VERSION "HNNBNNNYNNNNNNNNNNNNNNNNNNNNNNNNNNNNNNNNNN/4/%%%/4/'%**4NNN///"

NS_ :

BS_:

BU_: ABT_1_MIB_ab_Gen3 ABT_1_MQB BAP_Tester BT_1_MQB DU_1_MQB DU_2 DU_3 DU_4 ExBox Kombi_TT3 LSR_1 SCC1 SCC2 SDC1 SDC2 SFA TVTuner_ab_Gen3_JPN WLC_01 WLC_02 ZR_Entry ZR_High ZR_High_Korea ZR_High_TT3 ZR_MIB_OPTION_ab_Gen3 ZR_MIB_TOP_ab_Gen3 ZR_Standard

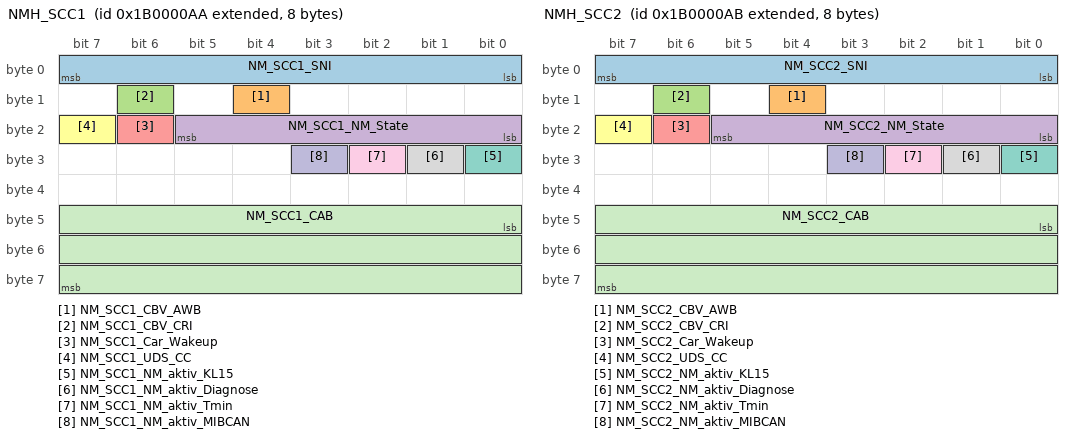
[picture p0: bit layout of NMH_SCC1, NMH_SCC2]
BO_ 2600468650 NMH_SCC1: 8 SCC1
 SG_ NM_SCC1_SNI : 0|8@1+ (1,0) [0|255] "" Vector__XXX
 SG_ NM_SCC1_CBV_AWB : 12|1@1+ (1,0) [0|1] "" Vector__XXX
 SG_ NM_SCC1_CBV_CRI : 14|1@1+ (1,0) [0|1] "" Vector__XXX
 SG_ NM_SCC1_NM_State : 16|6@1+ (1,0) [0|63] ""  ABT_1_MIB_ab_Gen3,ABT_1_MQB,BT_1_MQB,DU_1_MQB,DU_2,DU_3,DU_4,ExBox,Kombi_TT3,LSR_1,SCC1,SCC2,SDC1,SDC2,SFA,TVTuner_ab_Gen3_JPN,WLC_01,WLC_02,ZR_Entry,ZR_High,ZR_High_Korea,ZR_High_TT3,ZR_MIB_OPTION_ab_Gen3,ZR_MIB_TOP_ab_Gen3,ZR_Standard
 SG_ NM_SCC1_Car_Wakeup : 22|1@1+ (1,0) [0|1] "" Vector__XXX
 SG_ NM_SCC1_UDS_CC : 23|1@1+ (1,0) [0|1] "" Vector__XXX
 SG_ NM_SCC1_NM_aktiv_KL15 : 24|1@1+ (1,0) [0|1] "" Vector__XXX
 SG_ NM_SCC1_NM_aktiv_Diagnose : 25|1@1+ (1,0) [0|1] "" Vector__XXX
 SG_ NM_SCC1_NM_aktiv_Tmin : 26|1@1+ (1,0) [0|1] "" Vector__XXX
 SG_ NM_SCC1_NM_aktiv_MIBCAN : 27|1@1+ (1,0) [0|1] "" Vector__XXX
 SG_ NM_SCC1_CAB : 40|24@1+ (1,0) [0|16777215] "" Vector__XXX

BO_ 2600468651 NMH_SCC2: 8 SCC2
 SG_ NM_SCC2_SNI : 0|8@1+ (1,0) [0|255] "" Vector__XXX
 SG_ NM_SCC2_CBV_AWB : 12|1@1+ (1,0) [0|1] "" Vector__XXX
 SG_ NM_SCC2_CBV_CRI : 14|1@1+ (1,0) [0|1] "" Vector__XXX
 SG_ NM_SCC2_NM_State : 16|6@1+ (1,0) [0|63] ""  ABT_1_MIB_ab_Gen3,ABT_1_MQB,BT_1_MQB,DU_1_MQB,DU_2,DU_3,DU_4,ExBox,Kombi_TT3,LSR_1,SCC1,SCC2,SDC1,SDC2,SFA,TVTuner_ab_Gen3_JPN,WLC_01,WLC_02,ZR_Entry,ZR_High,ZR_High_Korea,ZR_High_TT3,ZR_MIB_OPTION_ab_Gen3,ZR_MIB_TOP_ab_Gen3,ZR_Standard
 SG_ NM_SCC2_Car_Wakeup : 22|1@1+ (1,0) [0|1] "" Vector__XXX
 SG_ NM_SCC2_UDS_CC : 23|1@1+ (1,0) [0|1] "" Vector__XXX
 SG_ NM_SCC2_NM_aktiv_KL15 : 24|1@1+ (1,0) [0|1] "" Vector__XXX
 SG_ NM_SCC2_NM_aktiv_Diagnose : 25|1@1+ (1,0) [0|1] "" Vector__XXX
 SG_ NM_SCC2_NM_aktiv_Tmin : 26|1@1+ (1,0) [0|1] "" Vector__XXX
 SG_ NM_SCC2_NM_aktiv_MIBCAN : 27|1@1+ (1,0) [0|1] "" Vector__XXX
 SG_ NM_SCC2_CAB : 40|24@1+ (1,0) [0|16777215] "" Vector__XXX

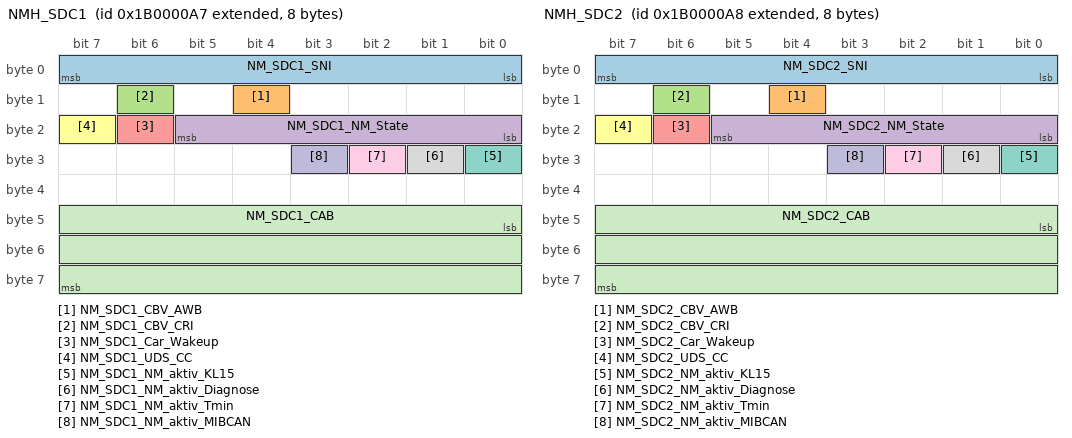
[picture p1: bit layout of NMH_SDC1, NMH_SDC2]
BO_ 2600468647 NMH_SDC1: 8 SDC1
 SG_ NM_SDC1_SNI : 0|8@1+ (1,0) [0|255] "" Vector__XXX
 SG_ NM_SDC1_CBV_AWB : 12|1@1+ (1,0) [0|1] ""  ZR_High
 SG_ NM_SDC1_CBV_CRI : 14|1@1+ (1,0) [0|1] "" Vector__XXX
 SG_ NM_SDC1_NM_State : 16|6@1+ (1,0) [0|63] ""  ABT_1_MIB_ab_Gen3,ABT_1_MQB,BT_1_MQB,DU_1_MQB,DU_2,DU_3,DU_4,ExBox,Kombi_TT3,LSR_1,SCC1,SCC2,SDC1,SDC2,SFA,TVTuner_ab_Gen3_JPN,WLC_01,WLC_02,ZR_Entry,ZR_High,ZR_High_Korea,ZR_High_TT3,ZR_MIB_OPTION_ab_Gen3,ZR_MIB_TOP_ab_Gen3,ZR_Standard
 SG_ NM_SDC1_Car_Wakeup : 22|1@1+ (1,0) [0|1] "" Vector__XXX
 SG_ NM_SDC1_UDS_CC : 23|1@1+ (1,0) [0|1] "" Vector__XXX
 SG_ NM_SDC1_NM_aktiv_KL15 : 24|1@1+ (1,0) [0|1] "" Vector__XXX
 SG_ NM_SDC1_NM_aktiv_Diagnose : 25|1@1+ (1,0) [0|1] "" Vector__XXX
 SG_ NM_SDC1_NM_aktiv_Tmin : 26|1@1+ (1,0) [0|1] "" Vector__XXX
 SG_ NM_SDC1_NM_aktiv_MIBCAN : 27|1@1+ (1,0) [0|1] "" Vector__XXX
 SG_ NM_SDC1_CAB : 40|24@1+ (1,0) [0|16777215] "" Vector__XXX

BO_ 2600468648 NMH_SDC2: 8 SDC2
 SG_ NM_SDC2_SNI : 0|8@1+ (1,0) [0|255] "" Vector__XXX
 SG_ NM_SDC2_CBV_AWB : 12|1@1+ (1,0) [0|1] ""  ZR_High
 SG_ NM_SDC2_CBV_CRI : 14|1@1+ (1,0) [0|1] "" Vector__XXX
 SG_ NM_SDC2_NM_State : 16|6@1+ (1,0) [0|63] ""  ABT_1_MIB_ab_Gen3,ABT_1_MQB,BT_1_MQB,DU_1_MQB,DU_2,DU_3,DU_4,ExBox,Kombi_TT3,LSR_1,SCC1,SCC2,SDC1,SDC2,SFA,TVTuner_ab_Gen3_JPN,WLC_01,WLC_02,ZR_Entry,ZR_High,ZR_High_Korea,ZR_High_TT3,ZR_MIB_OPTION_ab_Gen3,ZR_MIB_TOP_ab_Gen3,ZR_Standard
 SG_ NM_SDC2_Car_Wakeup : 22|1@1+ (1,0) [0|1] "" Vector__XXX
 SG_ NM_SDC2_UDS_CC : 23|1@1+ (1,0) [0|1] "" Vector__XXX
 SG_ NM_SDC2_NM_aktiv_KL15 : 24|1@1+ (1,0) [0|1] "" Vector__XXX
 SG_ NM_SDC2_NM_aktiv_Diagnose : 25|1@1+ (1,0) [0|1] "" Vector__XXX
 SG_ NM_SDC2_NM_aktiv_Tmin : 26|1@1+ (1,0) [0|1] "" Vector__XXX
 SG_ NM_SDC2_NM_aktiv_MIBCAN : 27|1@1+ (1,0) [0|1] "" Vector__XXX
 SG_ NM_SDC2_CAB : 40|24@1+ (1,0) [0|16777215] "" Vector__XXX

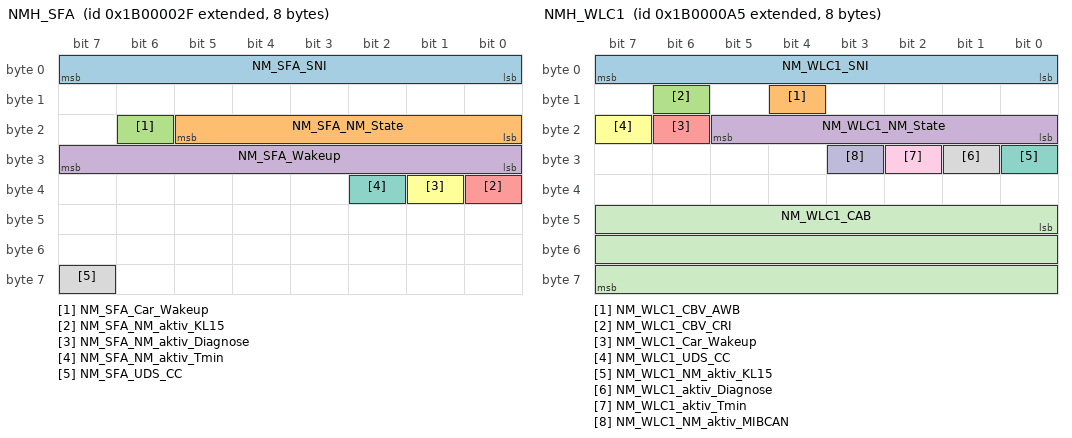
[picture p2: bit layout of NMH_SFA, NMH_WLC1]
BO_ 2600468527 NMH_SFA: 8 SFA
 SG_ NM_SFA_SNI : 0|8@1+ (1,0) [0|255] "" Vector__XXX
 SG_ NM_SFA_NM_State : 16|6@1+ (1,0) [0|63] ""  ABT_1_MIB_ab_Gen3,ABT_1_MQB,BT_1_MQB,DU_1_MQB,DU_2,DU_3,DU_4,ExBox,Kombi_TT3,LSR_1,SCC1,SCC2,SDC1,SDC2,SFA,TVTuner_ab_Gen3_JPN,WLC_01,WLC_02,ZR_Entry,ZR_High,ZR_High_Korea,ZR_High_TT3,ZR_MIB_OPTION_ab_Gen3,ZR_MIB_TOP_ab_Gen3,ZR_Standard
 SG_ NM_SFA_Car_Wakeup : 22|1@1+ (1,0) [0|1] "" Vector__XXX
 SG_ NM_SFA_Wakeup : 24|8@1+ (1,0) [0|255] "" Vector__XXX
 SG_ NM_SFA_NM_aktiv_KL15 : 32|1@1+ (1,0) [0|1] "" Vector__XXX
 SG_ NM_SFA_NM_aktiv_Diagnose : 33|1@1+ (1,0) [0|1] "" Vector__XXX
 SG_ NM_SFA_NM_aktiv_Tmin : 34|1@1+ (1,0) [0|1] "" Vector__XXX
 SG_ NM_SFA_UDS_CC : 63|1@1+ (1,0) [0|1] "" Vector__XXX

BO_ 2600468645 NMH_WLC1: 8 WLC_01
 SG_ NM_WLC1_SNI : 0|8@1+ (1,0) [0|255] "" Vector__XXX
 SG_ NM_WLC1_CBV_AWB : 12|1@1+ (1,0) [0|1] "" Vector__XXX
 SG_ NM_WLC1_CBV_CRI : 14|1@1+ (1,0) [0|1] "" Vector__XXX
 SG_ NM_WLC1_NM_State : 16|6@1+ (1,0) [0|63] ""  ABT_1_MIB_ab_Gen3,ABT_1_MQB,BT_1_MQB,DU_1_MQB,DU_2,DU_3,DU_4,ExBox,Kombi_TT3,LSR_1,SCC1,SCC2,SDC1,SDC2,SFA,TVTuner_ab_Gen3_JPN,WLC_01,WLC_02,ZR_Entry,ZR_High,ZR_High_Korea,ZR_High_TT3,ZR_MIB_OPTION_ab_Gen3,ZR_MIB_TOP_ab_Gen3,ZR_Standard
 SG_ NM_WLC1_Car_Wakeup : 22|1@1+ (1,0) [0|1] "" Vector__XXX
 SG_ NM_WLC1_UDS_CC : 23|1@1+ (1,0) [0|1] "" Vector__XXX
 SG_ NM_WLC1_NM_aktiv_KL15 : 24|1@1+ (1,0) [0|1] "" Vector__XXX
 SG_ NM_WLC1_aktiv_Diagnose : 25|1@1+ (1,0) [0|1] "" Vector__XXX
 SG_ NM_WLC1_aktiv_Tmin : 26|1@1+ (1,0) [0|1] "" Vector__XXX
 SG_ NM_WLC1_NM_aktiv_MIBCAN : 27|1@1+ (1,0) [0|1] "" Vector__XXX
 SG_ NM_WLC1_CAB : 40|24@1+ (1,0) [0|16777215] "" Vector__XXX

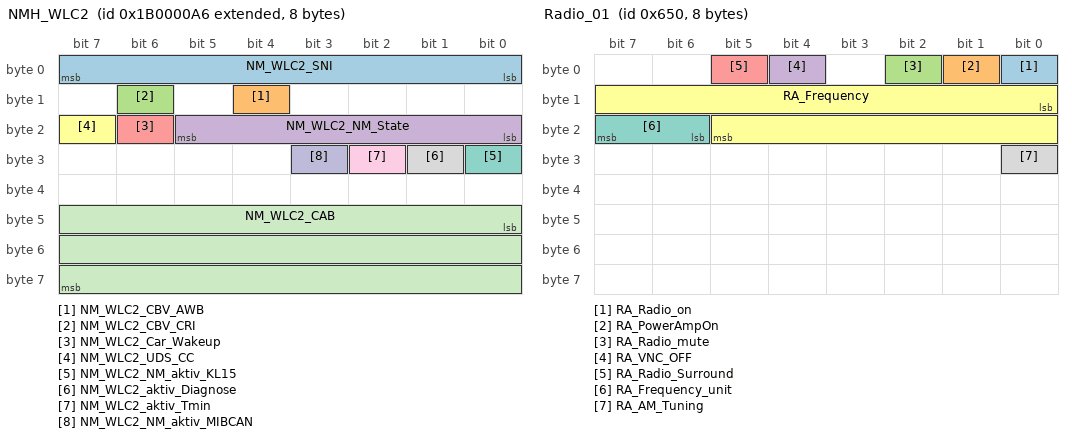
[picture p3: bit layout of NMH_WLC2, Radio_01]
BO_ 2600468646 NMH_WLC2: 8 WLC_02
 SG_ NM_WLC2_SNI : 0|8@1+ (1,0) [0|255] "" Vector__XXX
 SG_ NM_WLC2_CBV_AWB : 12|1@1+ (1,0) [0|1] "" Vector__XXX
 SG_ NM_WLC2_CBV_CRI : 14|1@1+ (1,0) [0|1] "" Vector__XXX
 SG_ NM_WLC2_NM_State : 16|6@1+ (1,0) [0|63] ""  ABT_1_MIB_ab_Gen3,ABT_1_MQB,BT_1_MQB,DU_1_MQB,DU_2,DU_3,DU_4,ExBox,Kombi_TT3,LSR_1,SCC1,SCC2,SDC1,SDC2,SFA,TVTuner_ab_Gen3_JPN,WLC_01,WLC_02,ZR_Entry,ZR_High,ZR_High_Korea,ZR_High_TT3,ZR_MIB_OPTION_ab_Gen3,ZR_MIB_TOP_ab_Gen3,ZR_Standard
 SG_ NM_WLC2_Car_Wakeup : 22|1@1+ (1,0) [0|1] "" Vector__XXX
 SG_ NM_WLC2_UDS_CC : 23|1@1+ (1,0) [0|1] "" Vector__XXX
 SG_ NM_WLC2_NM_aktiv_KL15 : 24|1@1+ (1,0) [0|1] "" Vector__XXX
 SG_ NM_WLC2_aktiv_Diagnose : 25|1@1+ (1,0) [0|1] "" Vector__XXX
 SG_ NM_WLC2_aktiv_Tmin : 26|1@1+ (1,0) [0|1] "" Vector__XXX
 SG_ NM_WLC2_NM_aktiv_MIBCAN : 27|1@1+ (1,0) [0|1] "" Vector__XXX
 SG_ NM_WLC2_CAB : 40|24@1+ (1,0) [0|16777215] "" Vector__XXX

BO_ 2549875370 OBDC_SCC1_Req: 8 ZR_High
 SG_ OBDC_SCC1_Req_Data : 0|64@1+ (1,0) [0|1.84467440737096E+019] ""  SCC1

BO_ 2550006442 OBDC_SCC1_Resp: 8 SCC1
 SG_ OBDC_SCC1_Resp_Data : 0|64@1+ (1,0) [0|1.84467440737096E+019] ""  ZR_High

BO_ 2549875371 OBDC_SCC2_Req: 8 ZR_High
 SG_ OBDC_SCC2_Req_Data : 0|64@1+ (1,0) [0|1.84467440737096E+019] ""  SCC2

BO_ 2550006443 OBDC_SCC2_Resp: 8 SCC2
 SG_ OBDC_SCC2_Resp_Data : 0|64@1+ (1,0) [0|1.84467440737096E+019] ""  ZR_High

BO_ 2549875367 OBDC_SDC1_Req: 8 ZR_High
 SG_ OBDC_SDC1_Req_Data : 0|64@1+ (1,0) [0|1.84467440737096E+019] "Unit_None"  SDC1

BO_ 2550006439 OBDC_SDC1_Resp: 8 SDC1
 SG_ OBDC_SDC1_Resp_Data : 0|64@1+ (1,0) [0|1.84467440737096E+019] "Unit_None"  ZR_High

BO_ 2549875368 OBDC_SDC2_Req: 8 ZR_High
 SG_ OBDC_SDC2_Req_Data : 0|64@1+ (1,0) [0|1.84467440737096E+019] "Unit_None"  SDC2

BO_ 2550006440 OBDC_SDC2_Resp: 8 SDC2
 SG_ OBDC_SDC2_Resp_Data : 0|64@1+ (1,0) [0|1.84467440737096E+019] "Unit_None"  ZR_High

BO_ 2549875365 OBDC_WLC1_Req: 8 ZR_High
 SG_ OBDC_WLC1_Req_Data : 0|64@1+ (1,0) [0|1.84467440737096E+019] "Unit_None"  WLC_01

BO_ 2550006437 OBDC_WLC1_Resp: 8 WLC_01
 SG_ OBDC_WLC1_Resp_Data : 0|64@1+ (1,0) [0|1.84467440737096E+019] "Unit_None"  ZR_High,ZR_High_Korea,ZR_MIB_OPTION_ab_Gen3,ZR_MIB_TOP_ab_Gen3,ZR_Standard

BO_ 2549875366 OBDC_WLC2_Req: 8 ZR_High
 SG_ OBDC_WLC2_Req_Data : 0|64@1+ (1,0) [0|1.84467440737096E+019] "Unit_None"  WLC_02

BO_ 2550006438 OBDC_WLC2_Resp: 8 WLC_02
 SG_ OBDC_WLC2_Resp_Data : 0|64@1+ (1,0) [0|1.84467440737096E+019] "Unit_None"  ZR_High,ZR_High_Korea,ZR_MIB_OPTION_ab_Gen3,ZR_MIB_TOP_ab_Gen3,ZR_Standard

BO_ 2589283656 ORU_01: 8 Vector__XXX
 SG_ ORU_Warnung : 58|2@1+ (1,0) [0|3] "" Vector__XXX
 SG_ ORU_Status : 61|3@1+ (1,0) [0|7] ""  ABT_1_MIB_ab_Gen3

BO_ 1616 Radio_01: 8 ZR_High
 SG_ RA_Radio_on : 0|1@1+ (1,0) [0|1] "" Vector__XXX
 SG_ RA_PowerAmpOn : 1|1@1+ (1,0) [0|1] "" Vector__XXX
 SG_ RA_Radio_mute : 2|1@1+ (1,0) [0|1] "" Vector__XXX
 SG_ RA_VNC_OFF : 4|1@1+ (1,0) [0|1] "" Vector__XXX
 SG_ RA_Radio_Surround : 5|1@1+ (1,0) [0|1] "" Vector__XXX
 SG_ RA_Frequency : 8|14@1+ (1,0) [0|16383] ""  BT_1_MQB,WLC_01,WLC_02
 SG_ RA_Frequency_unit : 22|2@1+ (1,0) [0|3] ""  BT_1_MQB,WLC_01,WLC_02
 SG_ RA_AM_Tuning : 24|1@1+ (1,0) [0|1] ""  BT_1_MQB,WLC_01,WLC_02

BO_ 1350 SFA_01: 8 SFA
 SG_ MMI_on_angefordert : 0|1@1+ (1,0) [0|1] ""  ZR_Standard

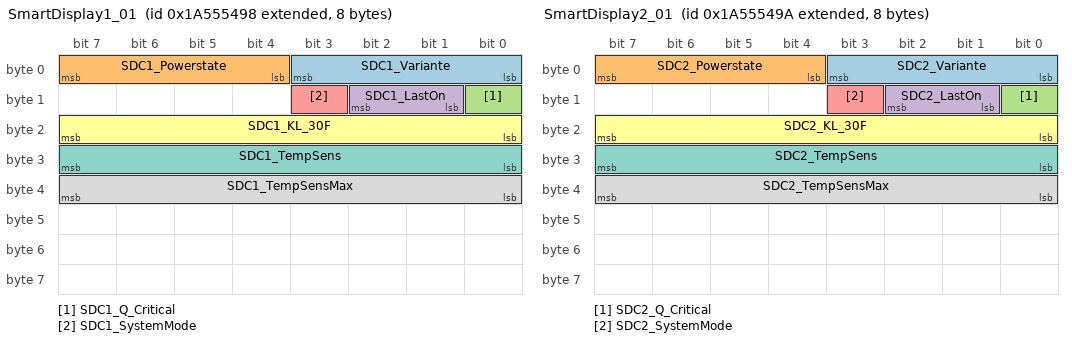
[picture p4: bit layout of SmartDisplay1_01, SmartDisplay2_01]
BO_ 2589283480 SmartDisplay1_01: 8 SDC1
 SG_ SDC1_Variante : 0|4@1+ (1,0) [0|15] ""  ZR_High
 SG_ SDC1_Powerstate : 4|4@1+ (1,0) [0|15] ""  ZR_High
 SG_ SDC1_Q_Critical : 8|1@1+ (1,0) [0|1] ""  ZR_High
 SG_ SDC1_LastOn : 9|2@1+ (1,0) [0|3] ""  ZR_High
 SG_ SDC1_SystemMode : 11|1@1+ (1,0) [0|1] ""  ZR_High
 SG_ SDC1_KL_30F : 16|8@1+ (0.1,0) [0|25.3] "Unit_Volt"  ZR_High
 SG_ SDC1_TempSens : 24|8@1+ (1,-55) [-55|127] "Unit_DegreCelsi"  ZR_High
 SG_ SDC1_TempSensMax : 32|8@1+ (1,-55) [-55|127] "Unit_DegreCelsi"  ZR_High

BO_ 2589283482 SmartDisplay2_01: 8 SDC2
 SG_ SDC2_Variante : 0|4@1+ (1,0) [0|15] ""  ZR_High
 SG_ SDC2_Powerstate : 4|4@1+ (1,0) [0|15] ""  ZR_High
 SG_ SDC2_Q_Critical : 8|1@1+ (1,0) [0|1] ""  ZR_High
 SG_ SDC2_LastOn : 9|2@1+ (1,0) [0|3] ""  ZR_High
 SG_ SDC2_SystemMode : 11|1@1+ (1,0) [0|1] ""  ZR_High
 SG_ SDC2_KL_30F : 16|8@1+ (0.1,0) [0|25.3] "Unit_Volt"  ZR_High
 SG_ SDC2_TempSens : 24|8@1+ (1,-55) [-55|127] "Unit_DegreCelsi"  ZR_High
 SG_ SDC2_TempSensMax : 32|8@1+ (1,-55) [-55|127] "Unit_DegreCelsi"  ZR_High

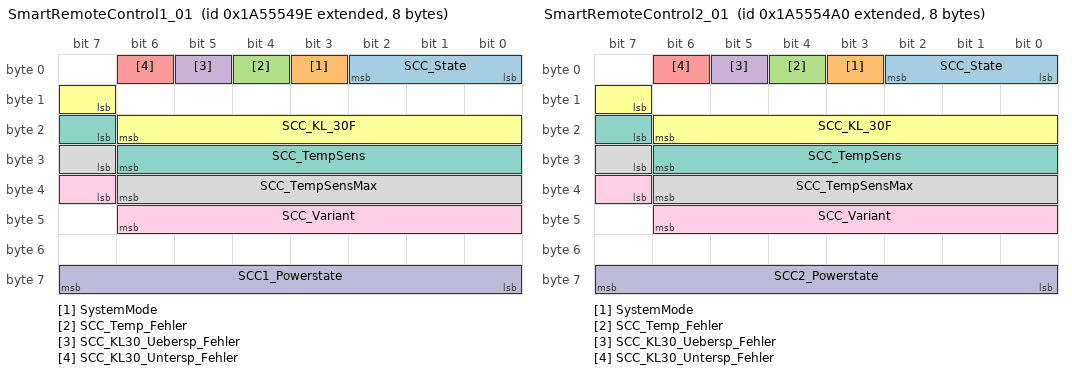
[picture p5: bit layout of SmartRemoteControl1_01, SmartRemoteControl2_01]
BO_ 2589283486 SmartRemoteControl1_01: 8 SCC1
 SG_ SCC_State : 0|3@1+ (1,0) [0|7] ""  ZR_High
 SG_ SystemMode : 3|1@1+ (1,0) [0|1] ""  ZR_High
 SG_ SCC_Temp_Fehler : 4|1@1+ (1,0) [0|1] ""  ZR_High
 SG_ SCC_KL30_Uebersp_Fehler : 5|1@1+ (1,0) [0|1] ""  ZR_High
 SG_ SCC_KL30_Untersp_Fehler : 6|1@1+ (1,0) [0|1] ""  ZR_High
 SG_ SCC_KL_30F : 15|8@1+ (0.1,0) [0|25.3] "Unit_Volt"  ZR_High
 SG_ SCC_TempSens : 23|8@1+ (1,-55) [-55|127] "Unit_DegreCelsi"  ZR_High
 SG_ SCC_TempSensMax : 31|8@1+ (1,-55) [-55|127] "Unit_DegreCelsi"  ZR_High
 SG_ SCC_Variant : 39|8@1+ (1,0) [0|253] ""  ZR_High
 SG_ SCC1_Powerstate : 56|8@1+ (1,0) [0|255] ""  ZR_High

BO_ 2589283487 SmartRemoteControl1_02: 8 SCC1
 SG_ EEPROM_Fehler : 26|1@1+ (1,0) [0|1] ""  ZR_High

BO_ 2589283488 SmartRemoteControl2_01: 8 SCC2
 SG_ SCC_State : 0|3@1+ (1,0) [0|7] ""  ZR_High
 SG_ SystemMode : 3|1@1+ (1,0) [0|1] ""  ZR_High
 SG_ SCC_Temp_Fehler : 4|1@1+ (1,0) [0|1] ""  ZR_High
 SG_ SCC_KL30_Uebersp_Fehler : 5|1@1+ (1,0) [0|1] ""  ZR_High
 SG_ SCC_KL30_Untersp_Fehler : 6|1@1+ (1,0) [0|1] ""  ZR_High
 SG_ SCC_KL_30F : 15|8@1+ (0.1,0) [0|25.3] "Unit_Volt"  ZR_High
 SG_ SCC_TempSens : 23|8@1+ (1,-55) [-55|127] "Unit_DegreCelsi"  ZR_High
 SG_ SCC_TempSensMax : 31|8@1+ (1,-55) [-55|127] "Unit_DegreCelsi"  ZR_High
 SG_ SCC_Variant : 39|8@1+ (1,0) [0|253] ""  ZR_High
 SG_ SCC2_Powerstate : 56|8@1+ (1,0) [0|255] ""  ZR_High

BO_ 2589283489 SmartRemoteControl2_02: 8 SCC2
 SG_ EEPROM_Fehler : 26|1@1+ (1,0) [0|1] ""  ZR_High

BO_ 2549876209 SWDL_ABT_1_Req: 8 ZR_High
 SG_ SWDL_ABT_1_Req_Data : 0|64@1+ (1,0) [0|1.84467440737096E+019] ""  ABT_1_MQB

BO_ 2550007281 SWDL_ABT_1_Resp: 8 ABT_1_MQB
 SG_ SWDL_ABT_1_Resp_Data : 0|64@1+ (1,0) [0|1.84467440737096E+019] ""  ZR_High,ZR_High_Korea,ZR_High_TT3,ZR_MIB_OPTION_ab_Gen3,ZR_MIB_TOP_ab_Gen3,ZR_Standard

BO_ 2549876208 SWDL_BT_1_Req: 8 ZR_Entry
 SG_ SWDL_BT_1_Req_Data : 0|64@1+ (1,0) [0|1.84467440737096E+019] ""  BT_1_MQB

BO_ 2550007280 SWDL_BT_1_Resp: 8 BT_1_MQB
 SG_ SWDL_BT_1_Resp_Data : 0|64@1+ (1,0) [0|1.84467440737096E+019] ""  ZR_Entry,ZR_High,ZR_High_Korea,ZR_High_TT3,ZR_MIB_OPTION_ab_Gen3,ZR_MIB_TOP_ab_Gen3,ZR_Standard

BO_ 2549876210 SWDL_DU_1_Req: 8 ZR_Entry
 SG_ SWDL_DU_1_Req_Data : 0|64@1+ (1,0) [0|1.84467440737096E+019] ""  DU_1_MQB

BO_ 2550007282 SWDL_DU_1_Resp: 8 DU_1_MQB
 SG_ SWDL_DU_1_Resp_Data : 0|64@1+ (1,0) [0|1.84467440737096E+019] ""  ZR_Entry,ZR_High,ZR_High_Korea,ZR_High_TT3,ZR_MIB_OPTION_ab_Gen3,ZR_MIB_TOP_ab_Gen3,ZR_Standard

BO_ 2549876213 SWDL_DU_2_Req: 8 ZR_High
 SG_ SWDL_DU_2_Req_Data : 0|64@1+ (1,0) [0|1.84467440737096E+019] ""  DU_2

BO_ 2550007285 SWDL_DU_2_Resp: 8 DU_2
 SG_ SWDL_DU_2_Resp_Data : 0|64@1+ (1,0) [0|1.84467440737096E+019] ""  ZR_High,ZR_MIB_OPTION_ab_Gen3,ZR_MIB_TOP_ab_Gen3,ZR_Standard

BO_ 2549876222 SWDL_DU_3_Req: 8 ZR_High
 SG_ SWDL_DU_3_Req_Data : 0|64@1+ (1,0) [0|1.84467440737096E+019] ""  DU_3

BO_ 2550007294 SWDL_DU_3_Resp: 8 DU_3
 SG_ SWDL_DU_3_Resp_Data : 0|64@1+ (1,0) [0|1.84467440737096E+019] ""  ZR_High,ZR_MIB_TOP_ab_Gen3

BO_ 2549876212 SWDL_DU_4_Req: 8 ZR_High
 SG_ SWDL_DU_4_Req_Data : 0|64@1+ (1,0) [0|1.84467440737096E+019] ""  DU_4

BO_ 2550007284 SWDL_DU_4_Resp: 8 DU_4
 SG_ SWDL_DU_4_Resp_Data : 0|64@1+ (1,0) [0|1.84467440737096E+019] ""  ZR_High,ZR_MIB_TOP_ab_Gen3

BO_ 2549876214 SWDL_LSR_1_Req: 8 ZR_High
 SG_ SWDL_LSR_1_Req_Data : 0|64@1+ (1,0) [0|1.84467440737096E+019] ""  LSR_1

BO_ 2550007286 SWDL_LSR_1_Resp: 8 LSR_1
 SG_ SWDL_LSR_1_Resp_Data : 0|64@1+ (1,0) [0|1.84467440737096E+019] ""  ZR_High,ZR_MIB_OPTION_ab_Gen3,ZR_MIB_TOP_ab_Gen3,ZR_Standard

BO_ 2549876138 SWDL_SCC1_Req: 8 ZR_High
 SG_ SWDL_SCC1_Req_Data : 0|64@1+ (1,0) [0|1.84467440737096E+019] ""  SCC1

BO_ 2550007210 SWDL_SCC1_Resp: 8 SCC1
 SG_ SWDL_SCC1_Resp_Data : 0|64@1+ (1,0) [0|1.84467440737096E+019] ""  ZR_High

BO_ 2549876139 SWDL_SCC2_Req: 8 ZR_High
 SG_ SWDL_SCC2_Req_Data : 0|64@1+ (1,0) [0|1.84467440737096E+019] ""  SCC2

BO_ 2550007211 SWDL_SCC2_Resp: 8 SCC2
 SG_ SWDL_SCC2_Resp_Data : 0|64@1+ (1,0) [0|1.84467440737096E+019] ""  ZR_High

BO_ 2549876135 SWDL_SDC1_Req: 8 ZR_High
 SG_ SWDL_SDC1_Req_Data : 0|64@1+ (1,0) [0|1.84467440737096E+019] ""  SDC1

BO_ 2550007207 SWDL_SDC1_Resp: 8 SDC1
 SG_ SWDL_SDC1_Resp_Data : 0|64@1+ (1,0) [0|1.84467440737096E+019] ""  ZR_High

BO_ 2549876136 SWDL_SDC2_Req: 8 ZR_High
 SG_ SWDL_SDC2_Req_Data : 0|64@1+ (1,0) [0|1.84467440737096E+019] ""  SDC2

BO_ 2550007208 SWDL_SDC2_Resp: 8 SDC2
 SG_ SWDL_SDC2_Resp_Data : 0|64@1+ (1,0) [0|1.84467440737096E+019] ""  ZR_High

BO_ 2549876133 SWDL_WLC1_Req: 8 ZR_High
 SG_ SWDL_WLC1_Req : 0|64@1+ (1,0) [0|1.84467440737096E+019] ""  WLC_01

BO_ 2550007205 SWDL_WLC1_Resp: 8 WLC_01
 SG_ SWDL_WLC1_Resp : 0|64@1+ (1,0) [0|1.84467440737096E+019] ""  ZR_High,ZR_High_Korea,ZR_MIB_OPTION_ab_Gen3,ZR_MIB_TOP_ab_Gen3,ZR_Standard

BO_ 2549876134 SWDL_WLC2_Req: 8 ZR_High
 SG_ SWDL_WLC2_Req : 0|64@1+ (1,0) [0|1.84467440737096E+019] ""  WLC_02

BO_ 2550007206 SWDL_WLC2_Resp: 8 WLC_02
 SG_ SWDL_WLC2_Resp : 0|64@1+ (1,0) [0|1.84467440737096E+019] ""  ZR_High,ZR_High_Korea,ZR_MIB_OPTION_ab_Gen3,ZR_MIB_TOP_ab_Gen3,ZR_Standard

BO_ 1413 Systeminfo_01: 8 ZR_Entry
 SG_ SI_Sammel_SG_Fehler : 0|6@1+ (1,0) [0|60] "" Vector__XXX
 SG_ SI_P_Mode_gueltig : 6|1@1+ (1,0) [0|1] "" Vector__XXX
 SG_ SI_Diagnose_Aktiv : 7|1@1+ (1,0) [0|1] "" Vector__XXX
 SG_ SI_QRS_Mode : 8|1@1+ (1,0) [0|1] ""  SCC1,SCC2,SDC1,SDC2,WLC_01,WLC_02,DU_4
 SG_ SI_T_Mode : 9|1@1+ (1,0) [0|1] ""  ABT_1_MIB_ab_Gen3,ABT_1_MQB,BT_1_MQB,DU_3,DU_4,ExBox,LSR_1,SCC1,SCC2,SDC1,SDC2,WLC_01,WLC_02
 SG_ SI_NWDF : 10|1@1+ (1,0) [0|1] ""  SCC1,SCC2,SDC1,SDC2,WLC_01,WLC_02
 SG_ SI_NWDF_gueltig : 11|1@1+ (1,0) [0|1] ""  SCC1,SCC2,SDC1,SDC2,WLC_01,WLC_02
 SG_ SI_Sammelfehler : 12|1@1+ (1,0) [0|1] "" Vector__XXX
 SG_ GW_KD_Fehler : 13|1@1+ (1,0) [0|1] "" Vector__XXX
 SG_ SI_T_Schutz : 14|1@1+ (1,0) [0|1] ""  SCC1,SCC2,SDC1,SDC2
 SG_ SI_P_Mode : 15|1@1+ (1,0) [0|1] "" Vector__XXX
 SG_ SI_BUS_01 : 16|1@1+ (1,0) [0|1] "" Vector__XXX
 SG_ SI_BUS_02 : 17|1@1+ (1,0) [0|1] "" Vector__XXX
 SG_ SI_BUS_03 : 18|1@1+ (1,0) [0|1] ""  ABT_1_MIB_ab_Gen3,ABT_1_MQB,BT_1_MQB,DU_1_MQB,DU_2,DU_3,DU_4,ExBox,LSR_1,SDC1,SDC2
 SG_ SI_BUS_04 : 19|1@1+ (1,0) [0|1] "" Vector__XXX
 SG_ SI_BUS_05 : 20|1@1+ (1,0) [0|1] "" Vector__XXX
 SG_ SI_BUS_06 : 21|1@1+ (1,0) [0|1] "" Vector__XXX
 SG_ SI_BUS_07 : 22|1@1+ (1,0) [0|1] "" Vector__XXX
 SG_ SI_BUS_08 : 23|1@1+ (1,0) [0|1] "" Vector__XXX
 SG_ SI_BUS_09 : 24|1@1+ (1,0) [0|1] "" Vector__XXX
 SG_ SI_BUS_10 : 25|1@1+ (1,0) [0|1] "" Vector__XXX
 SG_ SI_BUS_11 : 26|1@1+ (1,0) [0|1] "" Vector__XXX
 SG_ SI_BUS_12 : 27|1@1+ (1,0) [0|1] "" Vector__XXX
 SG_ SI_BUS_13 : 28|1@1+ (1,0) [0|1] "" Vector__XXX
 SG_ SI_BUS_14 : 29|1@1+ (1,0) [0|1] "" Vector__XXX
 SG_ SI_BUS_15 : 30|1@1+ (1,0) [0|1] "" Vector__XXX
 SG_ SI_Bus_Identifikation : 32|8@1+ (1,0) [0|255] "" Vector__XXX

BO_ 1716 VIN_01: 8 ZR_Entry
 SG_ VIN_01_MUX M : 0|2@1+ (1,0) [0|3] ""  WLC_01,WLC_02,SCC1,SCC2,SDC1,SDC2
 SG_ KS_Geheimnis_1 m0 : 8|8@1+ (1,0) [0|255] "" Vector__XXX
 SG_ VIN_4 m1 : 8|8@1+ (1,0) [0|255] ""  WLC_01,WLC_02,SCC1,SCC2,SDC1,SDC2
 SG_ VIN_11 m2 : 8|8@1+ (1,0) [0|255] ""  WLC_01,WLC_02,SCC1,SCC2,SDC1,SDC2
 SG_ KS_Geheimnis_2 m0 : 16|8@1+ (1,0) [0|255] "" Vector__XXX
 SG_ VIN_5 m1 : 16|8@1+ (1,0) [0|255] ""  WLC_01,WLC_02,SCC1,SCC2,SDC1,SDC2
 SG_ VIN_12 m2 : 16|8@1+ (1,0) [0|255] ""  WLC_01,WLC_02,SCC1,SCC2,SDC1,SDC2
 SG_ KS_Geheimnis_3 m0 : 24|8@1+ (1,0) [0|255] "" Vector__XXX
 SG_ VIN_6 m1 : 24|8@1+ (1,0) [0|255] ""  WLC_01,WLC_02,SCC1,SCC2,SDC1,SDC2
 SG_ VIN_13 m2 : 24|8@1+ (1,0) [0|255] ""  WLC_01,WLC_02,SCC1,SCC2,SDC1,SDC2
 SG_ KS_Geheimnis_4 m0 : 32|8@1+ (1,0) [0|255] "" Vector__XXX
 SG_ VIN_7 m1 : 32|8@1+ (1,0) [0|255] ""  WLC_01,WLC_02,SCC1,SCC2,SDC1,SDC2
 SG_ VIN_14 m2 : 32|8@1+ (1,0) [0|255] ""  WLC_01,WLC_02,SCC1,SCC2,SDC1,SDC2
 SG_ VIN_1 m0 : 40|8@1+ (1,0) [0|255] ""  WLC_01,WLC_02,SCC1,SCC2,SDC1,SDC2
 SG_ VIN_8 m1 : 40|8@1+ (1,0) [0|255] ""  WLC_01,WLC_02,SCC1,SCC2,SDC1,SDC2
 SG_ VIN_15 m2 : 40|8@1+ (1,0) [0|255] ""  WLC_01,WLC_02,SCC1,SCC2,SDC1,SDC2
 SG_ VIN_2 m0 : 48|8@1+ (1,0) [0|255] ""  WLC_01,WLC_02,SCC1,SCC2,SDC1,SDC2
 SG_ VIN_9 m1 : 48|8@1+ (1,0) [0|255] ""  WLC_01,WLC_02,SCC1,SCC2,SDC1,SDC2
 SG_ VIN_16 m2 : 48|8@1+ (1,0) [0|255] ""  WLC_01,WLC_02,SCC1,SCC2,SDC1,SDC2
 SG_ VIN_3 m0 : 56|8@1+ (1,0) [0|255] ""  WLC_01,WLC_02,SCC1,SCC2,SDC1,SDC2
 SG_ VIN_10 m1 : 56|8@1+ (1,0) [0|255] ""  WLC_01,WLC_02,SCC1,SCC2,SDC1,SDC2
 SG_ VIN_17 m2 : 56|8@1+ (1,0) [0|255] ""  WLC_01,WLC_02,SCC1,SCC2,SDC1,SDC2

BO_ 916 WBA_03: 8 ZR_High
 SG_ WBA_03_CRC : 0|8@1+ (1,0) [0|255] "" Vector__XXX
 SG_ WBA_03_BZ : 8|4@1+ (1,0) [0|15] "" Vector__XXX
 SG_ WBA_Fahrstufe_02 : 12|4@1+ (1,0) [0|15] ""  BT_1_MQB
 SG_ WBA_ZielFahrstufe : 16|4@1+ (1,0) [0|15] "" Vector__XXX
 SG_ WBA_GE_Warnung_02 : 20|4@1+ (1,0) [0|15] "" Vector__XXX
 SG_ WBA_eing_Gang_02 : 24|4@1+ (1,0) [0|15] "" Vector__XXX
 SG_ WBA_GE_Texte : 28|3@1+ (1,0) [0|7] "" Vector__XXX
 SG_ WBA_Segeln_aktiv : 31|1@1+ (1,0) [0|1] "" Vector__XXX
 SG_ WBA_Schaltschema : 32|5@1+ (1,0) [0|31] "" Vector__XXX
 SG_ WBA_GE_Zusatzwarnungen : 37|3@1+ (1,0) [0|7] "" Vector__XXX
 SG_ GE_Sollgang : 40|4@1+ (1,0) [0|15] "" Vector__XXX
 SG_ GE_Tipschaltempf_verfuegbar : 44|1@1+ (1,0) [0|1] "" Vector__XXX
 SG_ WBA_GE_Texte_02 : 45|3@1+ (1,0) [0|7] "" Vector__XXX
 SG_ WBA_Blinken : 54|1@1+ (1,0) [0|1] "" Vector__XXX
 SG_ GE_Wiederstart_Anz_Std : 55|1@1+ (1,0) [0|1] "" Vector__XXX
 SG_ GE_Stoppverbot_Anz_01 : 56|1@1+ (1,0) [0|1] "" Vector__XXX
 SG_ GE_Stoppverbot_Anz_02 : 57|1@1+ (1,0) [0|1] "" Vector__XXX
 SG_ GE_Stoppverbot_Anz_03 : 58|1@1+ (1,0) [0|1] "" Vector__XXX
 SG_ GE_Stoppverbot_Anz_04 : 59|1@1+ (1,0) [0|1] "" Vector__XXX
 SG_ GE_Stoppverbot_Anz_05 : 60|1@1+ (1,0) [0|1] "" Vector__XXX
 SG_ GE_Stoppverbot_Anz_06 : 61|1@1+ (1,0) [0|1] "" Vector__XXX
 SG_ GE_Stoppverbot_Anz_07 : 62|1@1+ (1,0) [0|1] "" Vector__XXX
 SG_ GE_Stoppverbot_Anz_Std : 63|1@1+ (1,0) [0|1] "" Vector__XXX

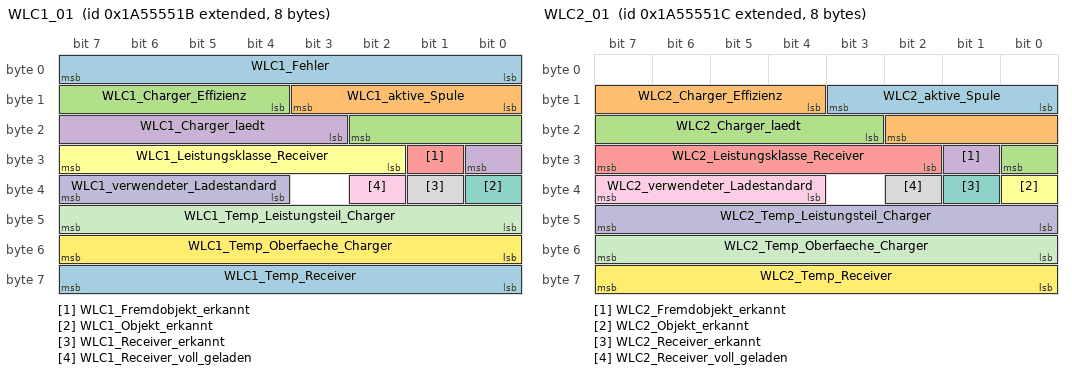
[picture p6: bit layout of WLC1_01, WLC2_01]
BO_ 2589283611 WLC1_01: 8 WLC_01
 SG_ WLC1_Fehler : 0|8@1+ (1,0) [0|255] ""  ZR_MIB_TOP_ab_Gen3
 SG_ WLC1_aktive_Spule : 8|4@1+ (1,0) [0|10] ""  ZR_High,ZR_High_Korea,ZR_MIB_OPTION_ab_Gen3,ZR_MIB_TOP_ab_Gen3,ZR_Standard
 SG_ WLC1_Charger_Effizienz : 12|7@1+ (1,0) [0|100] "Unit_PerCent"  ZR_High,ZR_High_Korea,ZR_MIB_OPTION_ab_Gen3,ZR_MIB_TOP_ab_Gen3,ZR_Standard
 SG_ WLC1_Charger_laedt : 19|6@1+ (0.1,0) [0|5] "Unit_Watt"  ZR_High,ZR_High_Korea,ZR_MIB_OPTION_ab_Gen3,ZR_MIB_TOP_ab_Gen3,ZR_Standard
 SG_ WLC1_Fremdobjekt_erkannt : 25|1@1+ (1,0) [0|1] ""  ZR_High,ZR_High_Korea,ZR_MIB_OPTION_ab_Gen3,ZR_MIB_TOP_ab_Gen3,ZR_Standard
 SG_ WLC1_Leistungsklasse_Receiver : 26|6@1+ (0.1,0) [0|5] "Unit_Watt"  ZR_High,ZR_High_Korea,ZR_MIB_OPTION_ab_Gen3,ZR_MIB_TOP_ab_Gen3,ZR_Standard
 SG_ WLC1_Objekt_erkannt : 32|1@1+ (1,0) [0|1] ""  ZR_High,ZR_High_Korea,ZR_MIB_OPTION_ab_Gen3,ZR_MIB_TOP_ab_Gen3,ZR_Standard
 SG_ WLC1_Receiver_erkannt : 33|1@1+ (1,0) [0|1] ""  ZR_High,ZR_High_Korea,ZR_MIB_OPTION_ab_Gen3,ZR_MIB_TOP_ab_Gen3,ZR_Standard
 SG_ WLC1_Receiver_voll_geladen : 34|1@1+ (1,0) [0|1] ""  ZR_High,ZR_High_Korea,ZR_MIB_OPTION_ab_Gen3,ZR_MIB_TOP_ab_Gen3,ZR_Standard
 SG_ WLC1_verwendeter_Ladestandard : 36|4@1+ (1,0) [0|15] ""  ZR_High,ZR_High_Korea,ZR_MIB_OPTION_ab_Gen3,ZR_MIB_TOP_ab_Gen3,ZR_Standard
 SG_ WLC1_Temp_Leistungsteil_Charger : 40|8@1+ (1,-58) [-58|120] "Unit_DegreCelsi"  ZR_High,ZR_High_Korea,ZR_MIB_OPTION_ab_Gen3,ZR_MIB_TOP_ab_Gen3,ZR_Standard
 SG_ WLC1_Temp_Oberfaeche_Charger : 48|8@1+ (1,-58) [-58|120] "Unit_DegreCelsi"  ZR_High,ZR_High_Korea,ZR_MIB_OPTION_ab_Gen3,ZR_MIB_TOP_ab_Gen3,ZR_Standard
 SG_ WLC1_Temp_Receiver : 56|8@1+ (1,-58) [-58|120] "Unit_DegreCelsi"  ZR_High,ZR_High_Korea,ZR_MIB_OPTION_ab_Gen3,ZR_MIB_TOP_ab_Gen3,ZR_Standard

BO_ 2583733509 WLC1_SWDL_Req: 8 WLC_01
 SG_ WLC1_SWDL_Req : 0|64@1+ (1,0) [0|1.84467440737096E+019] ""  ZR_High,ZR_High_Korea,ZR_MIB_OPTION_ab_Gen3,ZR_MIB_TOP_ab_Gen3,ZR_Standard

BO_ 2583864581 WLC1_SWDL_Resp: 8 ZR_High
 SG_ WLC1_SWDL_Resp : 0|64@1+ (1,0) [0|1.84467440737096E+019] ""  WLC_01

BO_ 2589283612 WLC2_01: 8 WLC_02
 SG_ WLC2_aktive_Spule : 8|4@1+ (1,0) [0|10] ""  ZR_High,ZR_High_Korea,ZR_MIB_OPTION_ab_Gen3,ZR_MIB_TOP_ab_Gen3,ZR_Standard
 SG_ WLC2_Charger_Effizienz : 12|7@1+ (1,0) [0|100] "Unit_PerCent"  ZR_High,ZR_High_Korea,ZR_MIB_OPTION_ab_Gen3,ZR_MIB_TOP_ab_Gen3,ZR_Standard
 SG_ WLC2_Charger_laedt : 19|6@1+ (0.1,0) [0|5] "Unit_Watt"  ZR_High,ZR_High_Korea,ZR_MIB_OPTION_ab_Gen3,ZR_MIB_TOP_ab_Gen3,ZR_Standard
 SG_ WLC2_Fremdobjekt_erkannt : 25|1@1+ (1,0) [0|1] ""  ZR_High,ZR_High_Korea,ZR_MIB_OPTION_ab_Gen3,ZR_MIB_TOP_ab_Gen3,ZR_Standard
 SG_ WLC2_Leistungsklasse_Receiver : 26|6@1+ (0.1,0) [0|5] "Unit_Watt"  ZR_High,ZR_High_Korea,ZR_MIB_OPTION_ab_Gen3,ZR_MIB_TOP_ab_Gen3,ZR_Standard
 SG_ WLC2_Objekt_erkannt : 32|1@1+ (1,0) [0|1] ""  ZR_High,ZR_High_Korea,ZR_MIB_OPTION_ab_Gen3,ZR_MIB_TOP_ab_Gen3,ZR_Standard
 SG_ WLC2_Receiver_erkannt : 33|1@1+ (1,0) [0|1] ""  ZR_High,ZR_High_Korea,ZR_MIB_OPTION_ab_Gen3,ZR_MIB_TOP_ab_Gen3,ZR_Standard
 SG_ WLC2_Receiver_voll_geladen : 34|1@1+ (1,0) [0|1] ""  ZR_High,ZR_High_Korea,ZR_MIB_OPTION_ab_Gen3,ZR_MIB_TOP_ab_Gen3,ZR_Standard
 SG_ WLC2_verwendeter_Ladestandard : 36|4@1+ (1,0) [0|15] ""  ZR_High,ZR_High_Korea,ZR_MIB_OPTION_ab_Gen3,ZR_MIB_TOP_ab_Gen3,ZR_Standard
 SG_ WLC2_Temp_Leistungsteil_Charger : 40|8@1+ (1,-58) [-58|120] "Unit_DegreCelsi"  ZR_High,ZR_High_Korea,ZR_MIB_OPTION_ab_Gen3,ZR_MIB_TOP_ab_Gen3,ZR_Standard
 SG_ WLC2_Temp_Oberfaeche_Charger : 48|8@1+ (1,-58) [-58|120] "Unit_DegreCelsi"  ZR_High,ZR_High_Korea,ZR_MIB_OPTION_ab_Gen3,ZR_MIB_TOP_ab_Gen3,ZR_Standard
 SG_ WLC2_Temp_Receiver : 56|8@1+ (1,-58) [-58|120] "Unit_DegreCelsi"  ZR_High,ZR_High_Korea,ZR_MIB_OPTION_ab_Gen3,ZR_MIB_TOP_ab_Gen3,ZR_Standard

BO_ 2583733765 WLC2_SWDL_Req: 8 WLC_02
 SG_ WLC2_SWDL_Req : 0|64@1+ (1,0) [0|1.84467440737096E+019] ""  ZR_High,ZR_High_Korea,ZR_MIB_OPTION_ab_Gen3,ZR_MIB_TOP_ab_Gen3,ZR_Standard

BO_ 2583864837 WLC2_SWDL_Resp: 8 ZR_Standard
 SG_ WLC2_SWDL_Resp : 0|64@1+ (1,0) [0|1.84467440737096E+019] ""  WLC_02

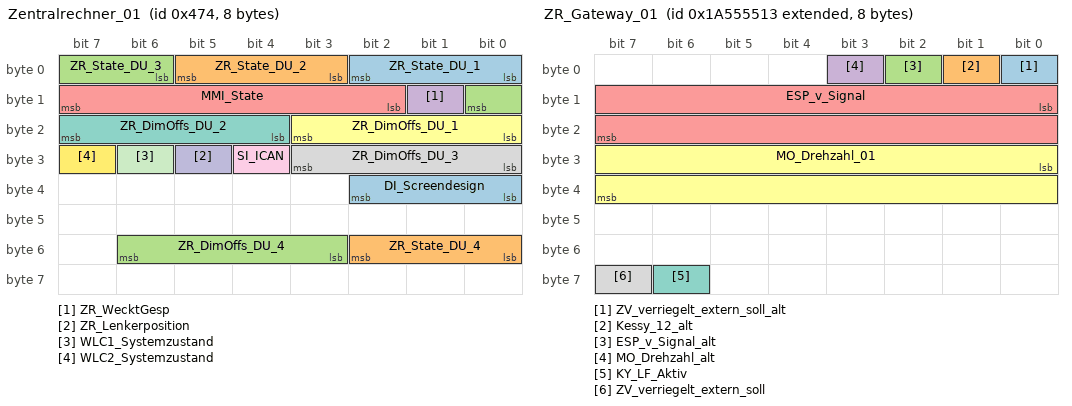
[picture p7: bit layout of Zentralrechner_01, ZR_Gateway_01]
BO_ 1140 Zentralrechner_01: 8 ZR_Entry
 SG_ ZR_State_DU_1 : 0|3@1+ (1,0) [0|7] ""  ABT_1_MIB_ab_Gen3,ABT_1_MQB,BT_1_MQB,DU_1_MQB
 SG_ ZR_State_DU_2 : 3|3@1+ (1,0) [0|7] ""  DU_2
 SG_ ZR_State_DU_3 : 6|3@1+ (1,0) [0|7] ""  DU_3
 SG_ ZR_WecktGesp : 9|1@1+ (1,0) [0|1] ""  ABT_1_MIB_ab_Gen3,ABT_1_MQB,BT_1_MQB,DU_1_MQB,DU_2,DU_3,DU_4,LSR_1
 SG_ MMI_State : 10|6@1+ (1,0) [0|63] ""  WLC_02,ABT_1_MIB_ab_Gen3,ABT_1_MQB,BT_1_MQB,DU_3,DU_4,ExBox,Kombi_TT3,SCC1,SCC2,SDC1,SDC2,SFA,WLC_01
 SG_ ZR_DimOffs_DU_1 : 16|4@1+ (1,-5) [-5|5] "Unit_None"  ABT_1_MIB_ab_Gen3,ABT_1_MQB,DU_1_MQB
 SG_ ZR_DimOffs_DU_2 : 20|4@1+ (1,-5) [-5|5] "Unit_None"  DU_2
 SG_ ZR_DimOffs_DU_3 : 24|4@1+ (1,-5) [-5|5] "Unit_None"  DU_3
 SG_ SI_ICAN : 28|1@1+ (1,0) [0|1] ""  ABT_1_MIB_ab_Gen3,ABT_1_MQB,BT_1_MQB,DU_1_MQB,DU_2,DU_3,DU_4,ExBox,LSR_1,SCC1,SCC2,SDC1,SDC2
 SG_ ZR_Lenkerposition : 29|1@1+ (1,0) [0|1] ""  ABT_1_MIB_ab_Gen3,ABT_1_MQB,BT_1_MQB,DU_3
 SG_ WLC1_Systemzustand : 30|1@1+ (1,0) [0|1] ""  WLC_01
 SG_ WLC2_Systemzustand : 31|1@1+ (1,0) [0|1] ""  WLC_02
 SG_ DI_Screendesign : 32|3@1+ (1,0) [0|7] "" Vector__XXX
 SG_ ZR_State_DU_4 : 48|3@1+ (1,0) [0|7] ""  DU_4
 SG_ ZR_DimOffs_DU_4 : 51|4@1+ (1,-5) [-5|5] "Unit_None"  DU_4

BO_ 2589283603 ZR_Gateway_01: 8 ZR_Entry
 SG_ ZV_verriegelt_extern_soll_alt : 0|1@1+ (1,0) [0|1] ""  SCC1,SCC2,SDC1,SDC2
 SG_ Kessy_12_alt : 1|1@1+ (1,0) [0|1] ""  WLC_01,WLC_02
 SG_ ESP_v_Signal_alt : 2|1@1+ (1,0) [0|1] ""  WLC_01,WLC_02,SCC1,SCC2,SDC1,SDC2
 SG_ MO_Drehzahl_alt : 3|1@1+ (1,0) [0|1] ""  WLC_01,WLC_02,SCC1,SCC2,SDC1,SDC2
 SG_ ESP_v_Signal : 8|16@1+ (0.01,0) [0|655.32] "Unit_KiloMeterPerHour"  WLC_02,SCC1,SCC2,SDC1,SDC2,WLC_01
 SG_ MO_Drehzahl_01 : 24|16@1+ (0.25,0) [0|16383] "Unit_MinutInver"  WLC_01,WLC_02,SCC1,SCC2,SDC1,SDC2
 SG_ KY_LF_Aktiv : 62|1@1+ (1,0) [0|1] ""  WLC_01,WLC_02
 SG_ ZV_verriegelt_extern_soll : 63|1@1+ (1,0) [0|1] ""  SCC1,SCC2,SDC1,SDC2

BO_TX_BU_ 2549875365 : ZR_High,ZR_High_Korea,ZR_MIB_OPTION_ab_Gen3,ZR_MIB_TOP_ab_Gen3,ZR_Standard;
BO_TX_BU_ 2549875366 : ZR_High,ZR_High_Korea,ZR_MIB_OPTION_ab_Gen3,ZR_MIB_TOP_ab_Gen3,ZR_Standard;
BO_TX_BU_ 1616 : ZR_High,ZR_High_Korea,ZR_MIB_OPTION_ab_Gen3,ZR_MIB_TOP_ab_Gen3,ZR_Standard;
BO_TX_BU_ 2549876209 : ZR_High,ZR_High_Korea,ZR_High_TT3,ZR_MIB_OPTION_ab_Gen3,ZR_MIB_TOP_ab_Gen3,ZR_Standard;
BO_TX_BU_ 2549876208 : ZR_Entry,ZR_High,ZR_High_Korea,ZR_High_TT3,ZR_MIB_OPTION_ab_Gen3,ZR_MIB_TOP_ab_Gen3,ZR_Standard;
BO_TX_BU_ 2549876210 : ZR_Entry,ZR_High,ZR_High_Korea,ZR_High_TT3,ZR_MIB_OPTION_ab_Gen3,ZR_MIB_TOP_ab_Gen3,ZR_Standard;
BO_TX_BU_ 2549876213 : ZR_High,ZR_MIB_OPTION_ab_Gen3,ZR_MIB_TOP_ab_Gen3,ZR_Standard;
BO_TX_BU_ 2549876222 : ZR_High,ZR_MIB_TOP_ab_Gen3;
BO_TX_BU_ 2549876214 : ZR_High,ZR_MIB_OPTION_ab_Gen3,ZR_MIB_TOP_ab_Gen3,ZR_Standard;
BO_TX_BU_ 2549876133 : ZR_High,ZR_High_Korea,ZR_MIB_OPTION_ab_Gen3,ZR_MIB_TOP_ab_Gen3,ZR_Standard;
BO_TX_BU_ 2549876134 : ZR_High,ZR_High_Korea,ZR_MIB_OPTION_ab_Gen3,ZR_MIB_TOP_ab_Gen3,ZR_Standard;
BO_TX_BU_ 1413 : ZR_Entry,ZR_High,ZR_High_Korea,ZR_High_TT3,ZR_MIB_OPTION_ab_Gen3,ZR_MIB_TOP_ab_Gen3,ZR_Standard;
BO_TX_BU_ 1716 : ZR_Entry,ZR_High,ZR_High_Korea,ZR_High_TT3,ZR_MIB_OPTION_ab_Gen3,ZR_MIB_TOP_ab_Gen3,ZR_Standard;
BO_TX_BU_ 916 : ZR_High,ZR_MIB_OPTION_ab_Gen3,ZR_MIB_TOP_ab_Gen3;
BO_TX_BU_ 2583864581 : ZR_High,ZR_High_Korea,ZR_MIB_OPTION_ab_Gen3,ZR_MIB_TOP_ab_Gen3,ZR_Standard;
BO_TX_BU_ 2583864837 : ZR_High,ZR_High_Korea,ZR_MIB_OPTION_ab_Gen3,ZR_MIB_TOP_ab_Gen3,ZR_Standard;
BO_TX_BU_ 1140 : ZR_Entry,ZR_High,ZR_High_Korea,ZR_High_TT3,ZR_MIB_OPTION_ab_Gen3,ZR_MIB_TOP_ab_Gen3,ZR_Standard;
BO_TX_BU_ 2589283603 : ZR_Entry,ZR_High,ZR_High_Korea,ZR_High_TT3,ZR_MIB_OPTION_ab_Gen3,ZR_MIB_TOP_ab_Gen3,ZR_Standard;
CM_ SG_ 2600468650 NM_SCC1_SNI "Source Node-Identifier (SNI) identifiziert den Sender der NM-Botschaft (Knotenadresse) eindeutig im Fahrzeug";
CM_ SG_ 2600468650 NM_SCC1_CBV_AWB "Das Signal ist zu setzen, wenn das SG aktiv den Bus geweckt hat";
CM_ SG_ 2600468650 NM_SCC1_CBV_CRI "Das Signal ist dauerhaft gesetzt, wenn das NM-Layout dem neuen NM-Layout für Teilnetzbetrieb entspricht";
CM_ SG_ 2600468650 NM_SCC1_NM_State "1 = Zustand Repeat Message (<-- Bus-Sleep Mode)
2 = Zustand Repeat Message (<-- Prepare Bus-Sleep Mode)
4 = Zustand Normal Operation (<-- Repeat Message)
8 = Zustand Normal Operation (<-- Ready Sleep)";
CM_ SG_ 2600468650 NM_SCC1_Car_Wakeup "Car Wakeup (Gateway wertet aus)";
CM_ SG_ 2600468650 NM_SCC1_UDS_CC "Funktionseinschränkung aufgrund aktivem UDS-Communication Control; siehe VW80124";
CM_ SG_ 2600468650 NM_SCC1_NM_aktiv_KL15 "Steuergerät hat KL15-EIN erkannt";
CM_ SG_ 2600468650 NM_SCC1_NM_aktiv_Diagnose "Diagnose befindet sich nach VW80124 in einer NonDefaultDiagnostic-Session, z.B. ExtendedDiagnostic-Session";
CM_ SG_ 2600468650 NM_SCC1_NM_aktiv_Tmin "Mindestaktivzeit ist noch nicht abgelaufen (bei jedem Weckereignis wird die Mindestaktivzeit neu gestartet)";
CM_ SG_ 2600468650 NM_SCC1_NM_aktiv_MIBCAN "MIB-CAN länger als Mindestaktivzeit aktiv";
CM_ SG_ 2600468651 NM_SCC2_SNI "Source Node-Identifier (SNI) identifiziert den Sender der NM-Botschaft (Knotenadresse) eindeutig im Fahrzeug";
CM_ SG_ 2600468651 NM_SCC2_CBV_AWB "Das Signal ist zu setzen, wenn das SG aktiv den Bus geweckt hat";
CM_ SG_ 2600468651 NM_SCC2_CBV_CRI "Das Signal ist dauerhaft gesetzt, wenn das NM-Layout dem neuen NM-Layout für Teilnetzbetrieb entspricht";
CM_ SG_ 2600468651 NM_SCC2_NM_State "1 = Zustand Repeat Message (<-- Bus-Sleep Mode)
2 = Zustand Repeat Message (<-- Prepare Bus-Sleep Mode)
4 = Zustand Normal Operation (<-- Repeat Message)
8 = Zustand Normal Operation (<-- Ready Sleep)";
CM_ SG_ 2600468651 NM_SCC2_Car_Wakeup "Car Wakeup (Gateway wertet aus)";
CM_ SG_ 2600468651 NM_SCC2_UDS_CC "Funktionseinschränkung aufgrund aktivem UDS-Communication Control; siehe VW80124";
CM_ SG_ 2600468651 NM_SCC2_NM_aktiv_KL15 "Steuergerät hat KL15-EIN erkannt";
CM_ SG_ 2600468651 NM_SCC2_NM_aktiv_Diagnose "Diagnose befindet sich nach VW80124 in einer NonDefaultDiagnostic-Session, z.B. ExtendedDiagnostic-Session";
CM_ SG_ 2600468651 NM_SCC2_NM_aktiv_Tmin "Mindestaktivzeit ist noch nicht abgelaufen (bei jedem Weckereignis wird die Mindestaktivzeit neu gestartet)";
CM_ SG_ 2600468651 NM_SCC2_NM_aktiv_MIBCAN "MIB-CAN länger als Mindestaktivzeit aktiv";
CM_ SG_ 2600468647 NM_SDC1_SNI "Source Node-Identifier (SNI) identifiziert den Sender der NM-Botschaft (Knotenadresse) eindeutig im Fahrzeug";
CM_ SG_ 2600468647 NM_SDC1_CBV_AWB "Das Signal ist zu setzen, wenn das SG aktiv den Bus geweckt hat";
CM_ SG_ 2600468647 NM_SDC1_CBV_CRI "Das Signal ist dauerhaft gesetzt, wenn das NM-Layout dem neuen NM-Layout für Teilnetzbetrieb entspricht";
CM_ SG_ 2600468647 NM_SDC1_NM_State "1 = Zustand Repeat Message (<-- Bus-Sleep Mode)
2 = Zustand Repeat Message (<-- Prepare Bus-Sleep Mode)
4 = Zustand Normal Operation (<-- Repeat Message)
8 = Zustand Normal Operation (<-- Ready Sleep)";
CM_ SG_ 2600468647 NM_SDC1_Car_Wakeup "Car Wakeup (Gateway wertet aus)";
CM_ SG_ 2600468647 NM_SDC1_UDS_CC "Funktionseinschränkung aufgrund aktivem UDS-Communication Control; siehe VW80124";
CM_ SG_ 2600468647 NM_SDC1_NM_aktiv_KL15 "Steuergerät hat KL15-EIN erkannt";
CM_ SG_ 2600468647 NM_SDC1_NM_aktiv_Diagnose "Diagnose befindet sich nach VW80124 in einer NonDefaultDiagnostic-Session, z.B. ExtendedDiagnostic-Session";
CM_ SG_ 2600468647 NM_SDC1_NM_aktiv_Tmin "Mindestaktivzeit ist noch nicht abgelaufen (bei jedem Weckereignis wird die Mindestaktivzeit neu gestartet)";
CM_ SG_ 2600468647 NM_SDC1_NM_aktiv_MIBCAN "MIB-CAN länger als Mindestaktivzeit aktiv";
CM_ SG_ 2600468648 NM_SDC2_SNI "Source Node-Identifier (SNI) identifiziert den Sender der NM-Botschaft (Knotenadresse) eindeutig im Fahrzeug";
CM_ SG_ 2600468648 NM_SDC2_CBV_AWB "Das Signal ist zu setzen, wenn das SG aktiv den Bus geweckt hat";
CM_ SG_ 2600468648 NM_SDC2_CBV_CRI "Das Signal ist dauerhaft gesetzt, wenn das NM-Layout dem neuen NM-Layout für Teilnetzbetrieb entspricht";
CM_ SG_ 2600468648 NM_SDC2_NM_State "1 = Zustand Repeat Message (<-- Bus-Sleep Mode)
2 = Zustand Repeat Message (<-- Prepare Bus-Sleep Mode)
4 = Zustand Normal Operation (<-- Repeat Message)
8 = Zustand Normal Operation (<-- Ready Sleep)";
CM_ SG_ 2600468648 NM_SDC2_Car_Wakeup "Car Wakeup (Gateway wertet aus)";
CM_ SG_ 2600468648 NM_SDC2_UDS_CC "Funktionseinschränkung aufgrund aktivem UDS-Communication Control; siehe VW80124";
CM_ SG_ 2600468648 NM_SDC2_NM_aktiv_KL15 "Steuergerät hat KL15-EIN erkannt";
CM_ SG_ 2600468648 NM_SDC2_NM_aktiv_Diagnose "Diagnose befindet sich nach VW80124 in einer NonDefaultDiagnostic-Session, z.B. ExtendedDiagnostic-Session";
CM_ SG_ 2600468648 NM_SDC2_NM_aktiv_Tmin "Mindestaktivzeit ist noch nicht abgelaufen (bei jedem Weckereignis wird die Mindestaktivzeit neu gestartet)";
CM_ SG_ 2600468648 NM_SDC2_NM_aktiv_MIBCAN "MIB-CAN länger als Mindestaktivzeit aktiv";
CM_ SG_ 2600468527 NM_SFA_SNI "Source Node-Identifier (SNI) identifiziert den Sender der NM-Botschaft (Knotenadresse) eindeutig im Fahrzeug";
CM_ SG_ 2600468527 NM_SFA_NM_State "1 = Zustand Repeat Message (<-- Bus-Sleep Mode)
2 = Zustand Repeat Message (<-- Prepare Bus-Sleep Mode)
4 = Zustand Normal Operation (<-- Repeat Message)
8 = Zustand Normal Operation (<-- Ready Sleep)";
CM_ SG_ 2600468527 NM_SFA_Car_Wakeup "Car Wakeup (Gateway wertet aus)
";
CM_ SG_ 2600468527 NM_SFA_Wakeup "enthält die Weckursache; stehen mehrere Weckursachen parallel an, dann muss der kleinste Wert übertragen werden
";
CM_ SG_ 2600468527 NM_SFA_NM_aktiv_KL15 "Steuergerät hat KL15-EIN erkannt";
CM_ SG_ 2600468527 NM_SFA_NM_aktiv_Diagnose "Diagnose befindet sich nach VW80124 in einer NonDefaultDiagnostic-Session, z.B. ExtendedDiagnostic-Session";
CM_ SG_ 2600468527 NM_SFA_NM_aktiv_Tmin "Mindestaktivzeit ist noch nicht abgelaufen (bei jedem Weckereignis wird die Mindestaktivzeit neu gestartet)";
CM_ SG_ 2600468527 NM_SFA_UDS_CC "Funktionseinschränkung aufgrund aktivem UDS-Communication Control; siehe VW80124";
CM_ SG_ 2600468645 NM_WLC1_SNI "Source Node-Identifier (SNI) identifiziert den Sender der NM-Botschaft (Knotenadresse) eindeutig im Fahrzeug";
CM_ SG_ 2600468645 NM_WLC1_CBV_AWB "Das Signal ist zu setzen, wenn das SG aktiv den Bus geweckt hat";
CM_ SG_ 2600468645 NM_WLC1_CBV_CRI "Das Signal ist dauerhaft gesetzt, wenn das NM-Layout dem neuen NM-Layout für Teilnetzbetrieb entspricht";
CM_ SG_ 2600468645 NM_WLC1_NM_State "1 = Zustand Repeat Message (<-- Bus-Sleep Mode)
2 = Zustand Repeat Message (<-- Prepare Bus-Sleep Mode)
4 = Zustand Normal Operation (<-- Repeat Message)
8 = Zustand Normal Operation (<-- Ready Sleep)";
CM_ SG_ 2600468645 NM_WLC1_Car_Wakeup "Car Wakeup (Gateway wertet aus)";
CM_ SG_ 2600468645 NM_WLC1_UDS_CC "Funktionseinschränkung aufgrund aktivem UDS-Communication Control; siehe VW80124";
CM_ SG_ 2600468645 NM_WLC1_NM_aktiv_KL15 "Steuergerät hat KL15-EIN erkannt";
CM_ SG_ 2600468645 NM_WLC1_aktiv_Diagnose "Diagnose befindet sich nach VW80124 in einer NonDefaultDiagnostic-Session, z.B. ExtendedDiagnostic-Session";
CM_ SG_ 2600468645 NM_WLC1_aktiv_Tmin "Mindestaktivzeit ist noch nicht abgelaufen (bei jedem Weckereignis wird die Mindestaktivzeit neu gestartet)";
CM_ SG_ 2600468645 NM_WLC1_NM_aktiv_MIBCAN "MIB-CAN länger als Mindestaktivzeit aktiv";
CM_ SG_ 2600468645 NM_WLC1_CAB "CAB = Clusteraktivbits";
CM_ SG_ 2600468646 NM_WLC2_SNI "Source Node-Identifier (SNI) identifiziert den Sender der NM-Botschaft (Knotenadresse) eindeutig im Fahrzeug";
CM_ SG_ 2600468646 NM_WLC2_CBV_AWB "Das Signal ist zu setzen, wenn das SG aktiv den Bus geweckt hat";
CM_ SG_ 2600468646 NM_WLC2_CBV_CRI "Das Signal ist dauerhaft gesetzt, wenn das NM-Layout dem neuen NM-Layout für Teilnetzbetrieb entspricht";
CM_ SG_ 2600468646 NM_WLC2_NM_State "1 = Zustand Repeat Message (<-- Bus-Sleep Mode)
																					   
																					
2 = Zustand Repeat Message (<-- Prepare Bus-Sleep Mode)
4 = Zustand Normal Operation (<-- Repeat Message)
8 = Zustand Normal Operation (<-- Ready Sleep)";
CM_ SG_ 2600468646 NM_WLC2_Car_Wakeup "Car Wakeup (Gateway wertet aus)";
CM_ SG_ 2600468646 NM_WLC2_UDS_CC "Funktionseinschränkung aufgrund aktivem UDS-Communication Control; siehe VW80124";
CM_ SG_ 2600468646 NM_WLC2_NM_aktiv_KL15 "Steuergerät hat KL15-EIN erkannt";
CM_ SG_ 2600468646 NM_WLC2_aktiv_Diagnose "Diagnose befindet sich nach VW80124 in einer NonDefaultDiagnostic-Session, z.B. ExtendedDiagnostic-Session";
CM_ SG_ 2600468646 NM_WLC2_aktiv_Tmin "Mindestaktivzeit ist noch nicht abgelaufen (bei jedem Weckereignis wird die Mindestaktivzeit neu gestartet)";
CM_ SG_ 2600468646 NM_WLC2_NM_aktiv_MIBCAN "MIB-CAN länger als Mindestaktivzeit aktiv";
CM_ SG_ 2600468646 NM_WLC2_CAB "CAB = Clusteraktivbits";
CM_ SG_ 2549875367 OBDC_SDC1_Req_Data "OBDC Strecke für SDC1 - Req Kanal";
CM_ SG_ 2550006439 OBDC_SDC1_Resp_Data "OBDC Kanal SDC1";
CM_ SG_ 2549875368 OBDC_SDC2_Req_Data "OBDC Kanal SDC2";
CM_ SG_ 2550006440 OBDC_SDC2_Resp_Data "OBDC Kanal SD2";
CM_ SG_ 2549875365 OBDC_WLC1_Req_Data "OBDC Strecke für WLC1 - Req Kanal";
CM_ SG_ 2550006437 OBDC_WLC1_Resp_Data "OBDC Strecke für WLC1 - Resp Kanal";
CM_ SG_ 2549875366 OBDC_WLC2_Req_Data "OBDC Strecke für WLC2 - Req Kanal";
CM_ SG_ 2550006438 OBDC_WLC2_Resp_Data "OBDC Strecke für WLC2 - Resp Kanal";
CM_ SG_ 2589283656 ORU_Warnung "Wenn durch Störungen der Funktion Online Remote Update nicht sichergestellt ist, dass vor Kunde keine Funktionseinschränkungen auftreten, muss der Benutzer des Fahrzeugs entsprechend gewarnt werden.";
CM_ SG_ 2589283656 ORU_Status "Broadcast des Status der Konzernfunktion Online Remote Update";
CM_ SG_ 1616 RA_Radio_on "1 = user perceived On";
CM_ SG_ 1616 RA_PowerAmpOn "1 = Request for Amplifier; 0 = Amplifier mute/off";
CM_ SG_ 1616 RA_Radio_mute "1=Radio is muted for telephone";
CM_ SG_ 1616 RA_VNC_OFF "VNC = Vehicle Noice Cancellation;
1 = VNC OFF; 0 = VNC ON
requests the Amp to switch VNC off";
CM_ SG_ 1616 RA_Radio_Surround "1 = Surround ON; 0 = Surround OFF
requests the Amp to switch Surroundmode";
CM_ SG_ 1616 RA_Frequency "Übermittlung der gehörten Audiofrequenz (AM)
wird mit RA_Frequency_unit multipliziert.
Auf dem Bus werden nur eingerastete Frequenzen übertragen. Bei aktivem Tuning (RA_AM_Tuning = 1) wird 0 übertragen.";
CM_ SG_ 1616 RA_Frequency_unit "Faktor für RA_Frequency
bei AM: Faktor 0 = 1kHz
sonst   Faktor 1 = 100kHz

";
CM_ SG_ 1616 RA_AM_Tuning "Das Signal kennzeichnet einen aktiven AM Suchlauf. Während des Suchlaufes wird die Frequenz = 0 übertragen.
0 = frequency locked => Störquelle vermeidet die aktuelle Frequenz
1 = AM tuning in progress => Störquelle abschalten";
CM_ SG_ 1350 MMI_on_angefordert "Sonderfahrzeugassistent benötigt aktives Infotainment unabhängig von KlS/K15.";
CM_ SG_ 2589283480 SDC1_Variante "Variante vom Smart Display";
CM_ SG_ 2589283480 SDC1_Powerstate "Power state des SDC1";
CM_ SG_ 2589283480 SDC1_Q_Critical "kritische Abschaltstufe / Transport Modus im SDC aktiv";
CM_ SG_ 2589283480 SDC1_LastOn "LastON Verhalten vom SDC";
CM_ SG_ 2589283480 SDC1_SystemMode "Anzeige des aktuellen System Mode ";
CM_ SG_ 2589283480 SDC1_KL_30F "Gemessene Versorgungsspannung vom Smart Display.";
CM_ SG_ 2589283480 SDC1_TempSens "Smart Display aktueller Temperaturwert";
CM_ SG_ 2589283480 SDC1_TempSensMax "Gespeicherte maximale Sensortemperatur.";
CM_ SG_ 2589283482 SDC2_Variante "Variante vom Smart Display";
CM_ SG_ 2589283482 SDC2_Powerstate "Power state des SDC2";
CM_ SG_ 2589283482 SDC2_Q_Critical "kritische Abschaltstufe / Transport Modus im SDC aktiv";
CM_ SG_ 2589283482 SDC2_LastOn "LastON Verhalten vom SDC";
CM_ SG_ 2589283482 SDC2_SystemMode "Anzeige des aktuellen System Mode ";
CM_ SG_ 2589283482 SDC2_KL_30F "Gemessene Versorgungsspannung vom Smart Display.";
CM_ SG_ 2589283482 SDC2_TempSens "Smart Display aktueller Temperaturwert";
CM_ SG_ 2589283482 SDC2_TempSensMax "Gespeicherte maximale Sensortemperatur.";
CM_ SG_ 2589283486 SCC_State "Power state des Smart Remote Control";
CM_ SG_ 2589283486 SCC_Temp_Fehler "Smart Remote Control hat einen Temperaturfehler erkannt.";
CM_ SG_ 2589283486 SCC_KL30_Uebersp_Fehler "Smart Remote Control erkannter Überspannungsfehler";
CM_ SG_ 2589283486 SCC_KL30_Untersp_Fehler "Smart Remote Control erkannter Unterspannungsfehler";
CM_ SG_ 2589283486 SCC_KL_30F "Gemessene Versorgungsspannung vom Smart Remote Control.";
CM_ SG_ 2589283486 SCC_TempSens "Smart Remote Control aktueller Temperaturwert";
CM_ SG_ 2589283486 SCC_TempSensMax "Gespeicherte maximale Sensortemperatur.";
CM_ SG_ 2589283486 SCC_Variant "Variante vom Smart Remote Control.";
CM_ SG_ 2589283486 SCC1_Powerstate "Power state des Smart Control";
CM_ SG_ 2589283487 EEPROM_Fehler "EEPROM Defekt erkannt.";
CM_ SG_ 2589283488 SCC_State "Power state des Smart Remote Control";
CM_ SG_ 2589283488 SCC_Temp_Fehler "Smart Remote Control hat einen Temperaturfehler erkannt.";
CM_ SG_ 2589283488 SCC_KL30_Uebersp_Fehler "Smart Remote Control erkannter Überspannungsfehler";
CM_ SG_ 2589283488 SCC_KL30_Untersp_Fehler "Smart Remote Control erkannter Unterspannungsfehler";
CM_ SG_ 2589283488 SCC_KL_30F "Gemessene Versorgungsspannung vom Smart Remote Control.";
CM_ SG_ 2589283488 SCC_TempSens "Smart Remote Control aktueller Temperaturwert";
CM_ SG_ 2589283488 SCC_TempSensMax "Gespeicherte maximale Sensortemperatur.";
CM_ SG_ 2589283488 SCC_Variant "Variante vom Smart Remote Control.";
CM_ SG_ 2589283488 SCC2_Powerstate "Power state des Smart Control";
CM_ SG_ 2589283489 EEPROM_Fehler "EEPROM Defekt erkannt.";
CM_ SG_ 2549876209 SWDL_ABT_1_Req_Data "Softwaredownload über ISO TP.";
CM_ SG_ 2550007281 SWDL_ABT_1_Resp_Data "Softwaredownload über ISO TP.";
CM_ SG_ 2549876208 SWDL_BT_1_Req_Data "Softwaredownload über ISO TP.";
CM_ SG_ 2550007280 SWDL_BT_1_Resp_Data "Softwaredownload über ISO TP.";
CM_ SG_ 2549876210 SWDL_DU_1_Req_Data "Softwaredownload über ISO TP.";
CM_ SG_ 2550007282 SWDL_DU_1_Resp_Data "Softwaredownload über ISO TP.";
CM_ SG_ 2549876213 SWDL_DU_2_Req_Data "Softwaredownload über ISO TP.";
CM_ SG_ 2550007285 SWDL_DU_2_Resp_Data "Softwaredownload über ISO TP.";
CM_ SG_ 2549876222 SWDL_DU_3_Req_Data "Softwaredownload über ISO TP.";
CM_ SG_ 2550007294 SWDL_DU_3_Resp_Data "Softwaredownload über ISO TP.";
CM_ SG_ 2549876212 SWDL_DU_4_Req_Data "Softwaredownload über ISO TP.";
CM_ SG_ 2550007284 SWDL_DU_4_Resp_Data "Softwaredownload über ISO TP.";
CM_ SG_ 2549876214 SWDL_LSR_1_Req_Data "Softwaredownload über ISO TP.";
CM_ SG_ 2550007286 SWDL_LSR_1_Resp_Data "Softwaredownload über ISO TP.";
CM_ SG_ 2549876138 SWDL_SCC1_Req_Data "Softwaredownload über ISO TP.";
CM_ SG_ 2550007210 SWDL_SCC1_Resp_Data "Softwaredownload über ISO TP.";
CM_ SG_ 2549876139 SWDL_SCC2_Req_Data "Softwaredownload über ISO TP.";
CM_ SG_ 2550007211 SWDL_SCC2_Resp_Data "Softwaredownload über ISO TP.";
CM_ SG_ 2549876135 SWDL_SDC1_Req_Data "Softwaredownload über ISO TP.";
CM_ SG_ 2550007207 SWDL_SDC1_Resp_Data "Softwaredownload über ISO TP.";
CM_ SG_ 2549876136 SWDL_SDC2_Req_Data "Softwaredownload über ISO TP.";
CM_ SG_ 2550007208 SWDL_SDC2_Resp_Data "Softwaredownload über ISO TP.";
CM_ SG_ 2549876133 SWDL_WLC1_Req "Softwaredownload über ISO TP.";
CM_ SG_ 2550007205 SWDL_WLC1_Resp "Softwaredownload über ISO TP.";
CM_ SG_ 2549876134 SWDL_WLC2_Req "Softwaredownload über ISO TP.";
CM_ SG_ 2550007206 SWDL_WLC2_Resp "Softwaredownload über ISO TP.";
CM_ BO_ 1413 "MQB, MLBevo";
CM_ SG_ 1413 SI_Sammel_SG_Fehler "Anzahl der gesetzten KD-Fehler direkt angeschlossener Steuergeräte der DK3 und DK4 gemäß 80127.
Hinweis: Ein Subbusmaster stellt nur die gesammelte Information der an ihn angeschlossenen Steuergeräte der DK3 und DK4 zur Verfügung.

Für ServiceKey Auswe";
CM_ SG_ 1413 SI_P_Mode_gueltig "zeigt an, ob es sich um ein Fahrzeug mit zentraler oder dezentraler Steu-erung des Produktionsmodes handelt
Siehe Q-LAH Produktionsmode (LAH.DUM.907.AS)";
CM_ SG_ 1413 SI_Diagnose_Aktiv "Gibt an ob Diagnose-Botschaften empfangen werden und somit eine Diagnose aktiv ist.
MQB: Gibt an ob Diagnose-Bus Botschaften empfangen werden und somit eine Diagnose aktiv ist.";
CM_ SG_ 1413 SI_T_Mode "0x0: Transportmodus nicht aktiv
0x1: Transportmodus aktiv";
CM_ SG_ 1413 SI_NWDF "Netzwerk-Diagnose Freigebe zur zentralen Aktivierung der Netzwerkdiagnose";
CM_ SG_ 1413 SI_NWDF_gueltig "Gültigkeitsbit zu SI_NWDF gemäß Lastenheft: Zentrale Aktivierung Netzwerkdiagnose";
CM_ SG_ 1413 SI_Sammelfehler "Sammelfehlermeldung zur Anzeige im Kombi - siehe Spez. Sammelfehlermeldung
Hinweis: Einzelne Steuergeräte können zur Anpassung an den Produktionsprozess im Gateway auskodiert werden!";
CM_ SG_ 1413 GW_KD_Fehler "Kundendienstfehlerbit Gateway zur Anzeige eines im Gateway abgelegten Fehlerspeichereintrages.";
CM_ SG_ 1413 SI_T_Schutz "Transportschutz-Signal, das bei Transportmodus und Motorlauf aktiv bleibt
0x0: Transportschutz nicht aktiv
0x1: Transportschutz aktiv";
CM_ SG_ 1413 SI_P_Mode "Zentrale Steuerung des Produktionsmodes gemäß Q-LAH-Produktionsmode (LAH.DUM.907.AS)";
CM_ SG_ 1413 SI_BUS_01 "MQB/MQB_A0/PQ26: ACAN
MQB2020: ACAN(FD)
MLBevo: HCAN
MEB: ACAN(FD)";
CM_ SG_ 1413 SI_BUS_02 "MQB/MQB A0 Standard+, High: FCAN
MQB2020: FCAN(FD)
MLBevo: Frei
MEB: FCAN(FD)";
CM_ SG_ 1413 SI_BUS_03 "MQB/MQB A0/PQ26: KCAN
MQB2020: KCAN
MLBevo: KCAN
MEB: KCAN";
CM_ SG_ 1413 SI_BUS_04 "MQB/MQB A0 Standard+, High: ICAN
MQB2020: ICAN
MLBevo: ICAN
MEB: ABCAN(FD)";
CM_ SG_ 1413 SI_BUS_05 "MQB/MQB A0/PQ26: DiagCAN
MQB2020: DiagCAN(FD)
MLBevo: DiagCAN
MEB: DiagCAN(FD)";
CM_ SG_ 1413 SI_BUS_06 "MQB/MQB A0/PQ26: ECAN
MQB2020: FASCAN(FD)
MLBevo: ECAN
MEB: FASCAN(FD)";
CM_ SG_ 1413 SI_BUS_07 "MQB: LIN1 (Energie)
MQB2020: LIN1 (Energie)
MLBevo: LIN1 (Energie)";
CM_ SG_ 1413 SI_BUS_08 "MQB: LIN2 (MFL)
MQB2020: LIN2 (MFL)
MLBevo: LIN2 (MFL)";
CM_ SG_ 1413 SI_BUS_09 "MQB: LIN3 (unbelegt)
MQB2020: LIN3 (Uhr/FES)
MLBevo: LIN3 (Energie2)";
CM_ SG_ 1413 SI_BUS_10 "MLBevo: Flexray

MQB2020: MCAN";
CM_ SG_ 1413 SI_BUS_11 "MLBevo: Ethernet";
CM_ SG_ 1413 SI_BUS_12 "MQB: unbelegt
MLBevo: K2CAN";
CM_ SG_ 1413 SI_BUS_13 "MQB: unbelegt
MLBevo: DCAN
MEB: CCAN";
CM_ SG_ 1413 SI_BUS_14 "MQB/MQB A0: unbelegt
MQB2020: HCAN
MLBevo: CCAN
MEB: EVCAN(FD)";
CM_ SG_ 1413 SI_BUS_15 "MQB: frei
MQB2020: frei
MLBevo: frei
MEB: AFSCAN";
CM_ SG_ 1413 SI_Bus_Identifikation "Das Signal identifiziert den Bus eindeutig. Das Signal ist konstant auf jedem Bus.
Der Signalwert entspricht dem Wert 'Busnummer' aus der VW80127 Gateway_component_list_databus_identification (0x2A2D) 'Bus-Identifier'.";
CM_ BO_ 1716 "200ms bei D4 und folgende";
CM_ SG_ 1716 VIN_01_MUX "Achtung:
Die Botschaft ist nicht linear gemultiplext!!!
Sondern 0,1,0,2,0, usw.";
CM_ SG_ 1716 VIN_4 "Initwert:
0x2D bei Fahrzeugen mit Wegfahrsperrengeneration >= 5 
0x58 bei Fahrzeugen mit Wegfahrsperrengeneration < 5 (z.B. WFS-4)";
CM_ SG_ 1716 VIN_11 "Initwert:
0x2D bei Fahrzeugen mit Wegfahrsperrengeneration >= 5 
0x58 bei Fahrzeugen mit Wegfahrsperrengeneration < 5 (z.B. WFS-4)";
CM_ SG_ 1716 VIN_5 "Initwert:
0x2D bei Fahrzeugen mit Wegfahrsperrengeneration >= 5 
0x58 bei Fahrzeugen mit Wegfahrsperrengeneration < 5 (z.B. WFS-4)";
CM_ SG_ 1716 VIN_12 "Initwert:
0x2D bei Fahrzeugen mit Wegfahrsperrengeneration >= 5 
0x58 bei Fahrzeugen mit Wegfahrsperrengeneration < 5 (z.B. WFS-4)";
CM_ SG_ 1716 VIN_6 "Initwert:
0x2D bei Fahrzeugen mit Wegfahrsperrengeneration >= 5 
0x58 bei Fahrzeugen mit Wegfahrsperrengeneration < 5 (z.B. WFS-4)";
CM_ SG_ 1716 VIN_13 "Initwert:
0x2D bei Fahrzeugen mit Wegfahrsperrengeneration >= 5 
0x58 bei Fahrzeugen mit Wegfahrsperrengeneration < 5 (z.B. WFS-4)";
CM_ SG_ 1716 VIN_7 "Initwert:
0x2D bei Fahrzeugen mit Wegfahrsperrengeneration >= 5 
0x58 bei Fahrzeugen mit Wegfahrsperrengeneration < 5 (z.B. WFS-4)";
CM_ SG_ 1716 VIN_14 "Initwert:
0x2D bei Fahrzeugen mit Wegfahrsperrengeneration >= 5 
0x58 bei Fahrzeugen mit Wegfahrsperrengeneration < 5 (z.B. WFS-4)";
CM_ SG_ 1716 VIN_1 "Initwert:
0x2D bei Fahrzeugen mit Wegfahrsperrengeneration >= 5 
0x58 bei Fahrzeugen mit Wegfahrsperrengeneration < 5 (z.B. WFS-4)";
CM_ SG_ 1716 VIN_8 "Initwert:
0x2D bei Fahrzeugen mit Wegfahrsperrengeneration >= 5 
0x58 bei Fahrzeugen mit Wegfahrsperrengeneration < 5 (z.B. WFS-4)";
CM_ SG_ 1716 VIN_15 "Initwert:
0x2D bei Fahrzeugen mit Wegfahrsperrengeneration >= 5 
0x58 bei Fahrzeugen mit Wegfahrsperrengeneration < 5 (z.B. WFS-4)";
CM_ SG_ 1716 VIN_2 "Initwert:
0x2D bei Fahrzeugen mit Wegfahrsperrengeneration >= 5 
0x58 bei Fahrzeugen mit Wegfahrsperrengeneration < 5 (z.B. WFS-4)";
CM_ SG_ 1716 VIN_9 "Initwert:
0x2D bei Fahrzeugen mit Wegfahrsperrengeneration >= 5 
0x58 bei Fahrzeugen mit Wegfahrsperrengeneration < 5 (z.B. WFS-4)";
CM_ SG_ 1716 VIN_16 "Initwert:
0x2D bei Fahrzeugen mit Wegfahrsperrengeneration >= 5 
0x58 bei Fahrzeugen mit Wegfahrsperrengeneration < 5 (z.B. WFS-4)";
CM_ SG_ 1716 VIN_3 "Initwert:
0x2D bei Fahrzeugen mit Wegfahrsperrengeneration >= 5 
0x58 bei Fahrzeugen mit Wegfahrsperrengeneration < 5 (z.B. WFS-4)";
CM_ SG_ 1716 VIN_10 "Initwert:
0x2D bei Fahrzeugen mit Wegfahrsperrengeneration >= 5 
0x58 bei Fahrzeugen mit Wegfahrsperrengeneration < 5 (z.B. WFS-4)";
CM_ SG_ 1716 VIN_17 "Initwert:
0x2D bei Fahrzeugen mit Wegfahrsperrengeneration >= 5 
0x58 bei Fahrzeugen mit Wegfahrsperrengeneration < 5 (z.B. WFS-4)";
CM_ BO_ 916 "ersetzt WBA_02";
CM_ SG_ 916 WBA_03_CRC "Für MLB:
'Berechnung siehe Lastenheft 'Kommunikationsabsicherung für FlexRay und CAN''

Ab MQB und MLBevo:
'Berechnung siehe Lastenheft 'End-to-End Kommunikationsabsicherung''

Endwerte siehe Begleitdokument 'S-PDU Kennungsfolgen'";
CM_ SG_ 916 WBA_Fahrstufe_02 "Bei Automatgetrieben wird in diesem Signal die aktuelle anzuzeigende Fahrstufe ausgegeben.

Die Signalkodierungen 0x9, 0xA und 0xB werden im MSS-R8NF und MQB-A1/B/A2 verwendet.

Die Signalkodierungen 0xC und 0xD werden nur im MQB-A1/B/A2 verwendet.
";
CM_ SG_ 916 WBA_ZielFahrstufe "Zielfahrprogramm (Darstellung), für getipptes S/E/M mit neuem Wählhebel im MQB";
CM_ SG_ 916 WBA_GE_Warnung_02 "Prioritätswarnungen Getriebe";
CM_ SG_ 916 WBA_eing_Gang_02 "Das Automatikgetriebe gibt den aktuell eingelegten Gang aus.
Besonderheiten:
0x0 = marktabhängig wird auf Ganganzeige zur Fahrstufe komplett verzichtet
0xA = kurzzeitige Unterdrückung der Ganganzeige (z. B. Segeln, Zwischenstellung, etc.)";
CM_ SG_ 916 WBA_GE_Texte "Fahrerhinweise für das Kombi";
CM_ SG_ 916 WBA_Segeln_aktiv "Getriebe geht in den Segelbetrieb";
CM_ SG_ 916 WBA_Schaltschema "Bei Automatikgetrieben wird in diesem Signal die aktuelle, eingelegte Fahrstufe (=Wählhebelposition) ausgegeben.";
CM_ SG_ 916 WBA_GE_Zusatzwarnungen "Prioritaetswarnungen Getriebe an Kombi
Audi MLB Wertebereich 0 bis 3
VW MQB Projekte verwenden nur den Wertebereich 0 bis 2
VW MQB Getriebefehler werden über das Signal  GE_Warnungen_02 gesendet.";
CM_ SG_ 916 GE_Sollgang "Signalisiert den Sollgang, in den getippt werden soll. Abhängig vom Signal 'WBA_eing_Gang_02' und dem Sollgang kann dann das Kombi die Hochschaltempfehlung in Tip darstellen.";
CM_ SG_ 916 GE_Tipschaltempf_verfuegbar "Signalisierung, ob eine Hochschaltempfehlung im Tipmodus verfügbar ist oder nicht.";
CM_ SG_ 916 WBA_GE_Texte_02 "Fahrerhinweise für das Kombi";
CM_ SG_ 916 WBA_Blinken "Dieses Bit steuert die Fehlerlampe an oder wird zum Blinken der WBA-Anzeige genutzt - nur falls WBA_Senderkennung = 00 (GSG)
";
CM_ SG_ 916 GE_Wiederstart_Anz_Std "Dieses Signal gibt die detaillierte Begründung für einen Wiederstart vom Getriebesteuergerät an. ";
CM_ SG_ 916 GE_Stoppverbot_Anz_01 "Dieses Signal gibt die detaillierte Begründung für ein Stoppverbot vom Getriebesteuergerät an.";
CM_ SG_ 916 GE_Stoppverbot_Anz_02 "Dieses Signal gibt die detaillierte Begründung für ein Stoppverbot vom Getriebesteuergerät an.";
CM_ SG_ 916 GE_Stoppverbot_Anz_03 "Dieses Signal gibt die detaillierte Begründung für ein Stoppverbot vom Getriebesteuergerät an.";
CM_ SG_ 916 GE_Stoppverbot_Anz_04 "Dieses Signal gibt die detaillierte Begründung für ein Stoppverbot vom Getriebesteuergerät an.";
CM_ SG_ 916 GE_Stoppverbot_Anz_05 "Dieses Signal gibt die detaillierte Begründung für ein Stoppverbot vom Getriebesteuergerät an.";
CM_ SG_ 916 GE_Stoppverbot_Anz_06 "Dieses Signal gibt die detaillierte Begründung für ein Stoppverbot vom Getriebesteuergerät an.";
CM_ SG_ 916 GE_Stoppverbot_Anz_07 "Dieses Signal gibt die detaillierte Begründung für ein Stoppverbot vom Getriebesteuergerät an.";
CM_ SG_ 916 GE_Stoppverbot_Anz_Std "Dieses Signal gibt die detaillierte Begründung für ein Stoppverbot vom Getriebesteuergerät an.";
CM_ SG_ 2589283611 WLC1_Fehler "Übermittelt auftretende Fehler des WLC an das Master-SG zur Ablage im dort verorteten Fehlerspeicher";
CM_ SG_ 2589283611 WLC1_aktive_Spule "Active_Coil";
CM_ SG_ 2589283611 WLC1_Charger_Effizienz "Charger charging (Efficiency in % )
0 = no charging 
1 = charging with 1%
10 = charging with 10 %";
CM_ SG_ 2589283611 WLC1_Charger_laedt "Charger charging (übertragene Leistung) (0,1W)

0 = no charging 
1 = charging with 0,1 Watt
10 = charging with 1 Watt";
CM_ SG_ 2589283611 WLC1_Fremdobjekt_erkannt "Messwert/Anzeige Fremdobjekt erkannt";
CM_ SG_ 2589283611 WLC1_Leistungsklasse_Receiver "Performance_Class_Receiver
0 = no Device
1 = class with 0,1 Watt
10 = class with 1 Watt";
CM_ SG_ 2589283611 WLC1_Objekt_erkannt "non wireless Charging Device in the storage box ";
CM_ SG_ 2589283611 WLC1_Receiver_erkannt "wireless Charging Device (Phone) is in the storage box ";
CM_ SG_ 2589283611 WLC1_Receiver_voll_geladen "0 = WLC not fully charged or no Device available
1 = WLC Device fully charged ";
CM_ SG_ 2589283611 WLC1_verwendeter_Ladestandard "WLC_technology";
CM_ SG_ 2589283611 WLC1_Temp_Leistungsteil_Charger "Temperature_Power_Electronics
0 = -58 °C
1 = -57 °C
..";
CM_ SG_ 2589283611 WLC1_Temp_Oberfaeche_Charger "Surface_Temperature_WLC
0 = -58 °C
1 = -57 °C
..";
CM_ SG_ 2589283611 WLC1_Temp_Receiver "Temperature_Receiver
0 = -58 °C
1 = -57 °C
..";
CM_ SG_ 2583733509 WLC1_SWDL_Req "Softwaredownload über ISO TP.";
CM_ SG_ 2583864581 WLC1_SWDL_Resp "Softwaredownload über ISO TP.";
CM_ SG_ 2589283612 WLC2_aktive_Spule "Active_Coil
0 = no Coil active
1 = first Coil active
2 = second Coil active
3 = third Coil active

..";
CM_ SG_ 2589283612 WLC2_Charger_Effizienz "Charger charging (Efficiency in % )
0 = no charging 
1 = charging with 1%
10 = charging with 10 %";
CM_ SG_ 2589283612 WLC2_Charger_laedt "Charger charging (übertragene Leistung) (0,1W)

0 = no charging 
1 = charging with 0,1 Watt
10 = charging with 1 Watt";
CM_ SG_ 2589283612 WLC2_Fremdobjekt_erkannt "Messwert/Anzeige";
CM_ SG_ 2589283612 WLC2_Leistungsklasse_Receiver "Performance_Class_Receiver
0 = no Device
1 = class with 0,1 Watt
10 = class with 1 Watt";
CM_ SG_ 2589283612 WLC2_Objekt_erkannt "non wireless Charging Device in the storage box ";
CM_ SG_ 2589283612 WLC2_Receiver_erkannt "wireless Charging Device (Phone) is in the storage box ";
CM_ SG_ 2589283612 WLC2_Receiver_voll_geladen "0 = WLC not fully charged or no Device available
1 = WLC Device fully charged ";
CM_ SG_ 2589283612 WLC2_verwendeter_Ladestandard "WLC_technology
0 = QI
1 = PMA
2 = A4WP
3 = QI and PMA
4 = QI and A4WP
..";
CM_ SG_ 2589283612 WLC2_Temp_Leistungsteil_Charger "Temperature_Power_Electronics
0 = -58 °C
1 = -57 °C
..";
CM_ SG_ 2589283612 WLC2_Temp_Oberfaeche_Charger "Surface_Temperature_WLC
0 = -58 °C
1 = -57 °C
..";
CM_ SG_ 2589283612 WLC2_Temp_Receiver "Temperature_Receiver
0 = -58 °C
1 = -57 °C
..";
CM_ SG_ 2583733765 WLC2_SWDL_Req "Softwaredownload über ISO TP.";
CM_ SG_ 2583864837 WLC2_SWDL_Resp "Softwaredownload über ISO TP.";
CM_ SG_ 1140 ZR_State_DU_1 "Kontrollbit für Display, Hintergrundbeleuchtung aus, Hintergrundbeleuchtung an, Energiesparmodus.
";
CM_ SG_ 1140 ZR_State_DU_2 "Kontrollbit für Display, Hintergrundbeleuchtung aus, Hintergrundbeleuchtung an, Energiesparmodus.
";
CM_ SG_ 1140 ZR_State_DU_3 "Kontrollbit für Display, Hintergrundbeleuchtung aus, Hintergrundbeleuchtung an, Energiesparmodus.
";
CM_ SG_ 1140 ZR_WecktGesp "Befehl zum Sperren der Wecktasten am Bedienteil.";
CM_ SG_ 1140 MMI_State "Powerstate des Zentralrechners. MMI_Off wird im Zustand dead mode gesendet.";
CM_ SG_ 1140 ZR_DimOffs_DU_1 "Dimmungs-Offset der Display Unit.";
CM_ SG_ 1140 ZR_DimOffs_DU_2 "Dimmungs-Offset der Display Unit.";
CM_ SG_ 1140 ZR_DimOffs_DU_3 "Dimmungs-Offset der Display Unit.";
CM_ SG_ 1140 SI_ICAN "Busruhe ICAN.";
CM_ SG_ 1140 ZR_Lenkerposition "Ueber Diagnose (Codierung) im Zentralrechner eingespeicherte Lenkerposition
  ";
CM_ SG_ 1140 WLC1_Systemzustand "0 = Wireless Charger off
1 = Wireless Charger on";
CM_ SG_ 1140 WLC2_Systemzustand "0 = Wireless Charger off
1 = Wireless Charger on";
CM_ SG_ 1140 DI_Screendesign "Information welcher Designwunsch ausgewählt wurde zur Kennlinienumschaltung";
CM_ SG_ 1140 ZR_State_DU_4 "Kontrollbit für Display, Hintergrundbeleuchtung aus, Hintergrundbeleuchtung an, Energiesparmodus.";
CM_ SG_ 1140 ZR_DimOffs_DU_4 "Dimmungs-Offset der Display Unit.";
CM_ BO_ 2589283603 "ICAN --> MIB-CAN";
CM_ SG_ 2589283603 ZV_verriegelt_extern_soll_alt "Veraltet Bit für das Signal:

Botschaft ZR_Gateway_01:
Byte 3, Bit 0  ZV_verriegelt_extern_soll";
CM_ SG_ 2589283603 ESP_v_Signal "Geschwindigkeitssignal vom ABS/ASR oder ESP. Mittelwert der angetriebenen Räder.
Bei MSR oder ABS Eingriffen wird die ABS-Referenzgeschwindigkeit für >= 200ms eingespiegelt (Zeit wird mit Aktiv-Flanke der Funktionsbits getriggert)

MQB: Bei Frontantrie";
CM_ SG_ 2589283603 MO_Drehzahl_01 "Im Fehlerfall wird die Motordrehzahl über die Nockenwellendrehzahl als Ersatzgrösse ausgegeben

Bei Parallelhybrid: Getriebeeingangsdrehzahl (=E-Maschinen Drehzahl)

Hinweis: 
Ehemaliger Fehlerwert 0xFFFF wird senderseitig nicht unterstützt. 
Diesen";
CM_ SG_ 2589283603 KY_LF_Aktiv "LF Schluesselkommunikation
";
CM_ SG_ 2589283603 ZV_verriegelt_extern_soll "Sollzustand: Verriegelung Fahrzeug aussen
";
BA_DEF_ BO_  "DiagRequest" ENUM  "No","Yes";
BA_DEF_ BO_  "DiagResponse" ENUM  "No","Yes";
BA_DEF_ BO_  "DiagState" ENUM  "No","Yes";
BA_DEF_ BO_  "GenMsgChkConstant" HEX 0 4095;
BA_DEF_ BO_  "GenMsgCycleTime" INT 0 65535;
BA_DEF_ BO_  "GenMsgCycleTimeFast" INT 0 65535;
BA_DEF_ BO_  "GenMsgDelayTime" INT 0 100000;
BA_DEF_ BO_  "GenMsgILSupport" ENUM  "No","Yes";
BA_DEF_ BO_  "GenMsgNrOfRepetition" INT 0 100;
BA_DEF_ BO_  "GenMsgPDUConstants" STRING ;
BA_DEF_ BO_  "GenMsgSendType" ENUM  "Cyclic","not_used","not_used","not_used","not_used","not_used","not_used","IfActive","NoMsgSendType";
BA_DEF_ BO_  "GenMsgStartDelayTime" INT 0 100000;
BA_DEF_ BO_  "NmMessage" ENUM  "No","Yes";
BA_DEF_ BO_  "NmhMessage" ENUM  "No","Yes";
BA_DEF_ BO_  "MsgType" ENUM  "Application","NM ","NMH","TP2.0","ISO-TP ","BAP","EID","KS";
BA_DEF_ BO_  "VAGTP20_API" HEX 0 255;
BA_DEF_ BO_  "VAGTP20_DynConnection" ENUM  "No","Yes";
BA_DEF_ BO_  "VAGTP20_DynSetup" ENUM  "No","Yes";
BA_DEF_ BO_  "VAGTP20_StatConnection" ENUM  "No","Yes";
BA_DEF_ SG_  "GenSigActiveRepetitions" INT -2147483648 2147483647;
BA_DEF_ SG_  "GenSigInactiveValue" INT -2147483648 2147483647;
BA_DEF_ SG_  "GenSigSendType" ENUM  "Cyclic","OnWrite","OnWriteWithRepetition","OnChange","OnChangeWithRepetition","IfActive","IfActiveWithRepetition","NoSigSendType","OnChangeAndIfActive","OnChangeAndIfActiveWithRepetition";
BA_DEF_ SG_  "GenSigStartValue" INT -2147483648 2147483647;
BA_DEF_ SG_  "NWM-WakeupAllowed" ENUM  "No","Yes";
BA_DEF_ SG_  "GenSigFuncType" ENUM  "NoFunction","MsgCounter","CRC-8","XOR","XOR-2","DatedBit","SW-Kl15","CHK","Constant","Protocol","CRC-8-SAE_J1850","CRC-32","DataLength","DataID","MsgCounter16","SOK-Signatur";
BA_DEF_ SG_  "GenSigSwitchedByIgnition" ENUM  "No","Yes";
BA_DEF_ SG_  "Fehlerwert" HEX 0 2147483647;
BA_DEF_ SG_  "GenSigMissingSourceValue" HEX 0 2147483647;
BA_DEF_REL_ BU_SG_REL_  "GenSigTimeoutTime" INT 0 65535;
BA_DEF_DEF_  "DiagRequest" "No";
BA_DEF_DEF_  "DiagResponse" "No";
BA_DEF_DEF_  "DiagState" "No";
BA_DEF_DEF_  "GenMsgChkConstant" 0;
BA_DEF_DEF_  "GenMsgCycleTime" 0;
BA_DEF_DEF_  "GenMsgCycleTimeFast" 0;
BA_DEF_DEF_  "GenMsgDelayTime" 0;
BA_DEF_DEF_  "GenMsgILSupport" "No";
BA_DEF_DEF_  "GenMsgNrOfRepetition" 0;
BA_DEF_DEF_  "GenMsgPDUConstants" "";
BA_DEF_DEF_  "GenMsgSendType" "NoMsgSendType";
BA_DEF_DEF_  "GenMsgStartDelayTime" 0;
BA_DEF_DEF_  "NmMessage" "No";
BA_DEF_DEF_  "NmhMessage" "No";
BA_DEF_DEF_  "MsgType" "Application";
BA_DEF_DEF_  "VAGTP20_API" 0;
BA_DEF_DEF_  "VAGTP20_DynConnection" "No";
BA_DEF_DEF_  "VAGTP20_DynSetup" "No";
BA_DEF_DEF_  "VAGTP20_StatConnection" "No";
BA_DEF_DEF_  "GenSigActiveRepetitions" 0;
BA_DEF_DEF_  "GenSigInactiveValue" 0;
BA_DEF_DEF_  "GenSigSendType" "NoSigSendType";
BA_DEF_DEF_  "GenSigStartValue" 0;
BA_DEF_DEF_  "NWM-WakeupAllowed" "No";
BA_DEF_DEF_  "GenSigFuncType" "NoFunction";
BA_DEF_DEF_  "GenSigSwitchedByIgnition" "Yes";
BA_DEF_DEF_  "Fehlerwert" 0;
BA_DEF_DEF_  "GenSigMissingSourceValue" 0;
BA_DEF_DEF_REL_ "GenSigTimeoutTime" 0;
BA_ "MsgType" BO_ 2600468650 2;
BA_ "NmhMessage" BO_ 2600468650 1;
BA_ "GenMsgCycleTime" BO_ 2600468650 200;
BA_ "MsgType" BO_ 2600468651 2;
BA_ "NmhMessage" BO_ 2600468651 1;
BA_ "GenMsgCycleTime" BO_ 2600468651 200;
BA_ "MsgType" BO_ 2600468647 2;
BA_ "NmhMessage" BO_ 2600468647 1;
BA_ "GenMsgCycleTime" BO_ 2600468647 200;
BA_ "MsgType" BO_ 2600468648 2;
BA_ "NmhMessage" BO_ 2600468648 1;
BA_ "GenMsgCycleTime" BO_ 2600468648 200;
BA_ "MsgType" BO_ 2600468527 2;
BA_ "NmhMessage" BO_ 2600468527 1;
BA_ "GenMsgCycleTime" BO_ 2600468527 200;
BA_ "MsgType" BO_ 2600468645 2;
BA_ "NmhMessage" BO_ 2600468645 1;
BA_ "GenMsgCycleTime" BO_ 2600468645 200;
BA_ "MsgType" BO_ 2600468646 2;
BA_ "NmhMessage" BO_ 2600468646 1;
BA_ "GenMsgCycleTime" BO_ 2600468646 200;
BA_ "MsgType" BO_ 2549875370 4;
BA_ "MsgType" BO_ 2550006442 4;
BA_ "MsgType" BO_ 2549875371 4;
BA_ "MsgType" BO_ 2550006443 4;
BA_ "MsgType" BO_ 2549875367 4;
BA_ "MsgType" BO_ 2550006439 4;
BA_ "MsgType" BO_ 2549875368 4;
BA_ "MsgType" BO_ 2550006440 4;
BA_ "MsgType" BO_ 2549875365 4;
BA_ "DiagRequest" BO_ 2549875365 1;
BA_ "MsgType" BO_ 2550006437 4;
BA_ "DiagResponse" BO_ 2550006437 1;
BA_ "MsgType" BO_ 2549875366 4;
BA_ "DiagRequest" BO_ 2549875366 1;
BA_ "MsgType" BO_ 2550006438 4;
BA_ "DiagResponse" BO_ 2550006438 1;
BA_ "GenMsgSendType" BO_ 2589283656 0;
BA_ "GenMsgILSupport" BO_ 2589283656 1;
BA_ "GenMsgDelayTime" BO_ 2589283656 100;
BA_ "GenMsgCycleTime" BO_ 2589283656 500;
BA_ "GenMsgSendType" BO_ 1616 0;
BA_ "GenMsgILSupport" BO_ 1616 1;
BA_ "GenMsgDelayTime" BO_ 1616 50;
BA_ "GenMsgCycleTime" BO_ 1616 1000;
BA_ "GenMsgSendType" BO_ 1350 0;
BA_ "GenMsgILSupport" BO_ 1350 1;
BA_ "GenMsgDelayTime" BO_ 1350 40;
BA_ "GenMsgCycleTime" BO_ 1350 1000;
BA_ "GenMsgSendType" BO_ 2589283480 0;
BA_ "GenMsgILSupport" BO_ 2589283480 1;
BA_ "GenMsgDelayTime" BO_ 2589283480 40;
BA_ "GenMsgCycleTime" BO_ 2589283480 1000;
BA_ "GenMsgSendType" BO_ 2589283482 0;
BA_ "GenMsgILSupport" BO_ 2589283482 1;
BA_ "GenMsgDelayTime" BO_ 2589283482 40;
BA_ "GenMsgCycleTime" BO_ 2589283482 1000;
BA_ "GenMsgSendType" BO_ 2589283486 0;
BA_ "GenMsgILSupport" BO_ 2589283486 1;
BA_ "GenMsgDelayTime" BO_ 2589283486 40;
BA_ "GenMsgCycleTime" BO_ 2589283486 1000;
BA_ "GenMsgSendType" BO_ 2589283487 0;
BA_ "GenMsgILSupport" BO_ 2589283487 1;
BA_ "GenMsgDelayTime" BO_ 2589283487 40;
BA_ "GenMsgCycleTime" BO_ 2589283487 1000;
BA_ "GenMsgSendType" BO_ 2589283488 0;
BA_ "GenMsgILSupport" BO_ 2589283488 1;
BA_ "GenMsgDelayTime" BO_ 2589283488 40;
BA_ "GenMsgCycleTime" BO_ 2589283488 1000;
BA_ "GenMsgSendType" BO_ 2589283489 0;
BA_ "GenMsgILSupport" BO_ 2589283489 1;
BA_ "GenMsgDelayTime" BO_ 2589283489 40;
BA_ "GenMsgCycleTime" BO_ 2589283489 1000;
BA_ "MsgType" BO_ 2549876209 4;
BA_ "MsgType" BO_ 2550007281 4;
BA_ "MsgType" BO_ 2549876208 4;
BA_ "MsgType" BO_ 2550007280 4;
BA_ "MsgType" BO_ 2549876210 4;
BA_ "MsgType" BO_ 2550007282 4;
BA_ "MsgType" BO_ 2549876213 4;
BA_ "MsgType" BO_ 2550007285 4;
BA_ "MsgType" BO_ 2549876222 4;
BA_ "MsgType" BO_ 2550007294 4;
BA_ "MsgType" BO_ 2549876214 4;
BA_ "MsgType" BO_ 2550007286 4;
BA_ "MsgType" BO_ 2549876138 4;
BA_ "MsgType" BO_ 2550007210 4;
BA_ "MsgType" BO_ 2549876139 4;
BA_ "MsgType" BO_ 2550007211 4;
BA_ "MsgType" BO_ 2549876135 4;
BA_ "MsgType" BO_ 2550007207 4;
BA_ "MsgType" BO_ 2549876136 4;
BA_ "MsgType" BO_ 2550007208 4;
BA_ "MsgType" BO_ 2549876133 4;
BA_ "MsgType" BO_ 2550007205 4;
BA_ "MsgType" BO_ 2549876134 4;
BA_ "MsgType" BO_ 2550007206 4;
BA_ "GenMsgSendType" BO_ 1413 0;
BA_ "GenMsgILSupport" BO_ 1413 1;
BA_ "GenMsgDelayTime" BO_ 1413 10;
BA_ "GenMsgCycleTime" BO_ 1413 1000;
BA_ "GenMsgSendType" BO_ 1716 0;
BA_ "GenMsgCycleTime" BO_ 1716 200;
BA_ "GenMsgSendType" BO_ 916 0;
BA_ "GenMsgPDUConstants" BO_ 916 "0x47,0x94,0x92,0x6a,0x67,0xb5,0x0d,0x38,0xe3,0x8a,0x5d,0xb4,0x54,0xab,0xae,0x27";
BA_ "GenMsgILSupport" BO_ 916 1;
BA_ "GenMsgCycleTime" BO_ 916 160;
BA_ "GenMsgSendType" BO_ 2589283611 0;
BA_ "GenMsgILSupport" BO_ 2589283611 1;
BA_ "GenMsgDelayTime" BO_ 2589283611 40;
BA_ "GenMsgCycleTime" BO_ 2589283611 1000;
BA_ "MsgType" BO_ 2583733509 4;
BA_ "MsgType" BO_ 2583864581 4;
BA_ "GenMsgSendType" BO_ 2589283612 0;
BA_ "GenMsgILSupport" BO_ 2589283612 1;
BA_ "GenMsgDelayTime" BO_ 2589283612 40;
BA_ "GenMsgCycleTime" BO_ 2589283612 1000;
BA_ "MsgType" BO_ 2583733765 4;
BA_ "MsgType" BO_ 2583864837 4;
BA_ "GenMsgSendType" BO_ 1140 0;
BA_ "GenMsgILSupport" BO_ 1140 1;
BA_ "GenMsgDelayTime" BO_ 1140 40;
BA_ "GenMsgCycleTime" BO_ 1140 1000;
BA_ "GenMsgSendType" BO_ 2589283603 0;
BA_ "GenMsgILSupport" BO_ 2589283603 1;
BA_ "GenMsgDelayTime" BO_ 2589283603 40;
BA_ "GenMsgCycleTime" BO_ 2589283603 1000;
BA_ "GenSigSwitchedByIgnition" SG_ 2600468650 NM_SCC1_SNI 0;
BA_ "GenSigStartValue" SG_ 2600468650 NM_SCC1_SNI 170;
BA_ "GenSigSwitchedByIgnition" SG_ 2600468650 NM_SCC1_CBV_AWB 0;
BA_ "GenSigSwitchedByIgnition" SG_ 2600468650 NM_SCC1_CBV_CRI 0;
BA_ "GenSigSwitchedByIgnition" SG_ 2600468650 NM_SCC1_NM_State 0;
BA_ "GenSigSwitchedByIgnition" SG_ 2600468650 NM_SCC1_Car_Wakeup 0;
BA_ "GenSigSwitchedByIgnition" SG_ 2600468650 NM_SCC1_UDS_CC 0;
BA_ "GenSigSwitchedByIgnition" SG_ 2600468650 NM_SCC1_NM_aktiv_KL15 0;
BA_ "GenSigSwitchedByIgnition" SG_ 2600468650 NM_SCC1_NM_aktiv_Diagnose 0;
BA_ "GenSigSwitchedByIgnition" SG_ 2600468650 NM_SCC1_NM_aktiv_Tmin 0;
BA_ "GenSigSwitchedByIgnition" SG_ 2600468650 NM_SCC1_NM_aktiv_MIBCAN 0;
BA_ "GenSigSwitchedByIgnition" SG_ 2600468650 NM_SCC1_CAB 0;
BA_ "GenSigSwitchedByIgnition" SG_ 2600468651 NM_SCC2_SNI 0;
BA_ "GenSigStartValue" SG_ 2600468651 NM_SCC2_SNI 170;
BA_ "GenSigSwitchedByIgnition" SG_ 2600468651 NM_SCC2_CBV_AWB 0;
BA_ "GenSigSwitchedByIgnition" SG_ 2600468651 NM_SCC2_CBV_CRI 0;
BA_ "GenSigSwitchedByIgnition" SG_ 2600468651 NM_SCC2_NM_State 0;
BA_ "GenSigSwitchedByIgnition" SG_ 2600468651 NM_SCC2_Car_Wakeup 0;
BA_ "GenSigSwitchedByIgnition" SG_ 2600468651 NM_SCC2_UDS_CC 0;
BA_ "GenSigSwitchedByIgnition" SG_ 2600468651 NM_SCC2_NM_aktiv_KL15 0;
BA_ "GenSigSwitchedByIgnition" SG_ 2600468651 NM_SCC2_NM_aktiv_Diagnose 0;
BA_ "GenSigSwitchedByIgnition" SG_ 2600468651 NM_SCC2_NM_aktiv_Tmin 0;
BA_ "GenSigSwitchedByIgnition" SG_ 2600468651 NM_SCC2_NM_aktiv_MIBCAN 0;
BA_ "GenSigSwitchedByIgnition" SG_ 2600468651 NM_SCC2_CAB 0;
BA_ "GenSigSwitchedByIgnition" SG_ 2600468647 NM_SDC1_SNI 0;
BA_ "GenSigStartValue" SG_ 2600468647 NM_SDC1_SNI 167;
BA_ "GenSigSwitchedByIgnition" SG_ 2600468647 NM_SDC1_CBV_AWB 0;
BA_ "GenSigSwitchedByIgnition" SG_ 2600468647 NM_SDC1_CBV_CRI 0;
BA_ "GenSigSwitchedByIgnition" SG_ 2600468647 NM_SDC1_NM_State 0;
BA_ "GenSigSwitchedByIgnition" SG_ 2600468647 NM_SDC1_Car_Wakeup 0;
BA_ "GenSigSwitchedByIgnition" SG_ 2600468647 NM_SDC1_UDS_CC 0;
BA_ "GenSigSwitchedByIgnition" SG_ 2600468647 NM_SDC1_NM_aktiv_KL15 0;
BA_ "GenSigSwitchedByIgnition" SG_ 2600468647 NM_SDC1_NM_aktiv_Diagnose 0;
BA_ "GenSigSwitchedByIgnition" SG_ 2600468647 NM_SDC1_NM_aktiv_Tmin 0;
BA_ "GenSigSwitchedByIgnition" SG_ 2600468647 NM_SDC1_NM_aktiv_MIBCAN 0;
BA_ "GenSigSwitchedByIgnition" SG_ 2600468647 NM_SDC1_CAB 0;
BA_ "GenSigSwitchedByIgnition" SG_ 2600468648 NM_SDC2_SNI 0;
BA_ "GenSigStartValue" SG_ 2600468648 NM_SDC2_SNI 168;
BA_ "GenSigSwitchedByIgnition" SG_ 2600468648 NM_SDC2_CBV_AWB 0;
BA_ "GenSigSwitchedByIgnition" SG_ 2600468648 NM_SDC2_CBV_CRI 0;
BA_ "GenSigSwitchedByIgnition" SG_ 2600468648 NM_SDC2_NM_State 0;
BA_ "GenSigSwitchedByIgnition" SG_ 2600468648 NM_SDC2_Car_Wakeup 0;
BA_ "GenSigSwitchedByIgnition" SG_ 2600468648 NM_SDC2_UDS_CC 0;
BA_ "GenSigSwitchedByIgnition" SG_ 2600468648 NM_SDC2_NM_aktiv_KL15 0;
BA_ "GenSigSwitchedByIgnition" SG_ 2600468648 NM_SDC2_NM_aktiv_Diagnose 0;
BA_ "GenSigSwitchedByIgnition" SG_ 2600468648 NM_SDC2_NM_aktiv_Tmin 0;
BA_ "GenSigSwitchedByIgnition" SG_ 2600468648 NM_SDC2_NM_aktiv_MIBCAN 0;
BA_ "GenSigSwitchedByIgnition" SG_ 2600468648 NM_SDC2_CAB 0;
BA_ "GenSigSwitchedByIgnition" SG_ 2600468527 NM_SFA_SNI 0;
BA_ "GenSigStartValue" SG_ 2600468527 NM_SFA_SNI 47;
BA_ "GenSigSwitchedByIgnition" SG_ 2600468527 NM_SFA_NM_State 0;
BA_ "GenSigSwitchedByIgnition" SG_ 2600468527 NM_SFA_Car_Wakeup 0;
BA_ "GenSigSwitchedByIgnition" SG_ 2600468527 NM_SFA_Wakeup 0;
BA_ "NWM-WakeupAllowed" SG_ 2600468527 NM_SFA_Wakeup 1;
BA_ "GenSigSwitchedByIgnition" SG_ 2600468527 NM_SFA_NM_aktiv_KL15 0;
BA_ "GenSigSwitchedByIgnition" SG_ 2600468527 NM_SFA_NM_aktiv_Diagnose 0;
BA_ "GenSigSwitchedByIgnition" SG_ 2600468527 NM_SFA_NM_aktiv_Tmin 0;
BA_ "GenSigSwitchedByIgnition" SG_ 2600468527 NM_SFA_UDS_CC 0;
BA_ "GenSigSwitchedByIgnition" SG_ 2600468645 NM_WLC1_SNI 0;
BA_ "GenSigStartValue" SG_ 2600468645 NM_WLC1_SNI 165;
BA_ "GenSigSwitchedByIgnition" SG_ 2600468645 NM_WLC1_CBV_AWB 0;
BA_ "GenSigSwitchedByIgnition" SG_ 2600468645 NM_WLC1_CBV_CRI 0;
BA_ "GenSigSwitchedByIgnition" SG_ 2600468645 NM_WLC1_NM_State 0;
BA_ "GenSigSwitchedByIgnition" SG_ 2600468645 NM_WLC1_Car_Wakeup 0;
BA_ "GenSigSwitchedByIgnition" SG_ 2600468645 NM_WLC1_UDS_CC 0;
BA_ "GenSigSwitchedByIgnition" SG_ 2600468645 NM_WLC1_NM_aktiv_KL15 0;
BA_ "GenSigSwitchedByIgnition" SG_ 2600468645 NM_WLC1_aktiv_Diagnose 0;
BA_ "GenSigSwitchedByIgnition" SG_ 2600468645 NM_WLC1_aktiv_Tmin 0;
BA_ "GenSigSwitchedByIgnition" SG_ 2600468645 NM_WLC1_NM_aktiv_MIBCAN 0;
BA_ "GenSigSwitchedByIgnition" SG_ 2600468645 NM_WLC1_CAB 0;
BA_ "GenSigSwitchedByIgnition" SG_ 2600468646 NM_WLC2_SNI 0;
BA_ "GenSigStartValue" SG_ 2600468646 NM_WLC2_SNI 166;
BA_ "GenSigSwitchedByIgnition" SG_ 2600468646 NM_WLC2_CBV_AWB 0;
BA_ "GenSigSwitchedByIgnition" SG_ 2600468646 NM_WLC2_CBV_CRI 0;
BA_ "GenSigSwitchedByIgnition" SG_ 2600468646 NM_WLC2_NM_State 0;
BA_ "GenSigSwitchedByIgnition" SG_ 2600468646 NM_WLC2_Car_Wakeup 0;
BA_ "GenSigSwitchedByIgnition" SG_ 2600468646 NM_WLC2_UDS_CC 0;
BA_ "GenSigSwitchedByIgnition" SG_ 2600468646 NM_WLC2_NM_aktiv_KL15 0;
BA_ "GenSigSwitchedByIgnition" SG_ 2600468646 NM_WLC2_aktiv_Diagnose 0;
BA_ "GenSigSwitchedByIgnition" SG_ 2600468646 NM_WLC2_aktiv_Tmin 0;
BA_ "GenSigSwitchedByIgnition" SG_ 2600468646 NM_WLC2_NM_aktiv_MIBCAN 0;
BA_ "GenSigSwitchedByIgnition" SG_ 2600468646 NM_WLC2_CAB 0;
BA_ "GenSigSwitchedByIgnition" SG_ 2549875370 OBDC_SCC1_Req_Data 0;
BA_ "GenSigSendType" SG_ 2549875370 OBDC_SCC1_Req_Data 3;
BA_ "GenSigSwitchedByIgnition" SG_ 2550006442 OBDC_SCC1_Resp_Data 0;
BA_ "GenSigSendType" SG_ 2550006442 OBDC_SCC1_Resp_Data 3;
BA_ "GenSigSwitchedByIgnition" SG_ 2549875371 OBDC_SCC2_Req_Data 0;
BA_ "GenSigSendType" SG_ 2549875371 OBDC_SCC2_Req_Data 3;
BA_ "GenSigSwitchedByIgnition" SG_ 2550006443 OBDC_SCC2_Resp_Data 0;
BA_ "GenSigSendType" SG_ 2550006443 OBDC_SCC2_Resp_Data 3;
BA_ "GenSigSwitchedByIgnition" SG_ 2549875367 OBDC_SDC1_Req_Data 0;
BA_ "GenSigSendType" SG_ 2549875367 OBDC_SDC1_Req_Data 3;
BA_ "GenSigSwitchedByIgnition" SG_ 2550006439 OBDC_SDC1_Resp_Data 0;
BA_ "GenSigSendType" SG_ 2550006439 OBDC_SDC1_Resp_Data 3;
BA_ "GenSigSwitchedByIgnition" SG_ 2549875368 OBDC_SDC2_Req_Data 0;
BA_ "GenSigSendType" SG_ 2549875368 OBDC_SDC2_Req_Data 3;
BA_ "GenSigSwitchedByIgnition" SG_ 2550006440 OBDC_SDC2_Resp_Data 0;
BA_ "GenSigSendType" SG_ 2550006440 OBDC_SDC2_Resp_Data 3;
BA_ "GenSigSwitchedByIgnition" SG_ 2549875365 OBDC_WLC1_Req_Data 0;
BA_ "GenSigSwitchedByIgnition" SG_ 2550006437 OBDC_WLC1_Resp_Data 0;
BA_ "GenSigSwitchedByIgnition" SG_ 2549875366 OBDC_WLC2_Req_Data 0;
BA_ "GenSigSwitchedByIgnition" SG_ 2550006438 OBDC_WLC2_Resp_Data 0;
BA_ "GenSigSendType" SG_ 2589283656 ORU_Warnung 3;
BA_ "GenSigSwitchedByIgnition" SG_ 2589283656 ORU_Status 0;
BA_ "GenSigSendType" SG_ 2589283656 ORU_Status 3;
BA_ "GenSigSwitchedByIgnition" SG_ 1616 RA_Radio_on 0;
BA_ "GenSigSwitchedByIgnition" SG_ 1616 RA_PowerAmpOn 0;
BA_ "GenSigSwitchedByIgnition" SG_ 1616 RA_Radio_mute 0;
BA_ "GenSigSwitchedByIgnition" SG_ 1616 RA_VNC_OFF 0;
BA_ "GenSigSwitchedByIgnition" SG_ 1616 RA_Radio_Surround 0;
BA_ "GenSigSwitchedByIgnition" SG_ 1616 RA_Frequency 0;
BA_ "GenSigSwitchedByIgnition" SG_ 1616 RA_Frequency_unit 0;
BA_ "GenSigSwitchedByIgnition" SG_ 1616 RA_AM_Tuning 0;
BA_ "GenSigSwitchedByIgnition" SG_ 1350 MMI_on_angefordert 0;
BA_ "GenSigSendType" SG_ 1350 MMI_on_angefordert 3;
BA_ "GenSigSwitchedByIgnition" SG_ 2589283480 SDC1_Variante 0;
BA_ "GenSigSendType" SG_ 2589283480 SDC1_Variante 3;
BA_ "GenSigSwitchedByIgnition" SG_ 2589283480 SDC1_Powerstate 0;
BA_ "GenSigSendType" SG_ 2589283480 SDC1_Powerstate 3;
BA_ "GenSigSwitchedByIgnition" SG_ 2589283480 SDC1_Q_Critical 0;
BA_ "GenSigSendType" SG_ 2589283480 SDC1_Q_Critical 3;
BA_ "GenSigSwitchedByIgnition" SG_ 2589283480 SDC1_LastOn 0;
BA_ "GenSigSendType" SG_ 2589283480 SDC1_LastOn 3;
BA_ "GenSigSwitchedByIgnition" SG_ 2589283480 SDC1_SystemMode 0;
BA_ "GenSigSendType" SG_ 2589283480 SDC1_SystemMode 3;
BA_ "Fehlerwert" SG_ 2589283480 SDC1_KL_30F 255;
BA_ "GenSigSwitchedByIgnition" SG_ 2589283480 SDC1_KL_30F 0;
BA_ "GenSigStartValue" SG_ 2589283480 SDC1_KL_30F 254;
BA_ "GenSigSendType" SG_ 2589283480 SDC1_KL_30F 0;
BA_ "Fehlerwert" SG_ 2589283480 SDC1_TempSens 255;
BA_ "GenSigSwitchedByIgnition" SG_ 2589283480 SDC1_TempSens 0;
BA_ "GenSigStartValue" SG_ 2589283480 SDC1_TempSens 254;
BA_ "GenSigSendType" SG_ 2589283480 SDC1_TempSens 0;
BA_ "Fehlerwert" SG_ 2589283480 SDC1_TempSensMax 255;
BA_ "GenSigSwitchedByIgnition" SG_ 2589283480 SDC1_TempSensMax 0;
BA_ "GenSigStartValue" SG_ 2589283480 SDC1_TempSensMax 254;
BA_ "GenSigSendType" SG_ 2589283480 SDC1_TempSensMax 0;
BA_ "GenSigSwitchedByIgnition" SG_ 2589283482 SDC2_Variante 0;
BA_ "GenSigSendType" SG_ 2589283482 SDC2_Variante 3;
BA_ "GenSigSwitchedByIgnition" SG_ 2589283482 SDC2_Powerstate 0;
BA_ "GenSigSendType" SG_ 2589283482 SDC2_Powerstate 3;
BA_ "GenSigSwitchedByIgnition" SG_ 2589283482 SDC2_Q_Critical 0;
BA_ "GenSigSendType" SG_ 2589283482 SDC2_Q_Critical 3;
BA_ "GenSigSwitchedByIgnition" SG_ 2589283482 SDC2_LastOn 0;
BA_ "GenSigSendType" SG_ 2589283482 SDC2_LastOn 3;
BA_ "GenSigSwitchedByIgnition" SG_ 2589283482 SDC2_SystemMode 0;
BA_ "GenSigSendType" SG_ 2589283482 SDC2_SystemMode 3;
BA_ "Fehlerwert" SG_ 2589283482 SDC2_KL_30F 255;
BA_ "GenSigSwitchedByIgnition" SG_ 2589283482 SDC2_KL_30F 0;
BA_ "GenSigStartValue" SG_ 2589283482 SDC2_KL_30F 254;
BA_ "GenSigSendType" SG_ 2589283482 SDC2_KL_30F 0;
BA_ "Fehlerwert" SG_ 2589283482 SDC2_TempSens 255;
BA_ "GenSigSwitchedByIgnition" SG_ 2589283482 SDC2_TempSens 0;
BA_ "GenSigStartValue" SG_ 2589283482 SDC2_TempSens 254;
BA_ "GenSigSendType" SG_ 2589283482 SDC2_TempSens 0;
BA_ "Fehlerwert" SG_ 2589283482 SDC2_TempSensMax 255;
BA_ "GenSigSwitchedByIgnition" SG_ 2589283482 SDC2_TempSensMax 0;
BA_ "GenSigStartValue" SG_ 2589283482 SDC2_TempSensMax 254;
BA_ "GenSigSendType" SG_ 2589283482 SDC2_TempSensMax 0;
BA_ "GenSigSwitchedByIgnition" SG_ 2589283486 SCC_State 0;
BA_ "GenSigSendType" SG_ 2589283486 SCC_State 3;
BA_ "GenSigSwitchedByIgnition" SG_ 2589283486 SystemMode 0;
BA_ "GenSigSendType" SG_ 2589283486 SystemMode 3;
BA_ "Fehlerwert" SG_ 2589283486 SCC_Temp_Fehler 1;
BA_ "GenSigSwitchedByIgnition" SG_ 2589283486 SCC_Temp_Fehler 0;
BA_ "GenSigSendType" SG_ 2589283486 SCC_Temp_Fehler 3;
BA_ "Fehlerwert" SG_ 2589283486 SCC_KL30_Uebersp_Fehler 1;
BA_ "GenSigSwitchedByIgnition" SG_ 2589283486 SCC_KL30_Uebersp_Fehler 0;
BA_ "GenSigSendType" SG_ 2589283486 SCC_KL30_Uebersp_Fehler 3;
BA_ "Fehlerwert" SG_ 2589283486 SCC_KL30_Untersp_Fehler 1;
BA_ "GenSigSwitchedByIgnition" SG_ 2589283486 SCC_KL30_Untersp_Fehler 0;
BA_ "GenSigSendType" SG_ 2589283486 SCC_KL30_Untersp_Fehler 3;
BA_ "Fehlerwert" SG_ 2589283486 SCC_KL_30F 255;
BA_ "GenSigSwitchedByIgnition" SG_ 2589283486 SCC_KL_30F 0;
BA_ "GenSigStartValue" SG_ 2589283486 SCC_KL_30F 254;
BA_ "GenSigSendType" SG_ 2589283486 SCC_KL_30F 0;
BA_ "Fehlerwert" SG_ 2589283486 SCC_TempSens 255;
BA_ "GenSigSwitchedByIgnition" SG_ 2589283486 SCC_TempSens 0;
BA_ "GenSigStartValue" SG_ 2589283486 SCC_TempSens 254;
BA_ "GenSigSendType" SG_ 2589283486 SCC_TempSens 0;
BA_ "Fehlerwert" SG_ 2589283486 SCC_TempSensMax 255;
BA_ "GenSigSwitchedByIgnition" SG_ 2589283486 SCC_TempSensMax 0;
BA_ "GenSigStartValue" SG_ 2589283486 SCC_TempSensMax 254;
BA_ "GenSigSendType" SG_ 2589283486 SCC_TempSensMax 0;
BA_ "GenSigSwitchedByIgnition" SG_ 2589283486 SCC_Variant 0;
BA_ "GenSigStartValue" SG_ 2589283486 SCC_Variant 254;
BA_ "GenSigSendType" SG_ 2589283486 SCC_Variant 0;
BA_ "GenSigSwitchedByIgnition" SG_ 2589283486 SCC1_Powerstate 0;
BA_ "Fehlerwert" SG_ 2589283487 EEPROM_Fehler 1;
BA_ "GenSigSwitchedByIgnition" SG_ 2589283487 EEPROM_Fehler 0;
BA_ "GenSigSendType" SG_ 2589283487 EEPROM_Fehler 3;
BA_ "GenSigSwitchedByIgnition" SG_ 2589283488 SCC_State 0;
BA_ "GenSigSendType" SG_ 2589283488 SCC_State 3;
BA_ "GenSigSwitchedByIgnition" SG_ 2589283488 SystemMode 0;
BA_ "GenSigSendType" SG_ 2589283488 SystemMode 3;
BA_ "Fehlerwert" SG_ 2589283488 SCC_Temp_Fehler 1;
BA_ "GenSigSwitchedByIgnition" SG_ 2589283488 SCC_Temp_Fehler 0;
BA_ "GenSigSendType" SG_ 2589283488 SCC_Temp_Fehler 3;
BA_ "Fehlerwert" SG_ 2589283488 SCC_KL30_Uebersp_Fehler 1;
BA_ "GenSigSwitchedByIgnition" SG_ 2589283488 SCC_KL30_Uebersp_Fehler 0;
BA_ "GenSigSendType" SG_ 2589283488 SCC_KL30_Uebersp_Fehler 3;
BA_ "Fehlerwert" SG_ 2589283488 SCC_KL30_Untersp_Fehler 1;
BA_ "GenSigSwitchedByIgnition" SG_ 2589283488 SCC_KL30_Untersp_Fehler 0;
BA_ "GenSigSendType" SG_ 2589283488 SCC_KL30_Untersp_Fehler 3;
BA_ "Fehlerwert" SG_ 2589283488 SCC_KL_30F 255;
BA_ "GenSigSwitchedByIgnition" SG_ 2589283488 SCC_KL_30F 0;
BA_ "GenSigStartValue" SG_ 2589283488 SCC_KL_30F 254;
BA_ "GenSigSendType" SG_ 2589283488 SCC_KL_30F 0;
BA_ "Fehlerwert" SG_ 2589283488 SCC_TempSens 255;
BA_ "GenSigSwitchedByIgnition" SG_ 2589283488 SCC_TempSens 0;
BA_ "GenSigStartValue" SG_ 2589283488 SCC_TempSens 254;
BA_ "GenSigSendType" SG_ 2589283488 SCC_TempSens 0;
BA_ "Fehlerwert" SG_ 2589283488 SCC_TempSensMax 255;
BA_ "GenSigSwitchedByIgnition" SG_ 2589283488 SCC_TempSensMax 0;
BA_ "GenSigStartValue" SG_ 2589283488 SCC_TempSensMax 254;
BA_ "GenSigSendType" SG_ 2589283488 SCC_TempSensMax 0;
BA_ "GenSigSwitchedByIgnition" SG_ 2589283488 SCC_Variant 0;
BA_ "GenSigStartValue" SG_ 2589283488 SCC_Variant 254;
BA_ "GenSigSendType" SG_ 2589283488 SCC_Variant 0;
BA_ "GenSigSwitchedByIgnition" SG_ 2589283488 SCC2_Powerstate 0;
BA_ "Fehlerwert" SG_ 2589283489 EEPROM_Fehler 1;
BA_ "GenSigSwitchedByIgnition" SG_ 2589283489 EEPROM_Fehler 0;
BA_ "GenSigSendType" SG_ 2589283489 EEPROM_Fehler 3;
BA_ "GenSigSwitchedByIgnition" SG_ 2549876209 SWDL_ABT_1_Req_Data 0;
BA_ "GenSigSendType" SG_ 2549876209 SWDL_ABT_1_Req_Data 3;
BA_ "GenSigSwitchedByIgnition" SG_ 2550007281 SWDL_ABT_1_Resp_Data 0;
BA_ "GenSigFuncType" SG_ 2550007281 SWDL_ABT_1_Resp_Data 9;
BA_ "GenSigSendType" SG_ 2550007281 SWDL_ABT_1_Resp_Data 3;
BA_ "GenSigSwitchedByIgnition" SG_ 2549876208 SWDL_BT_1_Req_Data 0;
BA_ "GenSigSendType" SG_ 2549876208 SWDL_BT_1_Req_Data 3;
BA_ "GenSigSwitchedByIgnition" SG_ 2550007280 SWDL_BT_1_Resp_Data 0;
BA_ "GenSigFuncType" SG_ 2550007280 SWDL_BT_1_Resp_Data 9;
BA_ "GenSigSendType" SG_ 2550007280 SWDL_BT_1_Resp_Data 3;
BA_ "GenSigSwitchedByIgnition" SG_ 2549876210 SWDL_DU_1_Req_Data 0;
BA_ "GenSigSendType" SG_ 2549876210 SWDL_DU_1_Req_Data 3;
BA_ "GenSigSwitchedByIgnition" SG_ 2550007282 SWDL_DU_1_Resp_Data 0;
BA_ "GenSigFuncType" SG_ 2550007282 SWDL_DU_1_Resp_Data 9;
BA_ "GenSigSendType" SG_ 2550007282 SWDL_DU_1_Resp_Data 3;
BA_ "GenSigSwitchedByIgnition" SG_ 2549876213 SWDL_DU_2_Req_Data 0;
BA_ "GenSigSwitchedByIgnition" SG_ 2550007285 SWDL_DU_2_Resp_Data 0;
BA_ "GenSigFuncType" SG_ 2550007285 SWDL_DU_2_Resp_Data 9;
BA_ "GenSigSwitchedByIgnition" SG_ 2549876222 SWDL_DU_3_Req_Data 0;
BA_ "GenSigSwitchedByIgnition" SG_ 2550007294 SWDL_DU_3_Resp_Data 0;
BA_ "GenSigSwitchedByIgnition" SG_ 2549876212 SWDL_DU_4_Req_Data 0;
BA_ "GenSigSendType" SG_ 2549876212 SWDL_DU_4_Req_Data 3;
BA_ "GenSigSwitchedByIgnition" SG_ 2550007284 SWDL_DU_4_Resp_Data 0;
BA_ "GenSigSendType" SG_ 2550007284 SWDL_DU_4_Resp_Data 3;
BA_ "GenSigSwitchedByIgnition" SG_ 2549876214 SWDL_LSR_1_Req_Data 0;
BA_ "GenSigSwitchedByIgnition" SG_ 2550007286 SWDL_LSR_1_Resp_Data 0;
BA_ "GenSigFuncType" SG_ 2550007286 SWDL_LSR_1_Resp_Data 9;
BA_ "GenSigSwitchedByIgnition" SG_ 2549876138 SWDL_SCC1_Req_Data 0;
BA_ "GenSigSendType" SG_ 2549876138 SWDL_SCC1_Req_Data 3;
BA_ "GenSigSwitchedByIgnition" SG_ 2550007210 SWDL_SCC1_Resp_Data 0;
BA_ "GenSigSendType" SG_ 2550007210 SWDL_SCC1_Resp_Data 3;
BA_ "GenSigSwitchedByIgnition" SG_ 2549876139 SWDL_SCC2_Req_Data 0;
BA_ "GenSigSendType" SG_ 2549876139 SWDL_SCC2_Req_Data 3;
BA_ "GenSigSwitchedByIgnition" SG_ 2550007211 SWDL_SCC2_Resp_Data 0;
BA_ "GenSigSendType" SG_ 2550007211 SWDL_SCC2_Resp_Data 3;
BA_ "GenSigSwitchedByIgnition" SG_ 2549876135 SWDL_SDC1_Req_Data 0;
BA_ "GenSigSendType" SG_ 2549876135 SWDL_SDC1_Req_Data 3;
BA_ "GenSigSwitchedByIgnition" SG_ 2550007207 SWDL_SDC1_Resp_Data 0;
BA_ "GenSigSendType" SG_ 2550007207 SWDL_SDC1_Resp_Data 3;
BA_ "GenSigSwitchedByIgnition" SG_ 2549876136 SWDL_SDC2_Req_Data 0;
BA_ "GenSigSendType" SG_ 2549876136 SWDL_SDC2_Req_Data 3;
BA_ "GenSigSwitchedByIgnition" SG_ 2550007208 SWDL_SDC2_Resp_Data 0;
BA_ "GenSigSendType" SG_ 2550007208 SWDL_SDC2_Resp_Data 3;
BA_ "GenSigSwitchedByIgnition" SG_ 2549876133 SWDL_WLC1_Req 0;
BA_ "GenSigSwitchedByIgnition" SG_ 2550007205 SWDL_WLC1_Resp 0;
BA_ "GenSigFuncType" SG_ 2550007205 SWDL_WLC1_Resp 9;
BA_ "GenSigSwitchedByIgnition" SG_ 2549876134 SWDL_WLC2_Req 0;
BA_ "GenSigSwitchedByIgnition" SG_ 2550007206 SWDL_WLC2_Resp 0;
BA_ "GenSigFuncType" SG_ 2550007206 SWDL_WLC2_Resp 9;
BA_ "GenSigSwitchedByIgnition" SG_ 1413 SI_Sammel_SG_Fehler 0;
BA_ "GenSigStartValue" SG_ 1413 SI_Sammel_SG_Fehler 63;
BA_ "GenSigSendType" SG_ 1413 SI_Sammel_SG_Fehler 0;
BA_ "GenSigSwitchedByIgnition" SG_ 1413 SI_P_Mode_gueltig 0;
BA_ "GenSigSendType" SG_ 1413 SI_P_Mode_gueltig 3;
BA_ "GenSigSwitchedByIgnition" SG_ 1413 SI_Diagnose_Aktiv 0;
BA_ "GenSigSendType" SG_ 1413 SI_Diagnose_Aktiv 3;
BA_ "GenSigSwitchedByIgnition" SG_ 1413 SI_QRS_Mode 0;
BA_ "GenSigSendType" SG_ 1413 SI_QRS_Mode 3;
BA_ "GenSigSwitchedByIgnition" SG_ 1413 SI_T_Mode 0;
BA_ "GenSigSendType" SG_ 1413 SI_T_Mode 3;
BA_ "GenSigSwitchedByIgnition" SG_ 1413 SI_NWDF 0;
BA_ "GenSigSendType" SG_ 1413 SI_NWDF 3;
BA_ "GenSigSwitchedByIgnition" SG_ 1413 SI_NWDF_gueltig 0;
BA_ "GenSigFuncType" SG_ 1413 SI_NWDF_gueltig 8;
BA_ "GenSigSendType" SG_ 1413 SI_NWDF_gueltig 3;
BA_ "GenSigSwitchedByIgnition" SG_ 1413 SI_Sammelfehler 0;
BA_ "GenSigSendType" SG_ 1413 SI_Sammelfehler 3;
BA_ "GenSigSendType" SG_ 1413 GW_KD_Fehler 3;
BA_ "GenSigSwitchedByIgnition" SG_ 1413 SI_T_Schutz 0;
BA_ "GenSigSendType" SG_ 1413 SI_T_Schutz 3;
BA_ "GenSigSwitchedByIgnition" SG_ 1413 SI_P_Mode 0;
BA_ "GenSigSendType" SG_ 1413 SI_P_Mode 3;
BA_ "GenSigSwitchedByIgnition" SG_ 1413 SI_BUS_01 0;
BA_ "GenSigStartValue" SG_ 1413 SI_BUS_01 1;
BA_ "GenSigSendType" SG_ 1413 SI_BUS_01 3;
BA_ "GenSigSwitchedByIgnition" SG_ 1413 SI_BUS_02 0;
BA_ "GenSigStartValue" SG_ 1413 SI_BUS_02 1;
BA_ "GenSigSendType" SG_ 1413 SI_BUS_02 3;
BA_ "GenSigSwitchedByIgnition" SG_ 1413 SI_BUS_03 0;
BA_ "GenSigStartValue" SG_ 1413 SI_BUS_03 1;
BA_ "GenSigSendType" SG_ 1413 SI_BUS_03 3;
BA_ "GenSigSwitchedByIgnition" SG_ 1413 SI_BUS_04 0;
BA_ "GenSigStartValue" SG_ 1413 SI_BUS_04 1;
BA_ "GenSigSendType" SG_ 1413 SI_BUS_04 3;
BA_ "GenSigSwitchedByIgnition" SG_ 1413 SI_BUS_05 0;
BA_ "GenSigStartValue" SG_ 1413 SI_BUS_05 1;
BA_ "GenSigSendType" SG_ 1413 SI_BUS_05 3;
BA_ "GenSigSwitchedByIgnition" SG_ 1413 SI_BUS_06 0;
BA_ "GenSigStartValue" SG_ 1413 SI_BUS_06 1;
BA_ "GenSigSendType" SG_ 1413 SI_BUS_06 3;
BA_ "GenSigSwitchedByIgnition" SG_ 1413 SI_BUS_07 0;
BA_ "GenSigStartValue" SG_ 1413 SI_BUS_07 1;
BA_ "GenSigSendType" SG_ 1413 SI_BUS_07 3;
BA_ "GenSigSwitchedByIgnition" SG_ 1413 SI_BUS_08 0;
BA_ "GenSigStartValue" SG_ 1413 SI_BUS_08 1;
BA_ "GenSigSendType" SG_ 1413 SI_BUS_08 3;
BA_ "GenSigSwitchedByIgnition" SG_ 1413 SI_BUS_09 0;
BA_ "GenSigStartValue" SG_ 1413 SI_BUS_09 1;
BA_ "GenSigSendType" SG_ 1413 SI_BUS_09 3;
BA_ "GenSigSwitchedByIgnition" SG_ 1413 SI_BUS_10 0;
BA_ "GenSigStartValue" SG_ 1413 SI_BUS_10 1;
BA_ "GenSigSendType" SG_ 1413 SI_BUS_10 3;
BA_ "GenSigSwitchedByIgnition" SG_ 1413 SI_BUS_11 0;
BA_ "GenSigStartValue" SG_ 1413 SI_BUS_11 1;
BA_ "GenSigSendType" SG_ 1413 SI_BUS_11 3;
BA_ "GenSigSwitchedByIgnition" SG_ 1413 SI_BUS_12 0;
BA_ "GenSigStartValue" SG_ 1413 SI_BUS_12 1;
BA_ "GenSigSendType" SG_ 1413 SI_BUS_12 3;
BA_ "GenSigSwitchedByIgnition" SG_ 1413 SI_BUS_13 0;
BA_ "GenSigStartValue" SG_ 1413 SI_BUS_13 1;
BA_ "GenSigSendType" SG_ 1413 SI_BUS_13 3;
BA_ "GenSigSwitchedByIgnition" SG_ 1413 SI_BUS_14 0;
BA_ "GenSigStartValue" SG_ 1413 SI_BUS_14 1;
BA_ "GenSigSendType" SG_ 1413 SI_BUS_14 3;
BA_ "GenSigSwitchedByIgnition" SG_ 1413 SI_BUS_15 0;
BA_ "GenSigStartValue" SG_ 1413 SI_BUS_15 1;
BA_ "GenSigSendType" SG_ 1413 SI_BUS_15 3;
BA_ "GenSigSwitchedByIgnition" SG_ 1413 SI_Bus_Identifikation 0;
BA_ "GenSigSendType" SG_ 1413 SI_Bus_Identifikation 0;
BA_ "GenSigSwitchedByIgnition" SG_ 1716 VIN_01_MUX 0;
BA_ "GenSigSwitchedByIgnition" SG_ 1716 KS_Geheimnis_1 0;
BA_ "GenSigSwitchedByIgnition" SG_ 1716 VIN_4 0;
BA_ "GenSigStartValue" SG_ 1716 VIN_4 45;
BA_ "GenSigSwitchedByIgnition" SG_ 1716 VIN_11 0;
BA_ "GenSigStartValue" SG_ 1716 VIN_11 45;
BA_ "GenSigSwitchedByIgnition" SG_ 1716 KS_Geheimnis_2 0;
BA_ "GenSigSwitchedByIgnition" SG_ 1716 VIN_5 0;
BA_ "GenSigStartValue" SG_ 1716 VIN_5 45;
BA_ "GenSigSwitchedByIgnition" SG_ 1716 VIN_12 0;
BA_ "GenSigStartValue" SG_ 1716 VIN_12 45;
BA_ "GenSigSwitchedByIgnition" SG_ 1716 KS_Geheimnis_3 0;
BA_ "GenSigSwitchedByIgnition" SG_ 1716 VIN_6 0;
BA_ "GenSigStartValue" SG_ 1716 VIN_6 45;
BA_ "GenSigSwitchedByIgnition" SG_ 1716 VIN_13 0;
BA_ "GenSigStartValue" SG_ 1716 VIN_13 45;
BA_ "GenSigSwitchedByIgnition" SG_ 1716 KS_Geheimnis_4 0;
BA_ "GenSigSwitchedByIgnition" SG_ 1716 VIN_7 0;
BA_ "GenSigStartValue" SG_ 1716 VIN_7 45;
BA_ "GenSigSwitchedByIgnition" SG_ 1716 VIN_14 0;
BA_ "GenSigStartValue" SG_ 1716 VIN_14 45;
BA_ "GenSigSwitchedByIgnition" SG_ 1716 VIN_1 0;
BA_ "GenSigStartValue" SG_ 1716 VIN_1 45;
BA_ "GenSigSwitchedByIgnition" SG_ 1716 VIN_8 0;
BA_ "GenSigStartValue" SG_ 1716 VIN_8 45;
BA_ "GenSigSwitchedByIgnition" SG_ 1716 VIN_15 0;
BA_ "GenSigStartValue" SG_ 1716 VIN_15 45;
BA_ "GenSigSwitchedByIgnition" SG_ 1716 VIN_2 0;
BA_ "GenSigStartValue" SG_ 1716 VIN_2 45;
BA_ "GenSigSwitchedByIgnition" SG_ 1716 VIN_9 0;
BA_ "GenSigStartValue" SG_ 1716 VIN_9 45;
BA_ "GenSigSwitchedByIgnition" SG_ 1716 VIN_16 0;
BA_ "GenSigStartValue" SG_ 1716 VIN_16 45;
BA_ "GenSigSwitchedByIgnition" SG_ 1716 VIN_3 0;
BA_ "GenSigStartValue" SG_ 1716 VIN_3 45;
BA_ "GenSigSwitchedByIgnition" SG_ 1716 VIN_10 0;
BA_ "GenSigStartValue" SG_ 1716 VIN_10 45;
BA_ "GenSigSwitchedByIgnition" SG_ 1716 VIN_17 0;
BA_ "GenSigStartValue" SG_ 1716 VIN_17 45;
BA_ "GenSigSwitchedByIgnition" SG_ 916 WBA_03_CRC 0;
BA_ "GenSigFuncType" SG_ 916 WBA_03_CRC 2;
BA_ "GenSigSwitchedByIgnition" SG_ 916 WBA_03_BZ 0;
BA_ "GenSigFuncType" SG_ 916 WBA_03_BZ 1;
BA_ "GenSigSwitchedByIgnition" SG_ 916 WBA_Fahrstufe_02 0;
BA_ "GenSigSwitchedByIgnition" SG_ 916 WBA_ZielFahrstufe 0;
BA_ "GenSigSwitchedByIgnition" SG_ 916 WBA_GE_Warnung_02 0;
BA_ "GenSigSwitchedByIgnition" SG_ 916 WBA_eing_Gang_02 0;
BA_ "GenSigSwitchedByIgnition" SG_ 916 WBA_GE_Texte 0;
BA_ "GenSigSwitchedByIgnition" SG_ 916 WBA_Segeln_aktiv 0;
BA_ "GenSigSwitchedByIgnition" SG_ 916 WBA_Schaltschema 0;
BA_ "GenSigSwitchedByIgnition" SG_ 916 WBA_GE_Zusatzwarnungen 0;
BA_ "GenSigSwitchedByIgnition" SG_ 916 GE_Sollgang 0;
BA_ "GenSigSwitchedByIgnition" SG_ 916 GE_Tipschaltempf_verfuegbar 0;
BA_ "GenSigFuncType" SG_ 916 GE_Tipschaltempf_verfuegbar 8;
BA_ "GenSigSwitchedByIgnition" SG_ 916 WBA_GE_Texte_02 0;
BA_ "GenSigSwitchedByIgnition" SG_ 916 WBA_Blinken 0;
BA_ "GenSigSwitchedByIgnition" SG_ 916 GE_Wiederstart_Anz_Std 0;
BA_ "GenSigSwitchedByIgnition" SG_ 916 GE_Stoppverbot_Anz_01 0;
BA_ "GenSigSwitchedByIgnition" SG_ 916 GE_Stoppverbot_Anz_02 0;
BA_ "GenSigSwitchedByIgnition" SG_ 916 GE_Stoppverbot_Anz_03 0;
BA_ "GenSigSwitchedByIgnition" SG_ 916 GE_Stoppverbot_Anz_04 0;
BA_ "GenSigSwitchedByIgnition" SG_ 916 GE_Stoppverbot_Anz_05 0;
BA_ "GenSigSwitchedByIgnition" SG_ 916 GE_Stoppverbot_Anz_06 0;
BA_ "GenSigSwitchedByIgnition" SG_ 916 GE_Stoppverbot_Anz_07 0;
BA_ "GenSigSwitchedByIgnition" SG_ 916 GE_Stoppverbot_Anz_Std 0;
BA_ "GenSigSwitchedByIgnition" SG_ 2589283611 WLC1_Fehler 0;
BA_ "GenSigSwitchedByIgnition" SG_ 2589283611 WLC1_aktive_Spule 0;
BA_ "GenSigSendType" SG_ 2589283611 WLC1_aktive_Spule 3;
BA_ "GenSigSwitchedByIgnition" SG_ 2589283611 WLC1_Charger_Effizienz 0;
BA_ "GenSigSendType" SG_ 2589283611 WLC1_Charger_Effizienz 3;
BA_ "GenSigSwitchedByIgnition" SG_ 2589283611 WLC1_Charger_laedt 0;
BA_ "GenSigSendType" SG_ 2589283611 WLC1_Charger_laedt 3;
BA_ "GenSigSwitchedByIgnition" SG_ 2589283611 WLC1_Fremdobjekt_erkannt 0;
BA_ "GenSigSendType" SG_ 2589283611 WLC1_Fremdobjekt_erkannt 3;
BA_ "GenSigSwitchedByIgnition" SG_ 2589283611 WLC1_Leistungsklasse_Receiver 0;
BA_ "GenSigSendType" SG_ 2589283611 WLC1_Leistungsklasse_Receiver 0;
BA_ "GenSigSwitchedByIgnition" SG_ 2589283611 WLC1_Objekt_erkannt 0;
BA_ "GenSigSendType" SG_ 2589283611 WLC1_Objekt_erkannt 3;
BA_ "GenSigSwitchedByIgnition" SG_ 2589283611 WLC1_Receiver_erkannt 0;
BA_ "GenSigSendType" SG_ 2589283611 WLC1_Receiver_erkannt 3;
BA_ "GenSigSwitchedByIgnition" SG_ 2589283611 WLC1_Receiver_voll_geladen 0;
BA_ "GenSigSendType" SG_ 2589283611 WLC1_Receiver_voll_geladen 3;
BA_ "GenSigSwitchedByIgnition" SG_ 2589283611 WLC1_verwendeter_Ladestandard 0;
BA_ "GenSigSendType" SG_ 2589283611 WLC1_verwendeter_Ladestandard 0;
BA_ "GenSigSwitchedByIgnition" SG_ 2589283611 WLC1_Temp_Leistungsteil_Charger 0;
BA_ "GenSigSendType" SG_ 2589283611 WLC1_Temp_Leistungsteil_Charger 0;
BA_ "GenSigSwitchedByIgnition" SG_ 2589283611 WLC1_Temp_Oberfaeche_Charger 0;
BA_ "GenSigSendType" SG_ 2589283611 WLC1_Temp_Oberfaeche_Charger 0;
BA_ "GenSigSwitchedByIgnition" SG_ 2589283611 WLC1_Temp_Receiver 0;
BA_ "GenSigSendType" SG_ 2589283611 WLC1_Temp_Receiver 0;
BA_ "GenSigSwitchedByIgnition" SG_ 2583733509 WLC1_SWDL_Req 0;
BA_ "GenSigSwitchedByIgnition" SG_ 2583864581 WLC1_SWDL_Resp 0;
BA_ "GenSigSwitchedByIgnition" SG_ 2589283612 WLC2_aktive_Spule 0;
BA_ "GenSigSendType" SG_ 2589283612 WLC2_aktive_Spule 3;
BA_ "GenSigSwitchedByIgnition" SG_ 2589283612 WLC2_Charger_Effizienz 0;
BA_ "GenSigSendType" SG_ 2589283612 WLC2_Charger_Effizienz 3;
BA_ "GenSigSwitchedByIgnition" SG_ 2589283612 WLC2_Charger_laedt 0;
BA_ "GenSigSendType" SG_ 2589283612 WLC2_Charger_laedt 3;
BA_ "GenSigSwitchedByIgnition" SG_ 2589283612 WLC2_Fremdobjekt_erkannt 0;
BA_ "GenSigSendType" SG_ 2589283612 WLC2_Fremdobjekt_erkannt 3;
BA_ "GenSigSwitchedByIgnition" SG_ 2589283612 WLC2_Leistungsklasse_Receiver 0;
BA_ "GenSigSendType" SG_ 2589283612 WLC2_Leistungsklasse_Receiver 0;
BA_ "GenSigSwitchedByIgnition" SG_ 2589283612 WLC2_Objekt_erkannt 0;
BA_ "GenSigSendType" SG_ 2589283612 WLC2_Objekt_erkannt 3;
BA_ "GenSigSwitchedByIgnition" SG_ 2589283612 WLC2_Receiver_erkannt 0;
BA_ "GenSigSendType" SG_ 2589283612 WLC2_Receiver_erkannt 3;
BA_ "GenSigSwitchedByIgnition" SG_ 2589283612 WLC2_Receiver_voll_geladen 0;
BA_ "GenSigSendType" SG_ 2589283612 WLC2_Receiver_voll_geladen 3;
BA_ "GenSigSwitchedByIgnition" SG_ 2589283612 WLC2_verwendeter_Ladestandard 0;
BA_ "GenSigSendType" SG_ 2589283612 WLC2_verwendeter_Ladestandard 0;
BA_ "GenSigSwitchedByIgnition" SG_ 2589283612 WLC2_Temp_Leistungsteil_Charger 0;
BA_ "GenSigSendType" SG_ 2589283612 WLC2_Temp_Leistungsteil_Charger 0;
BA_ "GenSigSwitchedByIgnition" SG_ 2589283612 WLC2_Temp_Oberfaeche_Charger 0;
BA_ "GenSigSendType" SG_ 2589283612 WLC2_Temp_Oberfaeche_Charger 0;
BA_ "GenSigSwitchedByIgnition" SG_ 2589283612 WLC2_Temp_Receiver 0;
BA_ "GenSigSendType" SG_ 2589283612 WLC2_Temp_Receiver 0;
BA_ "GenSigSwitchedByIgnition" SG_ 2583733765 WLC2_SWDL_Req 0;
BA_ "GenSigSwitchedByIgnition" SG_ 2583864837 WLC2_SWDL_Resp 0;
BA_ "GenSigSwitchedByIgnition" SG_ 1140 ZR_State_DU_1 0;
BA_ "GenSigSendType" SG_ 1140 ZR_State_DU_1 3;
BA_ "GenSigSwitchedByIgnition" SG_ 1140 ZR_State_DU_2 0;
BA_ "GenSigSendType" SG_ 1140 ZR_State_DU_2 3;
BA_ "GenSigSwitchedByIgnition" SG_ 1140 ZR_State_DU_3 0;
BA_ "GenSigSendType" SG_ 1140 ZR_State_DU_3 3;
BA_ "GenSigSwitchedByIgnition" SG_ 1140 ZR_WecktGesp 0;
BA_ "GenSigSendType" SG_ 1140 ZR_WecktGesp 3;
BA_ "GenSigSwitchedByIgnition" SG_ 1140 MMI_State 0;
BA_ "GenSigSendType" SG_ 1140 MMI_State 3;
BA_ "GenSigSwitchedByIgnition" SG_ 1140 ZR_DimOffs_DU_1 0;
BA_ "GenSigStartValue" SG_ 1140 ZR_DimOffs_DU_1 14;
BA_ "GenSigSendType" SG_ 1140 ZR_DimOffs_DU_1 3;
BA_ "GenSigSwitchedByIgnition" SG_ 1140 ZR_DimOffs_DU_2 0;
BA_ "GenSigStartValue" SG_ 1140 ZR_DimOffs_DU_2 14;
BA_ "GenSigSendType" SG_ 1140 ZR_DimOffs_DU_2 3;
BA_ "GenSigSwitchedByIgnition" SG_ 1140 ZR_DimOffs_DU_3 0;
BA_ "GenSigStartValue" SG_ 1140 ZR_DimOffs_DU_3 14;
BA_ "GenSigSendType" SG_ 1140 ZR_DimOffs_DU_3 3;
BA_ "GenSigSwitchedByIgnition" SG_ 1140 SI_ICAN 0;
BA_ "GenSigStartValue" SG_ 1140 SI_ICAN 1;
BA_ "GenSigSendType" SG_ 1140 SI_ICAN 3;
BA_ "GenSigSwitchedByIgnition" SG_ 1140 ZR_Lenkerposition 0;
BA_ "GenSigSendType" SG_ 1140 ZR_Lenkerposition 0;
BA_ "GenSigSwitchedByIgnition" SG_ 1140 WLC1_Systemzustand 0;
BA_ "GenSigSendType" SG_ 1140 WLC1_Systemzustand 3;
BA_ "GenSigSwitchedByIgnition" SG_ 1140 WLC2_Systemzustand 0;
BA_ "GenSigSendType" SG_ 1140 WLC2_Systemzustand 3;
BA_ "Fehlerwert" SG_ 1140 DI_Screendesign 7;
BA_ "GenSigSwitchedByIgnition" SG_ 1140 DI_Screendesign 0;
BA_ "GenSigStartValue" SG_ 1140 DI_Screendesign 6;
BA_ "GenSigSendType" SG_ 1140 DI_Screendesign 3;
BA_ "GenSigSwitchedByIgnition" SG_ 1140 ZR_State_DU_4 0;
BA_ "GenSigSendType" SG_ 1140 ZR_State_DU_4 3;
BA_ "GenSigSwitchedByIgnition" SG_ 1140 ZR_DimOffs_DU_4 0;
BA_ "GenSigSendType" SG_ 1140 ZR_DimOffs_DU_4 3;
BA_ "GenSigSwitchedByIgnition" SG_ 2589283603 ZV_verriegelt_extern_soll_alt 0;
BA_ "GenSigFuncType" SG_ 2589283603 ZV_verriegelt_extern_soll_alt 5;
BA_ "GenSigStartValue" SG_ 2589283603 ZV_verriegelt_extern_soll_alt 1;
BA_ "GenSigSendType" SG_ 2589283603 ZV_verriegelt_extern_soll_alt 0;
BA_ "GenSigSwitchedByIgnition" SG_ 2589283603 Kessy_12_alt 0;
BA_ "GenSigFuncType" SG_ 2589283603 Kessy_12_alt 5;
BA_ "GenSigStartValue" SG_ 2589283603 Kessy_12_alt 1;
BA_ "GenSigSendType" SG_ 2589283603 Kessy_12_alt 0;
BA_ "GenSigSwitchedByIgnition" SG_ 2589283603 ESP_v_Signal_alt 0;
BA_ "GenSigFuncType" SG_ 2589283603 ESP_v_Signal_alt 5;
BA_ "GenSigStartValue" SG_ 2589283603 ESP_v_Signal_alt 1;
BA_ "GenSigSendType" SG_ 2589283603 ESP_v_Signal_alt 0;
BA_ "GenSigSwitchedByIgnition" SG_ 2589283603 MO_Drehzahl_alt 0;
BA_ "GenSigFuncType" SG_ 2589283603 MO_Drehzahl_alt 5;
BA_ "GenSigStartValue" SG_ 2589283603 MO_Drehzahl_alt 1;
BA_ "GenSigSendType" SG_ 2589283603 MO_Drehzahl_alt 0;
BA_ "GenSigMissingSourceValue" SG_ 2589283603 ESP_v_Signal 65534;
BA_ "Fehlerwert" SG_ 2589283603 ESP_v_Signal 65535;
BA_ "GenSigSwitchedByIgnition" SG_ 2589283603 ESP_v_Signal 0;
BA_ "GenSigStartValue" SG_ 2589283603 ESP_v_Signal 65534;
BA_ "GenSigSendType" SG_ 2589283603 ESP_v_Signal 0;
BA_ "GenSigSwitchedByIgnition" SG_ 2589283603 MO_Drehzahl_01 0;
BA_ "GenSigSendType" SG_ 2589283603 MO_Drehzahl_01 0;
BA_ "GenSigSwitchedByIgnition" SG_ 2589283603 KY_LF_Aktiv 0;
BA_ "GenSigSendType" SG_ 2589283603 KY_LF_Aktiv 3;
BA_ "GenSigSwitchedByIgnition" SG_ 2589283603 ZV_verriegelt_extern_soll 0;
BA_ "GenSigSendType" SG_ 2589283603 ZV_verriegelt_extern_soll 3;
BA_REL_ "GenSigTimeoutTime" BU_SG_REL_ ABT_1_MIB_ab_Gen3 SG_ 2600468650 NM_SCC1_NM_State 2000;
BA_REL_ "GenSigTimeoutTime" BU_SG_REL_ ABT_1_MQB SG_ 2600468650 NM_SCC1_NM_State 2000;
BA_REL_ "GenSigTimeoutTime" BU_SG_REL_ BT_1_MQB SG_ 2600468650 NM_SCC1_NM_State 2000;
BA_REL_ "GenSigTimeoutTime" BU_SG_REL_ DU_1_MQB SG_ 2600468650 NM_SCC1_NM_State 2000;
BA_REL_ "GenSigTimeoutTime" BU_SG_REL_ DU_2 SG_ 2600468650 NM_SCC1_NM_State 2000;
BA_REL_ "GenSigTimeoutTime" BU_SG_REL_ DU_3 SG_ 2600468650 NM_SCC1_NM_State 2000;
BA_REL_ "GenSigTimeoutTime" BU_SG_REL_ DU_4 SG_ 2600468650 NM_SCC1_NM_State 2000;
BA_REL_ "GenSigTimeoutTime" BU_SG_REL_ ExBox SG_ 2600468650 NM_SCC1_NM_State 2000;
BA_REL_ "GenSigTimeoutTime" BU_SG_REL_ Kombi_TT3 SG_ 2600468650 NM_SCC1_NM_State 2000;
BA_REL_ "GenSigTimeoutTime" BU_SG_REL_ LSR_1 SG_ 2600468650 NM_SCC1_NM_State 2000;
BA_REL_ "GenSigTimeoutTime" BU_SG_REL_ SCC1 SG_ 2600468650 NM_SCC1_NM_State 2000;
BA_REL_ "GenSigTimeoutTime" BU_SG_REL_ SCC2 SG_ 2600468650 NM_SCC1_NM_State 2000;
BA_REL_ "GenSigTimeoutTime" BU_SG_REL_ SDC1 SG_ 2600468650 NM_SCC1_NM_State 2000;
BA_REL_ "GenSigTimeoutTime" BU_SG_REL_ SDC2 SG_ 2600468650 NM_SCC1_NM_State 2000;
BA_REL_ "GenSigTimeoutTime" BU_SG_REL_ SFA SG_ 2600468650 NM_SCC1_NM_State 2000;
BA_REL_ "GenSigTimeoutTime" BU_SG_REL_ TVTuner_ab_Gen3_JPN SG_ 2600468650 NM_SCC1_NM_State 2000;
BA_REL_ "GenSigTimeoutTime" BU_SG_REL_ WLC_01 SG_ 2600468650 NM_SCC1_NM_State 2000;
BA_REL_ "GenSigTimeoutTime" BU_SG_REL_ WLC_02 SG_ 2600468650 NM_SCC1_NM_State 2000;
BA_REL_ "GenSigTimeoutTime" BU_SG_REL_ ZR_Entry SG_ 2600468650 NM_SCC1_NM_State 2000;
BA_REL_ "GenSigTimeoutTime" BU_SG_REL_ ZR_High SG_ 2600468650 NM_SCC1_NM_State 2000;
BA_REL_ "GenSigTimeoutTime" BU_SG_REL_ ZR_High_Korea SG_ 2600468650 NM_SCC1_NM_State 2000;
BA_REL_ "GenSigTimeoutTime" BU_SG_REL_ ZR_High_TT3 SG_ 2600468650 NM_SCC1_NM_State 2000;
BA_REL_ "GenSigTimeoutTime" BU_SG_REL_ ZR_MIB_OPTION_ab_Gen3 SG_ 2600468650 NM_SCC1_NM_State 2000;
BA_REL_ "GenSigTimeoutTime" BU_SG_REL_ ZR_MIB_TOP_ab_Gen3 SG_ 2600468650 NM_SCC1_NM_State 2000;
BA_REL_ "GenSigTimeoutTime" BU_SG_REL_ ZR_Standard SG_ 2600468650 NM_SCC1_NM_State 2000;
BA_REL_ "GenSigTimeoutTime" BU_SG_REL_ ABT_1_MIB_ab_Gen3 SG_ 2600468651 NM_SCC2_NM_State 2000;
BA_REL_ "GenSigTimeoutTime" BU_SG_REL_ ABT_1_MQB SG_ 2600468651 NM_SCC2_NM_State 2000;
BA_REL_ "GenSigTimeoutTime" BU_SG_REL_ BT_1_MQB SG_ 2600468651 NM_SCC2_NM_State 2000;
BA_REL_ "GenSigTimeoutTime" BU_SG_REL_ DU_1_MQB SG_ 2600468651 NM_SCC2_NM_State 2000;
BA_REL_ "GenSigTimeoutTime" BU_SG_REL_ DU_2 SG_ 2600468651 NM_SCC2_NM_State 2000;
BA_REL_ "GenSigTimeoutTime" BU_SG_REL_ DU_3 SG_ 2600468651 NM_SCC2_NM_State 2000;
BA_REL_ "GenSigTimeoutTime" BU_SG_REL_ DU_4 SG_ 2600468651 NM_SCC2_NM_State 2000;
BA_REL_ "GenSigTimeoutTime" BU_SG_REL_ ExBox SG_ 2600468651 NM_SCC2_NM_State 2000;
BA_REL_ "GenSigTimeoutTime" BU_SG_REL_ Kombi_TT3 SG_ 2600468651 NM_SCC2_NM_State 2000;
BA_REL_ "GenSigTimeoutTime" BU_SG_REL_ LSR_1 SG_ 2600468651 NM_SCC2_NM_State 2000;
BA_REL_ "GenSigTimeoutTime" BU_SG_REL_ SCC1 SG_ 2600468651 NM_SCC2_NM_State 2000;
BA_REL_ "GenSigTimeoutTime" BU_SG_REL_ SCC2 SG_ 2600468651 NM_SCC2_NM_State 2000;
BA_REL_ "GenSigTimeoutTime" BU_SG_REL_ SDC1 SG_ 2600468651 NM_SCC2_NM_State 2000;
BA_REL_ "GenSigTimeoutTime" BU_SG_REL_ SDC2 SG_ 2600468651 NM_SCC2_NM_State 2000;
BA_REL_ "GenSigTimeoutTime" BU_SG_REL_ SFA SG_ 2600468651 NM_SCC2_NM_State 2000;
BA_REL_ "GenSigTimeoutTime" BU_SG_REL_ TVTuner_ab_Gen3_JPN SG_ 2600468651 NM_SCC2_NM_State 2000;
BA_REL_ "GenSigTimeoutTime" BU_SG_REL_ WLC_01 SG_ 2600468651 NM_SCC2_NM_State 2000;
BA_REL_ "GenSigTimeoutTime" BU_SG_REL_ WLC_02 SG_ 2600468651 NM_SCC2_NM_State 2000;
BA_REL_ "GenSigTimeoutTime" BU_SG_REL_ ZR_Entry SG_ 2600468651 NM_SCC2_NM_State 2000;
BA_REL_ "GenSigTimeoutTime" BU_SG_REL_ ZR_High SG_ 2600468651 NM_SCC2_NM_State 2000;
BA_REL_ "GenSigTimeoutTime" BU_SG_REL_ ZR_High_Korea SG_ 2600468651 NM_SCC2_NM_State 2000;
BA_REL_ "GenSigTimeoutTime" BU_SG_REL_ ZR_High_TT3 SG_ 2600468651 NM_SCC2_NM_State 2000;
BA_REL_ "GenSigTimeoutTime" BU_SG_REL_ ZR_MIB_OPTION_ab_Gen3 SG_ 2600468651 NM_SCC2_NM_State 2000;
BA_REL_ "GenSigTimeoutTime" BU_SG_REL_ ZR_MIB_TOP_ab_Gen3 SG_ 2600468651 NM_SCC2_NM_State 2000;
BA_REL_ "GenSigTimeoutTime" BU_SG_REL_ ZR_Standard SG_ 2600468651 NM_SCC2_NM_State 2000;
BA_REL_ "GenSigTimeoutTime" BU_SG_REL_ ZR_High SG_ 2600468647 NM_SDC1_CBV_AWB 2000;
BA_REL_ "GenSigTimeoutTime" BU_SG_REL_ ABT_1_MIB_ab_Gen3 SG_ 2600468647 NM_SDC1_NM_State 2000;
BA_REL_ "GenSigTimeoutTime" BU_SG_REL_ ABT_1_MQB SG_ 2600468647 NM_SDC1_NM_State 2000;
BA_REL_ "GenSigTimeoutTime" BU_SG_REL_ BT_1_MQB SG_ 2600468647 NM_SDC1_NM_State 2000;
BA_REL_ "GenSigTimeoutTime" BU_SG_REL_ DU_1_MQB SG_ 2600468647 NM_SDC1_NM_State 2000;
BA_REL_ "GenSigTimeoutTime" BU_SG_REL_ DU_2 SG_ 2600468647 NM_SDC1_NM_State 2000;
BA_REL_ "GenSigTimeoutTime" BU_SG_REL_ DU_3 SG_ 2600468647 NM_SDC1_NM_State 2000;
BA_REL_ "GenSigTimeoutTime" BU_SG_REL_ DU_4 SG_ 2600468647 NM_SDC1_NM_State 2000;
BA_REL_ "GenSigTimeoutTime" BU_SG_REL_ ExBox SG_ 2600468647 NM_SDC1_NM_State 2000;
BA_REL_ "GenSigTimeoutTime" BU_SG_REL_ Kombi_TT3 SG_ 2600468647 NM_SDC1_NM_State 2000;
BA_REL_ "GenSigTimeoutTime" BU_SG_REL_ LSR_1 SG_ 2600468647 NM_SDC1_NM_State 2000;
BA_REL_ "GenSigTimeoutTime" BU_SG_REL_ SCC1 SG_ 2600468647 NM_SDC1_NM_State 2000;
BA_REL_ "GenSigTimeoutTime" BU_SG_REL_ SCC2 SG_ 2600468647 NM_SDC1_NM_State 2000;
BA_REL_ "GenSigTimeoutTime" BU_SG_REL_ SDC1 SG_ 2600468647 NM_SDC1_NM_State 2000;
BA_REL_ "GenSigTimeoutTime" BU_SG_REL_ SDC2 SG_ 2600468647 NM_SDC1_NM_State 2000;
BA_REL_ "GenSigTimeoutTime" BU_SG_REL_ SFA SG_ 2600468647 NM_SDC1_NM_State 2000;
BA_REL_ "GenSigTimeoutTime" BU_SG_REL_ TVTuner_ab_Gen3_JPN SG_ 2600468647 NM_SDC1_NM_State 2000;
BA_REL_ "GenSigTimeoutTime" BU_SG_REL_ WLC_01 SG_ 2600468647 NM_SDC1_NM_State 2000;
BA_REL_ "GenSigTimeoutTime" BU_SG_REL_ WLC_02 SG_ 2600468647 NM_SDC1_NM_State 2000;
BA_REL_ "GenSigTimeoutTime" BU_SG_REL_ ZR_Entry SG_ 2600468647 NM_SDC1_NM_State 2000;
BA_REL_ "GenSigTimeoutTime" BU_SG_REL_ ZR_High SG_ 2600468647 NM_SDC1_NM_State 2000;
BA_REL_ "GenSigTimeoutTime" BU_SG_REL_ ZR_High_Korea SG_ 2600468647 NM_SDC1_NM_State 2000;
BA_REL_ "GenSigTimeoutTime" BU_SG_REL_ ZR_High_TT3 SG_ 2600468647 NM_SDC1_NM_State 2000;
BA_REL_ "GenSigTimeoutTime" BU_SG_REL_ ZR_MIB_OPTION_ab_Gen3 SG_ 2600468647 NM_SDC1_NM_State 2000;
BA_REL_ "GenSigTimeoutTime" BU_SG_REL_ ZR_MIB_TOP_ab_Gen3 SG_ 2600468647 NM_SDC1_NM_State 2000;
BA_REL_ "GenSigTimeoutTime" BU_SG_REL_ ZR_Standard SG_ 2600468647 NM_SDC1_NM_State 2000;
BA_REL_ "GenSigTimeoutTime" BU_SG_REL_ ZR_High SG_ 2600468648 NM_SDC2_CBV_AWB 2000;
BA_REL_ "GenSigTimeoutTime" BU_SG_REL_ ABT_1_MIB_ab_Gen3 SG_ 2600468648 NM_SDC2_NM_State 2000;
BA_REL_ "GenSigTimeoutTime" BU_SG_REL_ ABT_1_MQB SG_ 2600468648 NM_SDC2_NM_State 2000;
BA_REL_ "GenSigTimeoutTime" BU_SG_REL_ BT_1_MQB SG_ 2600468648 NM_SDC2_NM_State 2000;
BA_REL_ "GenSigTimeoutTime" BU_SG_REL_ DU_1_MQB SG_ 2600468648 NM_SDC2_NM_State 2000;
BA_REL_ "GenSigTimeoutTime" BU_SG_REL_ DU_2 SG_ 2600468648 NM_SDC2_NM_State 2000;
BA_REL_ "GenSigTimeoutTime" BU_SG_REL_ DU_3 SG_ 2600468648 NM_SDC2_NM_State 2000;
BA_REL_ "GenSigTimeoutTime" BU_SG_REL_ DU_4 SG_ 2600468648 NM_SDC2_NM_State 2000;
BA_REL_ "GenSigTimeoutTime" BU_SG_REL_ ExBox SG_ 2600468648 NM_SDC2_NM_State 2000;
BA_REL_ "GenSigTimeoutTime" BU_SG_REL_ Kombi_TT3 SG_ 2600468648 NM_SDC2_NM_State 2000;
BA_REL_ "GenSigTimeoutTime" BU_SG_REL_ LSR_1 SG_ 2600468648 NM_SDC2_NM_State 2000;
BA_REL_ "GenSigTimeoutTime" BU_SG_REL_ SCC1 SG_ 2600468648 NM_SDC2_NM_State 2000;
BA_REL_ "GenSigTimeoutTime" BU_SG_REL_ SCC2 SG_ 2600468648 NM_SDC2_NM_State 2000;
BA_REL_ "GenSigTimeoutTime" BU_SG_REL_ SDC1 SG_ 2600468648 NM_SDC2_NM_State 2000;
BA_REL_ "GenSigTimeoutTime" BU_SG_REL_ SDC2 SG_ 2600468648 NM_SDC2_NM_State 2000;
BA_REL_ "GenSigTimeoutTime" BU_SG_REL_ SFA SG_ 2600468648 NM_SDC2_NM_State 2000;
BA_REL_ "GenSigTimeoutTime" BU_SG_REL_ TVTuner_ab_Gen3_JPN SG_ 2600468648 NM_SDC2_NM_State 2000;
BA_REL_ "GenSigTimeoutTime" BU_SG_REL_ WLC_01 SG_ 2600468648 NM_SDC2_NM_State 2000;
BA_REL_ "GenSigTimeoutTime" BU_SG_REL_ WLC_02 SG_ 2600468648 NM_SDC2_NM_State 2000;
BA_REL_ "GenSigTimeoutTime" BU_SG_REL_ ZR_Entry SG_ 2600468648 NM_SDC2_NM_State 2000;
BA_REL_ "GenSigTimeoutTime" BU_SG_REL_ ZR_High SG_ 2600468648 NM_SDC2_NM_State 2000;
BA_REL_ "GenSigTimeoutTime" BU_SG_REL_ ZR_High_Korea SG_ 2600468648 NM_SDC2_NM_State 2000;
BA_REL_ "GenSigTimeoutTime" BU_SG_REL_ ZR_High_TT3 SG_ 2600468648 NM_SDC2_NM_State 2000;
BA_REL_ "GenSigTimeoutTime" BU_SG_REL_ ZR_MIB_OPTION_ab_Gen3 SG_ 2600468648 NM_SDC2_NM_State 2000;
BA_REL_ "GenSigTimeoutTime" BU_SG_REL_ ZR_MIB_TOP_ab_Gen3 SG_ 2600468648 NM_SDC2_NM_State 2000;
BA_REL_ "GenSigTimeoutTime" BU_SG_REL_ ZR_Standard SG_ 2600468648 NM_SDC2_NM_State 2000;
BA_REL_ "GenSigTimeoutTime" BU_SG_REL_ ABT_1_MIB_ab_Gen3 SG_ 2600468527 NM_SFA_NM_State 2000;
BA_REL_ "GenSigTimeoutTime" BU_SG_REL_ ABT_1_MQB SG_ 2600468527 NM_SFA_NM_State 2000;
BA_REL_ "GenSigTimeoutTime" BU_SG_REL_ BT_1_MQB SG_ 2600468527 NM_SFA_NM_State 2000;
BA_REL_ "GenSigTimeoutTime" BU_SG_REL_ DU_1_MQB SG_ 2600468527 NM_SFA_NM_State 2000;
BA_REL_ "GenSigTimeoutTime" BU_SG_REL_ DU_2 SG_ 2600468527 NM_SFA_NM_State 2000;
BA_REL_ "GenSigTimeoutTime" BU_SG_REL_ DU_3 SG_ 2600468527 NM_SFA_NM_State 2000;
BA_REL_ "GenSigTimeoutTime" BU_SG_REL_ DU_4 SG_ 2600468527 NM_SFA_NM_State 2000;
BA_REL_ "GenSigTimeoutTime" BU_SG_REL_ ExBox SG_ 2600468527 NM_SFA_NM_State 2000;
BA_REL_ "GenSigTimeoutTime" BU_SG_REL_ Kombi_TT3 SG_ 2600468527 NM_SFA_NM_State 2000;
BA_REL_ "GenSigTimeoutTime" BU_SG_REL_ LSR_1 SG_ 2600468527 NM_SFA_NM_State 2000;
BA_REL_ "GenSigTimeoutTime" BU_SG_REL_ SCC1 SG_ 2600468527 NM_SFA_NM_State 2000;
BA_REL_ "GenSigTimeoutTime" BU_SG_REL_ SCC2 SG_ 2600468527 NM_SFA_NM_State 2000;
BA_REL_ "GenSigTimeoutTime" BU_SG_REL_ SDC1 SG_ 2600468527 NM_SFA_NM_State 2000;
BA_REL_ "GenSigTimeoutTime" BU_SG_REL_ SDC2 SG_ 2600468527 NM_SFA_NM_State 2000;
BA_REL_ "GenSigTimeoutTime" BU_SG_REL_ SFA SG_ 2600468527 NM_SFA_NM_State 2000;
BA_REL_ "GenSigTimeoutTime" BU_SG_REL_ TVTuner_ab_Gen3_JPN SG_ 2600468527 NM_SFA_NM_State 2000;
BA_REL_ "GenSigTimeoutTime" BU_SG_REL_ WLC_01 SG_ 2600468527 NM_SFA_NM_State 2000;
BA_REL_ "GenSigTimeoutTime" BU_SG_REL_ WLC_02 SG_ 2600468527 NM_SFA_NM_State 2000;
BA_REL_ "GenSigTimeoutTime" BU_SG_REL_ ZR_Entry SG_ 2600468527 NM_SFA_NM_State 2000;
BA_REL_ "GenSigTimeoutTime" BU_SG_REL_ ZR_High SG_ 2600468527 NM_SFA_NM_State 2000;
BA_REL_ "GenSigTimeoutTime" BU_SG_REL_ ZR_High_Korea SG_ 2600468527 NM_SFA_NM_State 2000;
BA_REL_ "GenSigTimeoutTime" BU_SG_REL_ ZR_High_TT3 SG_ 2600468527 NM_SFA_NM_State 2000;
BA_REL_ "GenSigTimeoutTime" BU_SG_REL_ ZR_MIB_OPTION_ab_Gen3 SG_ 2600468527 NM_SFA_NM_State 2000;
BA_REL_ "GenSigTimeoutTime" BU_SG_REL_ ZR_MIB_TOP_ab_Gen3 SG_ 2600468527 NM_SFA_NM_State 2000;
BA_REL_ "GenSigTimeoutTime" BU_SG_REL_ ZR_Standard SG_ 2600468527 NM_SFA_NM_State 2000;
BA_REL_ "GenSigTimeoutTime" BU_SG_REL_ ABT_1_MIB_ab_Gen3 SG_ 2600468645 NM_WLC1_NM_State 2000;
BA_REL_ "GenSigTimeoutTime" BU_SG_REL_ ABT_1_MQB SG_ 2600468645 NM_WLC1_NM_State 2000;
BA_REL_ "GenSigTimeoutTime" BU_SG_REL_ BT_1_MQB SG_ 2600468645 NM_WLC1_NM_State 2000;
BA_REL_ "GenSigTimeoutTime" BU_SG_REL_ DU_1_MQB SG_ 2600468645 NM_WLC1_NM_State 2000;
BA_REL_ "GenSigTimeoutTime" BU_SG_REL_ DU_2 SG_ 2600468645 NM_WLC1_NM_State 2000;
BA_REL_ "GenSigTimeoutTime" BU_SG_REL_ DU_3 SG_ 2600468645 NM_WLC1_NM_State 2000;
BA_REL_ "GenSigTimeoutTime" BU_SG_REL_ DU_4 SG_ 2600468645 NM_WLC1_NM_State 2000;
BA_REL_ "GenSigTimeoutTime" BU_SG_REL_ ExBox SG_ 2600468645 NM_WLC1_NM_State 2000;
BA_REL_ "GenSigTimeoutTime" BU_SG_REL_ Kombi_TT3 SG_ 2600468645 NM_WLC1_NM_State 2000;
BA_REL_ "GenSigTimeoutTime" BU_SG_REL_ LSR_1 SG_ 2600468645 NM_WLC1_NM_State 2000;
BA_REL_ "GenSigTimeoutTime" BU_SG_REL_ SCC1 SG_ 2600468645 NM_WLC1_NM_State 2000;
BA_REL_ "GenSigTimeoutTime" BU_SG_REL_ SCC2 SG_ 2600468645 NM_WLC1_NM_State 2000;
BA_REL_ "GenSigTimeoutTime" BU_SG_REL_ SDC1 SG_ 2600468645 NM_WLC1_NM_State 2000;
BA_REL_ "GenSigTimeoutTime" BU_SG_REL_ SDC2 SG_ 2600468645 NM_WLC1_NM_State 2000;
BA_REL_ "GenSigTimeoutTime" BU_SG_REL_ SFA SG_ 2600468645 NM_WLC1_NM_State 2000;
BA_REL_ "GenSigTimeoutTime" BU_SG_REL_ TVTuner_ab_Gen3_JPN SG_ 2600468645 NM_WLC1_NM_State 2000;
BA_REL_ "GenSigTimeoutTime" BU_SG_REL_ WLC_01 SG_ 2600468645 NM_WLC1_NM_State 2000;
BA_REL_ "GenSigTimeoutTime" BU_SG_REL_ WLC_02 SG_ 2600468645 NM_WLC1_NM_State 2000;
BA_REL_ "GenSigTimeoutTime" BU_SG_REL_ ZR_Entry SG_ 2600468645 NM_WLC1_NM_State 2000;
BA_REL_ "GenSigTimeoutTime" BU_SG_REL_ ZR_High SG_ 2600468645 NM_WLC1_NM_State 2000;
BA_REL_ "GenSigTimeoutTime" BU_SG_REL_ ZR_High_Korea SG_ 2600468645 NM_WLC1_NM_State 2000;
BA_REL_ "GenSigTimeoutTime" BU_SG_REL_ ZR_High_TT3 SG_ 2600468645 NM_WLC1_NM_State 2000;
BA_REL_ "GenSigTimeoutTime" BU_SG_REL_ ZR_MIB_OPTION_ab_Gen3 SG_ 2600468645 NM_WLC1_NM_State 2000;
BA_REL_ "GenSigTimeoutTime" BU_SG_REL_ ZR_MIB_TOP_ab_Gen3 SG_ 2600468645 NM_WLC1_NM_State 2000;
BA_REL_ "GenSigTimeoutTime" BU_SG_REL_ ZR_Standard SG_ 2600468645 NM_WLC1_NM_State 2000;
BA_REL_ "GenSigTimeoutTime" BU_SG_REL_ ABT_1_MIB_ab_Gen3 SG_ 2600468646 NM_WLC2_NM_State 2000;
BA_REL_ "GenSigTimeoutTime" BU_SG_REL_ ABT_1_MQB SG_ 2600468646 NM_WLC2_NM_State 2000;
BA_REL_ "GenSigTimeoutTime" BU_SG_REL_ BT_1_MQB SG_ 2600468646 NM_WLC2_NM_State 2000;
BA_REL_ "GenSigTimeoutTime" BU_SG_REL_ DU_1_MQB SG_ 2600468646 NM_WLC2_NM_State 2000;
BA_REL_ "GenSigTimeoutTime" BU_SG_REL_ DU_2 SG_ 2600468646 NM_WLC2_NM_State 2000;
BA_REL_ "GenSigTimeoutTime" BU_SG_REL_ DU_3 SG_ 2600468646 NM_WLC2_NM_State 2000;
BA_REL_ "GenSigTimeoutTime" BU_SG_REL_ DU_4 SG_ 2600468646 NM_WLC2_NM_State 2000;
BA_REL_ "GenSigTimeoutTime" BU_SG_REL_ ExBox SG_ 2600468646 NM_WLC2_NM_State 2000;
BA_REL_ "GenSigTimeoutTime" BU_SG_REL_ Kombi_TT3 SG_ 2600468646 NM_WLC2_NM_State 2000;
BA_REL_ "GenSigTimeoutTime" BU_SG_REL_ LSR_1 SG_ 2600468646 NM_WLC2_NM_State 2000;
BA_REL_ "GenSigTimeoutTime" BU_SG_REL_ SCC1 SG_ 2600468646 NM_WLC2_NM_State 2000;
BA_REL_ "GenSigTimeoutTime" BU_SG_REL_ SCC2 SG_ 2600468646 NM_WLC2_NM_State 2000;
BA_REL_ "GenSigTimeoutTime" BU_SG_REL_ SDC1 SG_ 2600468646 NM_WLC2_NM_State 2000;
BA_REL_ "GenSigTimeoutTime" BU_SG_REL_ SDC2 SG_ 2600468646 NM_WLC2_NM_State 2000;
BA_REL_ "GenSigTimeoutTime" BU_SG_REL_ SFA SG_ 2600468646 NM_WLC2_NM_State 2000;
BA_REL_ "GenSigTimeoutTime" BU_SG_REL_ TVTuner_ab_Gen3_JPN SG_ 2600468646 NM_WLC2_NM_State 2000;
BA_REL_ "GenSigTimeoutTime" BU_SG_REL_ WLC_01 SG_ 2600468646 NM_WLC2_NM_State 2000;
BA_REL_ "GenSigTimeoutTime" BU_SG_REL_ WLC_02 SG_ 2600468646 NM_WLC2_NM_State 2000;
BA_REL_ "GenSigTimeoutTime" BU_SG_REL_ ZR_Entry SG_ 2600468646 NM_WLC2_NM_State 2000;
BA_REL_ "GenSigTimeoutTime" BU_SG_REL_ ZR_High SG_ 2600468646 NM_WLC2_NM_State 2000;
BA_REL_ "GenSigTimeoutTime" BU_SG_REL_ ZR_High_Korea SG_ 2600468646 NM_WLC2_NM_State 2000;
BA_REL_ "GenSigTimeoutTime" BU_SG_REL_ ZR_High_TT3 SG_ 2600468646 NM_WLC2_NM_State 2000;
BA_REL_ "GenSigTimeoutTime" BU_SG_REL_ ZR_MIB_OPTION_ab_Gen3 SG_ 2600468646 NM_WLC2_NM_State 2000;
BA_REL_ "GenSigTimeoutTime" BU_SG_REL_ ZR_MIB_TOP_ab_Gen3 SG_ 2600468646 NM_WLC2_NM_State 2000;
BA_REL_ "GenSigTimeoutTime" BU_SG_REL_ ZR_Standard SG_ 2600468646 NM_WLC2_NM_State 2000;
BA_REL_ "GenSigTimeoutTime" BU_SG_REL_ ABT_1_MIB_ab_Gen3 SG_ 2589283656 ORU_Status 5000;
BA_REL_ "GenSigTimeoutTime" BU_SG_REL_ BT_1_MQB SG_ 1616 RA_Frequency 5000;
BA_REL_ "GenSigTimeoutTime" BU_SG_REL_ WLC_01 SG_ 1616 RA_Frequency 5000;
BA_REL_ "GenSigTimeoutTime" BU_SG_REL_ WLC_02 SG_ 1616 RA_Frequency 5000;
BA_REL_ "GenSigTimeoutTime" BU_SG_REL_ BT_1_MQB SG_ 1616 RA_Frequency_unit 5000;
BA_REL_ "GenSigTimeoutTime" BU_SG_REL_ WLC_01 SG_ 1616 RA_Frequency_unit 5000;
BA_REL_ "GenSigTimeoutTime" BU_SG_REL_ WLC_02 SG_ 1616 RA_Frequency_unit 5000;
BA_REL_ "GenSigTimeoutTime" BU_SG_REL_ BT_1_MQB SG_ 1616 RA_AM_Tuning 5000;
BA_REL_ "GenSigTimeoutTime" BU_SG_REL_ WLC_01 SG_ 1616 RA_AM_Tuning 5000;
BA_REL_ "GenSigTimeoutTime" BU_SG_REL_ WLC_02 SG_ 1616 RA_AM_Tuning 5000;
BA_REL_ "GenSigTimeoutTime" BU_SG_REL_ ZR_Standard SG_ 1350 MMI_on_angefordert 5000;
BA_REL_ "GenSigTimeoutTime" BU_SG_REL_ ZR_High SG_ 2589283480 SDC1_Variante 5000;
BA_REL_ "GenSigTimeoutTime" BU_SG_REL_ ZR_High SG_ 2589283480 SDC1_Powerstate 5000;
BA_REL_ "GenSigTimeoutTime" BU_SG_REL_ ZR_High SG_ 2589283480 SDC1_Q_Critical 5000;
BA_REL_ "GenSigTimeoutTime" BU_SG_REL_ ZR_High SG_ 2589283480 SDC1_LastOn 5000;
BA_REL_ "GenSigTimeoutTime" BU_SG_REL_ ZR_High SG_ 2589283480 SDC1_SystemMode 5000;
BA_REL_ "GenSigTimeoutTime" BU_SG_REL_ ZR_High SG_ 2589283480 SDC1_KL_30F 5000;
BA_REL_ "GenSigTimeoutTime" BU_SG_REL_ ZR_High SG_ 2589283480 SDC1_TempSens 5000;
BA_REL_ "GenSigTimeoutTime" BU_SG_REL_ ZR_High SG_ 2589283480 SDC1_TempSensMax 5000;
BA_REL_ "GenSigTimeoutTime" BU_SG_REL_ ZR_High SG_ 2589283482 SDC2_Variante 5000;
BA_REL_ "GenSigTimeoutTime" BU_SG_REL_ ZR_High SG_ 2589283482 SDC2_Powerstate 5000;
BA_REL_ "GenSigTimeoutTime" BU_SG_REL_ ZR_High SG_ 2589283482 SDC2_Q_Critical 5000;
BA_REL_ "GenSigTimeoutTime" BU_SG_REL_ ZR_High SG_ 2589283482 SDC2_LastOn 5000;
BA_REL_ "GenSigTimeoutTime" BU_SG_REL_ ZR_High SG_ 2589283482 SDC2_SystemMode 5000;
BA_REL_ "GenSigTimeoutTime" BU_SG_REL_ ZR_High SG_ 2589283482 SDC2_KL_30F 5000;
BA_REL_ "GenSigTimeoutTime" BU_SG_REL_ ZR_High SG_ 2589283482 SDC2_TempSens 5000;
BA_REL_ "GenSigTimeoutTime" BU_SG_REL_ ZR_High SG_ 2589283482 SDC2_TempSensMax 5000;
BA_REL_ "GenSigTimeoutTime" BU_SG_REL_ ZR_High SG_ 2589283486 SCC_State 5000;
BA_REL_ "GenSigTimeoutTime" BU_SG_REL_ ZR_High SG_ 2589283486 SystemMode 5000;
BA_REL_ "GenSigTimeoutTime" BU_SG_REL_ ZR_High SG_ 2589283486 SCC_Temp_Fehler 5000;
BA_REL_ "GenSigTimeoutTime" BU_SG_REL_ ZR_High SG_ 2589283486 SCC_KL30_Uebersp_Fehler 5000;
BA_REL_ "GenSigTimeoutTime" BU_SG_REL_ ZR_High SG_ 2589283486 SCC_KL30_Untersp_Fehler 5000;
BA_REL_ "GenSigTimeoutTime" BU_SG_REL_ ZR_High SG_ 2589283486 SCC_KL_30F 5000;
BA_REL_ "GenSigTimeoutTime" BU_SG_REL_ ZR_High SG_ 2589283486 SCC_TempSens 5000;
BA_REL_ "GenSigTimeoutTime" BU_SG_REL_ ZR_High SG_ 2589283486 SCC_TempSensMax 5000;
BA_REL_ "GenSigTimeoutTime" BU_SG_REL_ ZR_High SG_ 2589283486 SCC_Variant 5000;
BA_REL_ "GenSigTimeoutTime" BU_SG_REL_ ZR_High SG_ 2589283486 SCC1_Powerstate 5000;
BA_REL_ "GenSigTimeoutTime" BU_SG_REL_ ZR_High SG_ 2589283487 EEPROM_Fehler 5000;
BA_REL_ "GenSigTimeoutTime" BU_SG_REL_ ZR_High SG_ 2589283488 SCC_State 5000;
BA_REL_ "GenSigTimeoutTime" BU_SG_REL_ ZR_High SG_ 2589283488 SystemMode 5000;
BA_REL_ "GenSigTimeoutTime" BU_SG_REL_ ZR_High SG_ 2589283488 SCC_Temp_Fehler 5000;
BA_REL_ "GenSigTimeoutTime" BU_SG_REL_ ZR_High SG_ 2589283488 SCC_KL30_Uebersp_Fehler 5000;
BA_REL_ "GenSigTimeoutTime" BU_SG_REL_ ZR_High SG_ 2589283488 SCC_KL30_Untersp_Fehler 5000;
BA_REL_ "GenSigTimeoutTime" BU_SG_REL_ ZR_High SG_ 2589283488 SCC_KL_30F 5000;
BA_REL_ "GenSigTimeoutTime" BU_SG_REL_ ZR_High SG_ 2589283488 SCC_TempSens 5000;
BA_REL_ "GenSigTimeoutTime" BU_SG_REL_ ZR_High SG_ 2589283488 SCC_TempSensMax 5000;
BA_REL_ "GenSigTimeoutTime" BU_SG_REL_ ZR_High SG_ 2589283488 SCC_Variant 5000;
BA_REL_ "GenSigTimeoutTime" BU_SG_REL_ ZR_High SG_ 2589283488 SCC2_Powerstate 5000;
BA_REL_ "GenSigTimeoutTime" BU_SG_REL_ ZR_High SG_ 2589283489 EEPROM_Fehler 5000;
BA_REL_ "GenSigTimeoutTime" BU_SG_REL_ SCC1 SG_ 1413 SI_QRS_Mode 5000;
BA_REL_ "GenSigTimeoutTime" BU_SG_REL_ SCC2 SG_ 1413 SI_QRS_Mode 5000;
BA_REL_ "GenSigTimeoutTime" BU_SG_REL_ SDC1 SG_ 1413 SI_QRS_Mode 5000;
BA_REL_ "GenSigTimeoutTime" BU_SG_REL_ SDC2 SG_ 1413 SI_QRS_Mode 5000;
BA_REL_ "GenSigTimeoutTime" BU_SG_REL_ WLC_01 SG_ 1413 SI_QRS_Mode 5000;
BA_REL_ "GenSigTimeoutTime" BU_SG_REL_ WLC_02 SG_ 1413 SI_QRS_Mode 5000;
BA_REL_ "GenSigTimeoutTime" BU_SG_REL_ DU_4 SG_ 1413 SI_QRS_Mode 5000;
BA_REL_ "GenSigTimeoutTime" BU_SG_REL_ ABT_1_MIB_ab_Gen3 SG_ 1413 SI_T_Mode 5000;
BA_REL_ "GenSigTimeoutTime" BU_SG_REL_ ABT_1_MQB SG_ 1413 SI_T_Mode 5000;
BA_REL_ "GenSigTimeoutTime" BU_SG_REL_ BT_1_MQB SG_ 1413 SI_T_Mode 5000;
BA_REL_ "GenSigTimeoutTime" BU_SG_REL_ DU_3 SG_ 1413 SI_T_Mode 5000;
BA_REL_ "GenSigTimeoutTime" BU_SG_REL_ DU_4 SG_ 1413 SI_T_Mode 5000;
BA_REL_ "GenSigTimeoutTime" BU_SG_REL_ ExBox SG_ 1413 SI_T_Mode 5000;
BA_REL_ "GenSigTimeoutTime" BU_SG_REL_ LSR_1 SG_ 1413 SI_T_Mode 5000;
BA_REL_ "GenSigTimeoutTime" BU_SG_REL_ SCC1 SG_ 1413 SI_T_Mode 5000;
BA_REL_ "GenSigTimeoutTime" BU_SG_REL_ SCC2 SG_ 1413 SI_T_Mode 5000;
BA_REL_ "GenSigTimeoutTime" BU_SG_REL_ SDC1 SG_ 1413 SI_T_Mode 5000;
BA_REL_ "GenSigTimeoutTime" BU_SG_REL_ SDC2 SG_ 1413 SI_T_Mode 5000;
BA_REL_ "GenSigTimeoutTime" BU_SG_REL_ WLC_01 SG_ 1413 SI_T_Mode 5000;
BA_REL_ "GenSigTimeoutTime" BU_SG_REL_ WLC_02 SG_ 1413 SI_T_Mode 5000;
BA_REL_ "GenSigTimeoutTime" BU_SG_REL_ SCC1 SG_ 1413 SI_NWDF 5000;
BA_REL_ "GenSigTimeoutTime" BU_SG_REL_ SCC2 SG_ 1413 SI_NWDF 5000;
BA_REL_ "GenSigTimeoutTime" BU_SG_REL_ SDC1 SG_ 1413 SI_NWDF 5000;
BA_REL_ "GenSigTimeoutTime" BU_SG_REL_ SDC2 SG_ 1413 SI_NWDF 5000;
BA_REL_ "GenSigTimeoutTime" BU_SG_REL_ WLC_01 SG_ 1413 SI_NWDF 5000;
BA_REL_ "GenSigTimeoutTime" BU_SG_REL_ WLC_02 SG_ 1413 SI_NWDF 5000;
BA_REL_ "GenSigTimeoutTime" BU_SG_REL_ SCC1 SG_ 1413 SI_NWDF_gueltig 5000;
BA_REL_ "GenSigTimeoutTime" BU_SG_REL_ SCC2 SG_ 1413 SI_NWDF_gueltig 5000;
BA_REL_ "GenSigTimeoutTime" BU_SG_REL_ SDC1 SG_ 1413 SI_NWDF_gueltig 5000;
BA_REL_ "GenSigTimeoutTime" BU_SG_REL_ SDC2 SG_ 1413 SI_NWDF_gueltig 5000;
BA_REL_ "GenSigTimeoutTime" BU_SG_REL_ WLC_01 SG_ 1413 SI_NWDF_gueltig 5000;
BA_REL_ "GenSigTimeoutTime" BU_SG_REL_ WLC_02 SG_ 1413 SI_NWDF_gueltig 5000;
BA_REL_ "GenSigTimeoutTime" BU_SG_REL_ SCC1 SG_ 1413 SI_T_Schutz 5000;
BA_REL_ "GenSigTimeoutTime" BU_SG_REL_ SCC2 SG_ 1413 SI_T_Schutz 5000;
BA_REL_ "GenSigTimeoutTime" BU_SG_REL_ SDC1 SG_ 1413 SI_T_Schutz 5000;
BA_REL_ "GenSigTimeoutTime" BU_SG_REL_ SDC2 SG_ 1413 SI_T_Schutz 5000;
BA_REL_ "GenSigTimeoutTime" BU_SG_REL_ ABT_1_MIB_ab_Gen3 SG_ 1413 SI_BUS_03 5000;
BA_REL_ "GenSigTimeoutTime" BU_SG_REL_ ABT_1_MQB SG_ 1413 SI_BUS_03 5000;
BA_REL_ "GenSigTimeoutTime" BU_SG_REL_ BT_1_MQB SG_ 1413 SI_BUS_03 5000;
BA_REL_ "GenSigTimeoutTime" BU_SG_REL_ DU_1_MQB SG_ 1413 SI_BUS_03 5000;
BA_REL_ "GenSigTimeoutTime" BU_SG_REL_ DU_2 SG_ 1413 SI_BUS_03 5000;
BA_REL_ "GenSigTimeoutTime" BU_SG_REL_ DU_3 SG_ 1413 SI_BUS_03 5000;
BA_REL_ "GenSigTimeoutTime" BU_SG_REL_ DU_4 SG_ 1413 SI_BUS_03 5000;
BA_REL_ "GenSigTimeoutTime" BU_SG_REL_ ExBox SG_ 1413 SI_BUS_03 5000;
BA_REL_ "GenSigTimeoutTime" BU_SG_REL_ LSR_1 SG_ 1413 SI_BUS_03 5000;
BA_REL_ "GenSigTimeoutTime" BU_SG_REL_ SDC1 SG_ 1413 SI_BUS_03 5000;
BA_REL_ "GenSigTimeoutTime" BU_SG_REL_ SDC2 SG_ 1413 SI_BUS_03 5000;
BA_REL_ "GenSigTimeoutTime" BU_SG_REL_ SCC1 SG_ 1716 VIN_01_MUX 2000;
BA_REL_ "GenSigTimeoutTime" BU_SG_REL_ SCC2 SG_ 1716 VIN_01_MUX 2000;
BA_REL_ "GenSigTimeoutTime" BU_SG_REL_ SDC1 SG_ 1716 VIN_01_MUX 2000;
BA_REL_ "GenSigTimeoutTime" BU_SG_REL_ SDC2 SG_ 1716 VIN_01_MUX 2000;
BA_REL_ "GenSigTimeoutTime" BU_SG_REL_ SCC1 SG_ 1716 VIN_4 2000;
BA_REL_ "GenSigTimeoutTime" BU_SG_REL_ SCC2 SG_ 1716 VIN_4 2000;
BA_REL_ "GenSigTimeoutTime" BU_SG_REL_ SDC1 SG_ 1716 VIN_4 2000;
BA_REL_ "GenSigTimeoutTime" BU_SG_REL_ SDC2 SG_ 1716 VIN_4 2000;
BA_REL_ "GenSigTimeoutTime" BU_SG_REL_ SCC1 SG_ 1716 VIN_11 2000;
BA_REL_ "GenSigTimeoutTime" BU_SG_REL_ SCC2 SG_ 1716 VIN_11 2000;
BA_REL_ "GenSigTimeoutTime" BU_SG_REL_ SDC1 SG_ 1716 VIN_11 2000;
BA_REL_ "GenSigTimeoutTime" BU_SG_REL_ SDC2 SG_ 1716 VIN_11 2000;
BA_REL_ "GenSigTimeoutTime" BU_SG_REL_ SCC1 SG_ 1716 VIN_5 2000;
BA_REL_ "GenSigTimeoutTime" BU_SG_REL_ SCC2 SG_ 1716 VIN_5 2000;
BA_REL_ "GenSigTimeoutTime" BU_SG_REL_ SDC1 SG_ 1716 VIN_5 2000;
BA_REL_ "GenSigTimeoutTime" BU_SG_REL_ SDC2 SG_ 1716 VIN_5 2000;
BA_REL_ "GenSigTimeoutTime" BU_SG_REL_ SCC1 SG_ 1716 VIN_12 2000;
BA_REL_ "GenSigTimeoutTime" BU_SG_REL_ SCC2 SG_ 1716 VIN_12 2000;
BA_REL_ "GenSigTimeoutTime" BU_SG_REL_ SDC1 SG_ 1716 VIN_12 2000;
BA_REL_ "GenSigTimeoutTime" BU_SG_REL_ SDC2 SG_ 1716 VIN_12 2000;
BA_REL_ "GenSigTimeoutTime" BU_SG_REL_ SCC1 SG_ 1716 VIN_6 2000;
BA_REL_ "GenSigTimeoutTime" BU_SG_REL_ SCC2 SG_ 1716 VIN_6 2000;
BA_REL_ "GenSigTimeoutTime" BU_SG_REL_ SDC1 SG_ 1716 VIN_6 2000;
BA_REL_ "GenSigTimeoutTime" BU_SG_REL_ SDC2 SG_ 1716 VIN_6 2000;
BA_REL_ "GenSigTimeoutTime" BU_SG_REL_ SCC1 SG_ 1716 VIN_13 2000;
BA_REL_ "GenSigTimeoutTime" BU_SG_REL_ SCC2 SG_ 1716 VIN_13 2000;
BA_REL_ "GenSigTimeoutTime" BU_SG_REL_ SDC1 SG_ 1716 VIN_13 2000;
BA_REL_ "GenSigTimeoutTime" BU_SG_REL_ SDC2 SG_ 1716 VIN_13 2000;
BA_REL_ "GenSigTimeoutTime" BU_SG_REL_ SCC1 SG_ 1716 VIN_7 2000;
BA_REL_ "GenSigTimeoutTime" BU_SG_REL_ SCC2 SG_ 1716 VIN_7 2000;
BA_REL_ "GenSigTimeoutTime" BU_SG_REL_ SDC1 SG_ 1716 VIN_7 2000;
BA_REL_ "GenSigTimeoutTime" BU_SG_REL_ SDC2 SG_ 1716 VIN_7 2000;
BA_REL_ "GenSigTimeoutTime" BU_SG_REL_ SCC1 SG_ 1716 VIN_14 2000;
BA_REL_ "GenSigTimeoutTime" BU_SG_REL_ SCC2 SG_ 1716 VIN_14 2000;
BA_REL_ "GenSigTimeoutTime" BU_SG_REL_ SDC1 SG_ 1716 VIN_14 2000;
BA_REL_ "GenSigTimeoutTime" BU_SG_REL_ SDC2 SG_ 1716 VIN_14 2000;
BA_REL_ "GenSigTimeoutTime" BU_SG_REL_ SCC1 SG_ 1716 VIN_1 2000;
BA_REL_ "GenSigTimeoutTime" BU_SG_REL_ SCC2 SG_ 1716 VIN_1 2000;
BA_REL_ "GenSigTimeoutTime" BU_SG_REL_ SDC1 SG_ 1716 VIN_1 2000;
BA_REL_ "GenSigTimeoutTime" BU_SG_REL_ SDC2 SG_ 1716 VIN_1 2000;
BA_REL_ "GenSigTimeoutTime" BU_SG_REL_ SCC1 SG_ 1716 VIN_8 2000;
BA_REL_ "GenSigTimeoutTime" BU_SG_REL_ SCC2 SG_ 1716 VIN_8 2000;
BA_REL_ "GenSigTimeoutTime" BU_SG_REL_ SDC1 SG_ 1716 VIN_8 2000;
BA_REL_ "GenSigTimeoutTime" BU_SG_REL_ SDC2 SG_ 1716 VIN_8 2000;
BA_REL_ "GenSigTimeoutTime" BU_SG_REL_ SCC1 SG_ 1716 VIN_15 2000;
BA_REL_ "GenSigTimeoutTime" BU_SG_REL_ SCC2 SG_ 1716 VIN_15 2000;
BA_REL_ "GenSigTimeoutTime" BU_SG_REL_ SDC1 SG_ 1716 VIN_15 2000;
BA_REL_ "GenSigTimeoutTime" BU_SG_REL_ SDC2 SG_ 1716 VIN_15 2000;
BA_REL_ "GenSigTimeoutTime" BU_SG_REL_ SCC1 SG_ 1716 VIN_2 2000;
BA_REL_ "GenSigTimeoutTime" BU_SG_REL_ SCC2 SG_ 1716 VIN_2 2000;
BA_REL_ "GenSigTimeoutTime" BU_SG_REL_ SDC1 SG_ 1716 VIN_2 2000;
BA_REL_ "GenSigTimeoutTime" BU_SG_REL_ SDC2 SG_ 1716 VIN_2 2000;
BA_REL_ "GenSigTimeoutTime" BU_SG_REL_ SCC1 SG_ 1716 VIN_9 2000;
BA_REL_ "GenSigTimeoutTime" BU_SG_REL_ SCC2 SG_ 1716 VIN_9 2000;
BA_REL_ "GenSigTimeoutTime" BU_SG_REL_ SDC1 SG_ 1716 VIN_9 2000;
BA_REL_ "GenSigTimeoutTime" BU_SG_REL_ SDC2 SG_ 1716 VIN_9 2000;
BA_REL_ "GenSigTimeoutTime" BU_SG_REL_ SCC1 SG_ 1716 VIN_16 2000;
BA_REL_ "GenSigTimeoutTime" BU_SG_REL_ SCC2 SG_ 1716 VIN_16 2000;
BA_REL_ "GenSigTimeoutTime" BU_SG_REL_ SDC1 SG_ 1716 VIN_16 2000;
BA_REL_ "GenSigTimeoutTime" BU_SG_REL_ SDC2 SG_ 1716 VIN_16 2000;
BA_REL_ "GenSigTimeoutTime" BU_SG_REL_ SCC1 SG_ 1716 VIN_3 2000;
BA_REL_ "GenSigTimeoutTime" BU_SG_REL_ SCC2 SG_ 1716 VIN_3 2000;
BA_REL_ "GenSigTimeoutTime" BU_SG_REL_ SDC1 SG_ 1716 VIN_3 2000;
BA_REL_ "GenSigTimeoutTime" BU_SG_REL_ SDC2 SG_ 1716 VIN_3 2000;
BA_REL_ "GenSigTimeoutTime" BU_SG_REL_ SCC1 SG_ 1716 VIN_10 2000;
BA_REL_ "GenSigTimeoutTime" BU_SG_REL_ SCC2 SG_ 1716 VIN_10 2000;
BA_REL_ "GenSigTimeoutTime" BU_SG_REL_ SDC1 SG_ 1716 VIN_10 2000;
BA_REL_ "GenSigTimeoutTime" BU_SG_REL_ SDC2 SG_ 1716 VIN_10 2000;
BA_REL_ "GenSigTimeoutTime" BU_SG_REL_ SCC1 SG_ 1716 VIN_17 2000;
BA_REL_ "GenSigTimeoutTime" BU_SG_REL_ SCC2 SG_ 1716 VIN_17 2000;
BA_REL_ "GenSigTimeoutTime" BU_SG_REL_ SDC1 SG_ 1716 VIN_17 2000;
BA_REL_ "GenSigTimeoutTime" BU_SG_REL_ SDC2 SG_ 1716 VIN_17 2000;
BA_REL_ "GenSigTimeoutTime" BU_SG_REL_ BT_1_MQB SG_ 916 WBA_Fahrstufe_02 1600;
BA_REL_ "GenSigTimeoutTime" BU_SG_REL_ ZR_High SG_ 2589283611 WLC1_aktive_Spule 5000;
BA_REL_ "GenSigTimeoutTime" BU_SG_REL_ ZR_High_Korea SG_ 2589283611 WLC1_aktive_Spule 5000;
BA_REL_ "GenSigTimeoutTime" BU_SG_REL_ ZR_MIB_OPTION_ab_Gen3 SG_ 2589283611 WLC1_aktive_Spule 5000;
BA_REL_ "GenSigTimeoutTime" BU_SG_REL_ ZR_MIB_TOP_ab_Gen3 SG_ 2589283611 WLC1_aktive_Spule 5000;
BA_REL_ "GenSigTimeoutTime" BU_SG_REL_ ZR_Standard SG_ 2589283611 WLC1_aktive_Spule 5000;
BA_REL_ "GenSigTimeoutTime" BU_SG_REL_ ZR_High SG_ 2589283611 WLC1_Charger_Effizienz 5000;
BA_REL_ "GenSigTimeoutTime" BU_SG_REL_ ZR_High_Korea SG_ 2589283611 WLC1_Charger_Effizienz 5000;
BA_REL_ "GenSigTimeoutTime" BU_SG_REL_ ZR_MIB_OPTION_ab_Gen3 SG_ 2589283611 WLC1_Charger_Effizienz 5000;
BA_REL_ "GenSigTimeoutTime" BU_SG_REL_ ZR_MIB_TOP_ab_Gen3 SG_ 2589283611 WLC1_Charger_Effizienz 5000;
BA_REL_ "GenSigTimeoutTime" BU_SG_REL_ ZR_Standard SG_ 2589283611 WLC1_Charger_Effizienz 5000;
BA_REL_ "GenSigTimeoutTime" BU_SG_REL_ ZR_High SG_ 2589283611 WLC1_Charger_laedt 5000;
BA_REL_ "GenSigTimeoutTime" BU_SG_REL_ ZR_High_Korea SG_ 2589283611 WLC1_Charger_laedt 5000;
BA_REL_ "GenSigTimeoutTime" BU_SG_REL_ ZR_MIB_OPTION_ab_Gen3 SG_ 2589283611 WLC1_Charger_laedt 5000;
BA_REL_ "GenSigTimeoutTime" BU_SG_REL_ ZR_MIB_TOP_ab_Gen3 SG_ 2589283611 WLC1_Charger_laedt 5000;
BA_REL_ "GenSigTimeoutTime" BU_SG_REL_ ZR_Standard SG_ 2589283611 WLC1_Charger_laedt 5000;
BA_REL_ "GenSigTimeoutTime" BU_SG_REL_ ZR_High SG_ 2589283611 WLC1_Fremdobjekt_erkannt 5000;
BA_REL_ "GenSigTimeoutTime" BU_SG_REL_ ZR_High_Korea SG_ 2589283611 WLC1_Fremdobjekt_erkannt 5000;
BA_REL_ "GenSigTimeoutTime" BU_SG_REL_ ZR_MIB_OPTION_ab_Gen3 SG_ 2589283611 WLC1_Fremdobjekt_erkannt 5000;
BA_REL_ "GenSigTimeoutTime" BU_SG_REL_ ZR_MIB_TOP_ab_Gen3 SG_ 2589283611 WLC1_Fremdobjekt_erkannt 5000;
BA_REL_ "GenSigTimeoutTime" BU_SG_REL_ ZR_Standard SG_ 2589283611 WLC1_Fremdobjekt_erkannt 5000;
BA_REL_ "GenSigTimeoutTime" BU_SG_REL_ ZR_High SG_ 2589283611 WLC1_Leistungsklasse_Receiver 5000;
BA_REL_ "GenSigTimeoutTime" BU_SG_REL_ ZR_High_Korea SG_ 2589283611 WLC1_Leistungsklasse_Receiver 5000;
BA_REL_ "GenSigTimeoutTime" BU_SG_REL_ ZR_MIB_OPTION_ab_Gen3 SG_ 2589283611 WLC1_Leistungsklasse_Receiver 5000;
BA_REL_ "GenSigTimeoutTime" BU_SG_REL_ ZR_MIB_TOP_ab_Gen3 SG_ 2589283611 WLC1_Leistungsklasse_Receiver 5000;
BA_REL_ "GenSigTimeoutTime" BU_SG_REL_ ZR_Standard SG_ 2589283611 WLC1_Leistungsklasse_Receiver 5000;
BA_REL_ "GenSigTimeoutTime" BU_SG_REL_ ZR_High SG_ 2589283611 WLC1_Objekt_erkannt 5000;
BA_REL_ "GenSigTimeoutTime" BU_SG_REL_ ZR_High_Korea SG_ 2589283611 WLC1_Objekt_erkannt 5000;
BA_REL_ "GenSigTimeoutTime" BU_SG_REL_ ZR_MIB_OPTION_ab_Gen3 SG_ 2589283611 WLC1_Objekt_erkannt 5000;
BA_REL_ "GenSigTimeoutTime" BU_SG_REL_ ZR_MIB_TOP_ab_Gen3 SG_ 2589283611 WLC1_Objekt_erkannt 5000;
BA_REL_ "GenSigTimeoutTime" BU_SG_REL_ ZR_Standard SG_ 2589283611 WLC1_Objekt_erkannt 5000;
BA_REL_ "GenSigTimeoutTime" BU_SG_REL_ ZR_High SG_ 2589283611 WLC1_Receiver_erkannt 5000;
BA_REL_ "GenSigTimeoutTime" BU_SG_REL_ ZR_High_Korea SG_ 2589283611 WLC1_Receiver_erkannt 5000;
BA_REL_ "GenSigTimeoutTime" BU_SG_REL_ ZR_MIB_OPTION_ab_Gen3 SG_ 2589283611 WLC1_Receiver_erkannt 5000;
BA_REL_ "GenSigTimeoutTime" BU_SG_REL_ ZR_MIB_TOP_ab_Gen3 SG_ 2589283611 WLC1_Receiver_erkannt 5000;
BA_REL_ "GenSigTimeoutTime" BU_SG_REL_ ZR_Standard SG_ 2589283611 WLC1_Receiver_erkannt 5000;
BA_REL_ "GenSigTimeoutTime" BU_SG_REL_ ZR_High SG_ 2589283611 WLC1_Receiver_voll_geladen 5000;
BA_REL_ "GenSigTimeoutTime" BU_SG_REL_ ZR_High_Korea SG_ 2589283611 WLC1_Receiver_voll_geladen 5000;
BA_REL_ "GenSigTimeoutTime" BU_SG_REL_ ZR_MIB_OPTION_ab_Gen3 SG_ 2589283611 WLC1_Receiver_voll_geladen 5000;
BA_REL_ "GenSigTimeoutTime" BU_SG_REL_ ZR_MIB_TOP_ab_Gen3 SG_ 2589283611 WLC1_Receiver_voll_geladen 5000;
BA_REL_ "GenSigTimeoutTime" BU_SG_REL_ ZR_Standard SG_ 2589283611 WLC1_Receiver_voll_geladen 5000;
BA_REL_ "GenSigTimeoutTime" BU_SG_REL_ ZR_High SG_ 2589283611 WLC1_verwendeter_Ladestandard 5000;
BA_REL_ "GenSigTimeoutTime" BU_SG_REL_ ZR_High_Korea SG_ 2589283611 WLC1_verwendeter_Ladestandard 5000;
BA_REL_ "GenSigTimeoutTime" BU_SG_REL_ ZR_MIB_OPTION_ab_Gen3 SG_ 2589283611 WLC1_verwendeter_Ladestandard 5000;
BA_REL_ "GenSigTimeoutTime" BU_SG_REL_ ZR_MIB_TOP_ab_Gen3 SG_ 2589283611 WLC1_verwendeter_Ladestandard 5000;
BA_REL_ "GenSigTimeoutTime" BU_SG_REL_ ZR_Standard SG_ 2589283611 WLC1_verwendeter_Ladestandard 5000;
BA_REL_ "GenSigTimeoutTime" BU_SG_REL_ ZR_High SG_ 2589283611 WLC1_Temp_Leistungsteil_Charger 5000;
BA_REL_ "GenSigTimeoutTime" BU_SG_REL_ ZR_High_Korea SG_ 2589283611 WLC1_Temp_Leistungsteil_Charger 5000;
BA_REL_ "GenSigTimeoutTime" BU_SG_REL_ ZR_MIB_OPTION_ab_Gen3 SG_ 2589283611 WLC1_Temp_Leistungsteil_Charger 5000;
BA_REL_ "GenSigTimeoutTime" BU_SG_REL_ ZR_MIB_TOP_ab_Gen3 SG_ 2589283611 WLC1_Temp_Leistungsteil_Charger 5000;
BA_REL_ "GenSigTimeoutTime" BU_SG_REL_ ZR_Standard SG_ 2589283611 WLC1_Temp_Leistungsteil_Charger 5000;
BA_REL_ "GenSigTimeoutTime" BU_SG_REL_ ZR_High SG_ 2589283611 WLC1_Temp_Oberfaeche_Charger 5000;
BA_REL_ "GenSigTimeoutTime" BU_SG_REL_ ZR_High_Korea SG_ 2589283611 WLC1_Temp_Oberfaeche_Charger 5000;
BA_REL_ "GenSigTimeoutTime" BU_SG_REL_ ZR_MIB_OPTION_ab_Gen3 SG_ 2589283611 WLC1_Temp_Oberfaeche_Charger 5000;
BA_REL_ "GenSigTimeoutTime" BU_SG_REL_ ZR_MIB_TOP_ab_Gen3 SG_ 2589283611 WLC1_Temp_Oberfaeche_Charger 5000;
BA_REL_ "GenSigTimeoutTime" BU_SG_REL_ ZR_Standard SG_ 2589283611 WLC1_Temp_Oberfaeche_Charger 5000;
BA_REL_ "GenSigTimeoutTime" BU_SG_REL_ ZR_High SG_ 2589283611 WLC1_Temp_Receiver 5000;
BA_REL_ "GenSigTimeoutTime" BU_SG_REL_ ZR_High_Korea SG_ 2589283611 WLC1_Temp_Receiver 5000;
BA_REL_ "GenSigTimeoutTime" BU_SG_REL_ ZR_MIB_OPTION_ab_Gen3 SG_ 2589283611 WLC1_Temp_Receiver 5000;
BA_REL_ "GenSigTimeoutTime" BU_SG_REL_ ZR_MIB_TOP_ab_Gen3 SG_ 2589283611 WLC1_Temp_Receiver 5000;
BA_REL_ "GenSigTimeoutTime" BU_SG_REL_ ZR_Standard SG_ 2589283611 WLC1_Temp_Receiver 5000;
BA_REL_ "GenSigTimeoutTime" BU_SG_REL_ ZR_High SG_ 2589283612 WLC2_aktive_Spule 5000;
BA_REL_ "GenSigTimeoutTime" BU_SG_REL_ ZR_High_Korea SG_ 2589283612 WLC2_aktive_Spule 5000;
BA_REL_ "GenSigTimeoutTime" BU_SG_REL_ ZR_MIB_OPTION_ab_Gen3 SG_ 2589283612 WLC2_aktive_Spule 5000;
BA_REL_ "GenSigTimeoutTime" BU_SG_REL_ ZR_MIB_TOP_ab_Gen3 SG_ 2589283612 WLC2_aktive_Spule 5000;
BA_REL_ "GenSigTimeoutTime" BU_SG_REL_ ZR_Standard SG_ 2589283612 WLC2_aktive_Spule 5000;
BA_REL_ "GenSigTimeoutTime" BU_SG_REL_ ZR_High SG_ 2589283612 WLC2_Charger_Effizienz 5000;
BA_REL_ "GenSigTimeoutTime" BU_SG_REL_ ZR_High_Korea SG_ 2589283612 WLC2_Charger_Effizienz 5000;
BA_REL_ "GenSigTimeoutTime" BU_SG_REL_ ZR_MIB_OPTION_ab_Gen3 SG_ 2589283612 WLC2_Charger_Effizienz 5000;
BA_REL_ "GenSigTimeoutTime" BU_SG_REL_ ZR_MIB_TOP_ab_Gen3 SG_ 2589283612 WLC2_Charger_Effizienz 5000;
BA_REL_ "GenSigTimeoutTime" BU_SG_REL_ ZR_Standard SG_ 2589283612 WLC2_Charger_Effizienz 5000;
BA_REL_ "GenSigTimeoutTime" BU_SG_REL_ ZR_High SG_ 2589283612 WLC2_Charger_laedt 5000;
BA_REL_ "GenSigTimeoutTime" BU_SG_REL_ ZR_High_Korea SG_ 2589283612 WLC2_Charger_laedt 5000;
BA_REL_ "GenSigTimeoutTime" BU_SG_REL_ ZR_MIB_OPTION_ab_Gen3 SG_ 2589283612 WLC2_Charger_laedt 5000;
BA_REL_ "GenSigTimeoutTime" BU_SG_REL_ ZR_MIB_TOP_ab_Gen3 SG_ 2589283612 WLC2_Charger_laedt 5000;
BA_REL_ "GenSigTimeoutTime" BU_SG_REL_ ZR_Standard SG_ 2589283612 WLC2_Charger_laedt 5000;
BA_REL_ "GenSigTimeoutTime" BU_SG_REL_ ZR_High SG_ 2589283612 WLC2_Fremdobjekt_erkannt 5000;
BA_REL_ "GenSigTimeoutTime" BU_SG_REL_ ZR_High_Korea SG_ 2589283612 WLC2_Fremdobjekt_erkannt 5000;
BA_REL_ "GenSigTimeoutTime" BU_SG_REL_ ZR_MIB_OPTION_ab_Gen3 SG_ 2589283612 WLC2_Fremdobjekt_erkannt 5000;
BA_REL_ "GenSigTimeoutTime" BU_SG_REL_ ZR_MIB_TOP_ab_Gen3 SG_ 2589283612 WLC2_Fremdobjekt_erkannt 5000;
BA_REL_ "GenSigTimeoutTime" BU_SG_REL_ ZR_Standard SG_ 2589283612 WLC2_Fremdobjekt_erkannt 5000;
BA_REL_ "GenSigTimeoutTime" BU_SG_REL_ ZR_High SG_ 2589283612 WLC2_Leistungsklasse_Receiver 5000;
BA_REL_ "GenSigTimeoutTime" BU_SG_REL_ ZR_High_Korea SG_ 2589283612 WLC2_Leistungsklasse_Receiver 5000;
BA_REL_ "GenSigTimeoutTime" BU_SG_REL_ ZR_MIB_OPTION_ab_Gen3 SG_ 2589283612 WLC2_Leistungsklasse_Receiver 5000;
BA_REL_ "GenSigTimeoutTime" BU_SG_REL_ ZR_MIB_TOP_ab_Gen3 SG_ 2589283612 WLC2_Leistungsklasse_Receiver 5000;
BA_REL_ "GenSigTimeoutTime" BU_SG_REL_ ZR_Standard SG_ 2589283612 WLC2_Leistungsklasse_Receiver 5000;
BA_REL_ "GenSigTimeoutTime" BU_SG_REL_ ZR_High SG_ 2589283612 WLC2_Objekt_erkannt 5000;
BA_REL_ "GenSigTimeoutTime" BU_SG_REL_ ZR_High_Korea SG_ 2589283612 WLC2_Objekt_erkannt 5000;
BA_REL_ "GenSigTimeoutTime" BU_SG_REL_ ZR_MIB_OPTION_ab_Gen3 SG_ 2589283612 WLC2_Objekt_erkannt 5000;
BA_REL_ "GenSigTimeoutTime" BU_SG_REL_ ZR_MIB_TOP_ab_Gen3 SG_ 2589283612 WLC2_Objekt_erkannt 5000;
BA_REL_ "GenSigTimeoutTime" BU_SG_REL_ ZR_Standard SG_ 2589283612 WLC2_Objekt_erkannt 5000;
BA_REL_ "GenSigTimeoutTime" BU_SG_REL_ ZR_High SG_ 2589283612 WLC2_Receiver_erkannt 5000;
BA_REL_ "GenSigTimeoutTime" BU_SG_REL_ ZR_High_Korea SG_ 2589283612 WLC2_Receiver_erkannt 5000;
BA_REL_ "GenSigTimeoutTime" BU_SG_REL_ ZR_MIB_OPTION_ab_Gen3 SG_ 2589283612 WLC2_Receiver_erkannt 5000;
BA_REL_ "GenSigTimeoutTime" BU_SG_REL_ ZR_MIB_TOP_ab_Gen3 SG_ 2589283612 WLC2_Receiver_erkannt 5000;
BA_REL_ "GenSigTimeoutTime" BU_SG_REL_ ZR_Standard SG_ 2589283612 WLC2_Receiver_erkannt 5000;
BA_REL_ "GenSigTimeoutTime" BU_SG_REL_ ZR_High SG_ 2589283612 WLC2_Receiver_voll_geladen 5000;
BA_REL_ "GenSigTimeoutTime" BU_SG_REL_ ZR_High_Korea SG_ 2589283612 WLC2_Receiver_voll_geladen 5000;
BA_REL_ "GenSigTimeoutTime" BU_SG_REL_ ZR_MIB_OPTION_ab_Gen3 SG_ 2589283612 WLC2_Receiver_voll_geladen 5000;
BA_REL_ "GenSigTimeoutTime" BU_SG_REL_ ZR_MIB_TOP_ab_Gen3 SG_ 2589283612 WLC2_Receiver_voll_geladen 5000;
BA_REL_ "GenSigTimeoutTime" BU_SG_REL_ ZR_Standard SG_ 2589283612 WLC2_Receiver_voll_geladen 5000;
BA_REL_ "GenSigTimeoutTime" BU_SG_REL_ ZR_High SG_ 2589283612 WLC2_verwendeter_Ladestandard 5000;
BA_REL_ "GenSigTimeoutTime" BU_SG_REL_ ZR_High_Korea SG_ 2589283612 WLC2_verwendeter_Ladestandard 5000;
BA_REL_ "GenSigTimeoutTime" BU_SG_REL_ ZR_MIB_OPTION_ab_Gen3 SG_ 2589283612 WLC2_verwendeter_Ladestandard 5000;
BA_REL_ "GenSigTimeoutTime" BU_SG_REL_ ZR_MIB_TOP_ab_Gen3 SG_ 2589283612 WLC2_verwendeter_Ladestandard 5000;
BA_REL_ "GenSigTimeoutTime" BU_SG_REL_ ZR_Standard SG_ 2589283612 WLC2_verwendeter_Ladestandard 5000;
BA_REL_ "GenSigTimeoutTime" BU_SG_REL_ ZR_High SG_ 2589283612 WLC2_Temp_Leistungsteil_Charger 5000;
BA_REL_ "GenSigTimeoutTime" BU_SG_REL_ ZR_High_Korea SG_ 2589283612 WLC2_Temp_Leistungsteil_Charger 5000;
BA_REL_ "GenSigTimeoutTime" BU_SG_REL_ ZR_MIB_OPTION_ab_Gen3 SG_ 2589283612 WLC2_Temp_Leistungsteil_Charger 5000;
BA_REL_ "GenSigTimeoutTime" BU_SG_REL_ ZR_MIB_TOP_ab_Gen3 SG_ 2589283612 WLC2_Temp_Leistungsteil_Charger 5000;
BA_REL_ "GenSigTimeoutTime" BU_SG_REL_ ZR_Standard SG_ 2589283612 WLC2_Temp_Leistungsteil_Charger 5000;
BA_REL_ "GenSigTimeoutTime" BU_SG_REL_ ZR_High SG_ 2589283612 WLC2_Temp_Oberfaeche_Charger 5000;
BA_REL_ "GenSigTimeoutTime" BU_SG_REL_ ZR_High_Korea SG_ 2589283612 WLC2_Temp_Oberfaeche_Charger 5000;
BA_REL_ "GenSigTimeoutTime" BU_SG_REL_ ZR_MIB_OPTION_ab_Gen3 SG_ 2589283612 WLC2_Temp_Oberfaeche_Charger 5000;
BA_REL_ "GenSigTimeoutTime" BU_SG_REL_ ZR_MIB_TOP_ab_Gen3 SG_ 2589283612 WLC2_Temp_Oberfaeche_Charger 5000;
BA_REL_ "GenSigTimeoutTime" BU_SG_REL_ ZR_Standard SG_ 2589283612 WLC2_Temp_Oberfaeche_Charger 5000;
BA_REL_ "GenSigTimeoutTime" BU_SG_REL_ ZR_High SG_ 2589283612 WLC2_Temp_Receiver 5000;
BA_REL_ "GenSigTimeoutTime" BU_SG_REL_ ZR_High_Korea SG_ 2589283612 WLC2_Temp_Receiver 5000;
BA_REL_ "GenSigTimeoutTime" BU_SG_REL_ ZR_MIB_OPTION_ab_Gen3 SG_ 2589283612 WLC2_Temp_Receiver 5000;
BA_REL_ "GenSigTimeoutTime" BU_SG_REL_ ZR_MIB_TOP_ab_Gen3 SG_ 2589283612 WLC2_Temp_Receiver 5000;
BA_REL_ "GenSigTimeoutTime" BU_SG_REL_ ZR_Standard SG_ 2589283612 WLC2_Temp_Receiver 5000;
BA_REL_ "GenSigTimeoutTime" BU_SG_REL_ ABT_1_MIB_ab_Gen3 SG_ 1140 ZR_State_DU_1 5000;
BA_REL_ "GenSigTimeoutTime" BU_SG_REL_ ABT_1_MQB SG_ 1140 ZR_State_DU_1 5000;
BA_REL_ "GenSigTimeoutTime" BU_SG_REL_ BT_1_MQB SG_ 1140 ZR_State_DU_1 5000;
BA_REL_ "GenSigTimeoutTime" BU_SG_REL_ DU_1_MQB SG_ 1140 ZR_State_DU_1 5000;
BA_REL_ "GenSigTimeoutTime" BU_SG_REL_ DU_2 SG_ 1140 ZR_State_DU_2 5000;
BA_REL_ "GenSigTimeoutTime" BU_SG_REL_ DU_3 SG_ 1140 ZR_State_DU_3 5000;
BA_REL_ "GenSigTimeoutTime" BU_SG_REL_ ABT_1_MIB_ab_Gen3 SG_ 1140 ZR_WecktGesp 5000;
BA_REL_ "GenSigTimeoutTime" BU_SG_REL_ ABT_1_MQB SG_ 1140 ZR_WecktGesp 5000;
BA_REL_ "GenSigTimeoutTime" BU_SG_REL_ BT_1_MQB SG_ 1140 ZR_WecktGesp 5000;
BA_REL_ "GenSigTimeoutTime" BU_SG_REL_ DU_1_MQB SG_ 1140 ZR_WecktGesp 5000;
BA_REL_ "GenSigTimeoutTime" BU_SG_REL_ DU_2 SG_ 1140 ZR_WecktGesp 5000;
BA_REL_ "GenSigTimeoutTime" BU_SG_REL_ DU_3 SG_ 1140 ZR_WecktGesp 5000;
BA_REL_ "GenSigTimeoutTime" BU_SG_REL_ DU_4 SG_ 1140 ZR_WecktGesp 5000;
BA_REL_ "GenSigTimeoutTime" BU_SG_REL_ LSR_1 SG_ 1140 ZR_WecktGesp 5000;
BA_REL_ "GenSigTimeoutTime" BU_SG_REL_ ABT_1_MIB_ab_Gen3 SG_ 1140 MMI_State 5000;
BA_REL_ "GenSigTimeoutTime" BU_SG_REL_ ABT_1_MQB SG_ 1140 MMI_State 5000;
BA_REL_ "GenSigTimeoutTime" BU_SG_REL_ BT_1_MQB SG_ 1140 MMI_State 5000;
BA_REL_ "GenSigTimeoutTime" BU_SG_REL_ DU_3 SG_ 1140 MMI_State 5000;
BA_REL_ "GenSigTimeoutTime" BU_SG_REL_ DU_4 SG_ 1140 MMI_State 5000;
BA_REL_ "GenSigTimeoutTime" BU_SG_REL_ ExBox SG_ 1140 MMI_State 5000;
BA_REL_ "GenSigTimeoutTime" BU_SG_REL_ Kombi_TT3 SG_ 1140 MMI_State 5000;
BA_REL_ "GenSigTimeoutTime" BU_SG_REL_ SCC1 SG_ 1140 MMI_State 5000;
BA_REL_ "GenSigTimeoutTime" BU_SG_REL_ SCC2 SG_ 1140 MMI_State 5000;
BA_REL_ "GenSigTimeoutTime" BU_SG_REL_ SDC1 SG_ 1140 MMI_State 5000;
BA_REL_ "GenSigTimeoutTime" BU_SG_REL_ SDC2 SG_ 1140 MMI_State 5000;
BA_REL_ "GenSigTimeoutTime" BU_SG_REL_ SFA SG_ 1140 MMI_State 5000;
BA_REL_ "GenSigTimeoutTime" BU_SG_REL_ WLC_01 SG_ 1140 MMI_State 5000;
BA_REL_ "GenSigTimeoutTime" BU_SG_REL_ ABT_1_MIB_ab_Gen3 SG_ 1140 ZR_DimOffs_DU_1 5000;
BA_REL_ "GenSigTimeoutTime" BU_SG_REL_ ABT_1_MQB SG_ 1140 ZR_DimOffs_DU_1 5000;
BA_REL_ "GenSigTimeoutTime" BU_SG_REL_ DU_1_MQB SG_ 1140 ZR_DimOffs_DU_1 5000;
BA_REL_ "GenSigTimeoutTime" BU_SG_REL_ DU_2 SG_ 1140 ZR_DimOffs_DU_2 5000;
BA_REL_ "GenSigTimeoutTime" BU_SG_REL_ DU_3 SG_ 1140 ZR_DimOffs_DU_3 5000;
BA_REL_ "GenSigTimeoutTime" BU_SG_REL_ ABT_1_MIB_ab_Gen3 SG_ 1140 SI_ICAN 5000;
BA_REL_ "GenSigTimeoutTime" BU_SG_REL_ ABT_1_MQB SG_ 1140 SI_ICAN 5000;
BA_REL_ "GenSigTimeoutTime" BU_SG_REL_ BT_1_MQB SG_ 1140 SI_ICAN 5000;
BA_REL_ "GenSigTimeoutTime" BU_SG_REL_ DU_1_MQB SG_ 1140 SI_ICAN 5000;
BA_REL_ "GenSigTimeoutTime" BU_SG_REL_ DU_2 SG_ 1140 SI_ICAN 5000;
BA_REL_ "GenSigTimeoutTime" BU_SG_REL_ DU_3 SG_ 1140 SI_ICAN 5000;
BA_REL_ "GenSigTimeoutTime" BU_SG_REL_ DU_4 SG_ 1140 SI_ICAN 5000;
BA_REL_ "GenSigTimeoutTime" BU_SG_REL_ ExBox SG_ 1140 SI_ICAN 5000;
BA_REL_ "GenSigTimeoutTime" BU_SG_REL_ LSR_1 SG_ 1140 SI_ICAN 5000;
BA_REL_ "GenSigTimeoutTime" BU_SG_REL_ SCC1 SG_ 1140 SI_ICAN 5000;
BA_REL_ "GenSigTimeoutTime" BU_SG_REL_ SCC2 SG_ 1140 SI_ICAN 5000;
BA_REL_ "GenSigTimeoutTime" BU_SG_REL_ SDC1 SG_ 1140 SI_ICAN 5000;
BA_REL_ "GenSigTimeoutTime" BU_SG_REL_ SDC2 SG_ 1140 SI_ICAN 5000;
BA_REL_ "GenSigTimeoutTime" BU_SG_REL_ ABT_1_MIB_ab_Gen3 SG_ 1140 ZR_Lenkerposition 5000;
BA_REL_ "GenSigTimeoutTime" BU_SG_REL_ ABT_1_MQB SG_ 1140 ZR_Lenkerposition 5000;
BA_REL_ "GenSigTimeoutTime" BU_SG_REL_ BT_1_MQB SG_ 1140 ZR_Lenkerposition 5000;
BA_REL_ "GenSigTimeoutTime" BU_SG_REL_ DU_3 SG_ 1140 ZR_Lenkerposition 5000;
BA_REL_ "GenSigTimeoutTime" BU_SG_REL_ WLC_01 SG_ 1140 WLC1_Systemzustand 5000;
BA_REL_ "GenSigTimeoutTime" BU_SG_REL_ WLC_02 SG_ 1140 WLC2_Systemzustand 5000;
BA_REL_ "GenSigTimeoutTime" BU_SG_REL_ DU_4 SG_ 1140 ZR_State_DU_4 5000;
BA_REL_ "GenSigTimeoutTime" BU_SG_REL_ DU_4 SG_ 1140 ZR_DimOffs_DU_4 5000;
BA_REL_ "GenSigTimeoutTime" BU_SG_REL_ SCC1 SG_ 2589283603 ZV_verriegelt_extern_soll_alt 5000;
BA_REL_ "GenSigTimeoutTime" BU_SG_REL_ SCC2 SG_ 2589283603 ZV_verriegelt_extern_soll_alt 5000;
BA_REL_ "GenSigTimeoutTime" BU_SG_REL_ SDC1 SG_ 2589283603 ZV_verriegelt_extern_soll_alt 5000;
BA_REL_ "GenSigTimeoutTime" BU_SG_REL_ SDC2 SG_ 2589283603 ZV_verriegelt_extern_soll_alt 5000;
BA_REL_ "GenSigTimeoutTime" BU_SG_REL_ WLC_01 SG_ 2589283603 Kessy_12_alt 5000;
BA_REL_ "GenSigTimeoutTime" BU_SG_REL_ WLC_02 SG_ 2589283603 Kessy_12_alt 5000;
BA_REL_ "GenSigTimeoutTime" BU_SG_REL_ SCC1 SG_ 2589283603 ESP_v_Signal_alt 5000;
BA_REL_ "GenSigTimeoutTime" BU_SG_REL_ SCC2 SG_ 2589283603 ESP_v_Signal_alt 5000;
BA_REL_ "GenSigTimeoutTime" BU_SG_REL_ SDC1 SG_ 2589283603 ESP_v_Signal_alt 5000;
BA_REL_ "GenSigTimeoutTime" BU_SG_REL_ SDC2 SG_ 2589283603 ESP_v_Signal_alt 5000;
BA_REL_ "GenSigTimeoutTime" BU_SG_REL_ SCC1 SG_ 2589283603 MO_Drehzahl_alt 5000;
BA_REL_ "GenSigTimeoutTime" BU_SG_REL_ SCC2 SG_ 2589283603 MO_Drehzahl_alt 5000;
BA_REL_ "GenSigTimeoutTime" BU_SG_REL_ SDC1 SG_ 2589283603 MO_Drehzahl_alt 5000;
BA_REL_ "GenSigTimeoutTime" BU_SG_REL_ SDC2 SG_ 2589283603 MO_Drehzahl_alt 5000;
BA_REL_ "GenSigTimeoutTime" BU_SG_REL_ SCC1 SG_ 2589283603 ESP_v_Signal 5000;
BA_REL_ "GenSigTimeoutTime" BU_SG_REL_ SCC2 SG_ 2589283603 ESP_v_Signal 5000;
BA_REL_ "GenSigTimeoutTime" BU_SG_REL_ SDC1 SG_ 2589283603 ESP_v_Signal 5000;
BA_REL_ "GenSigTimeoutTime" BU_SG_REL_ SDC2 SG_ 2589283603 ESP_v_Signal 5000;
BA_REL_ "GenSigTimeoutTime" BU_SG_REL_ WLC_01 SG_ 2589283603 ESP_v_Signal 5000;
BA_REL_ "GenSigTimeoutTime" BU_SG_REL_ SCC1 SG_ 2589283603 MO_Drehzahl_01 5000;
BA_REL_ "GenSigTimeoutTime" BU_SG_REL_ SCC2 SG_ 2589283603 MO_Drehzahl_01 5000;
BA_REL_ "GenSigTimeoutTime" BU_SG_REL_ SDC1 SG_ 2589283603 MO_Drehzahl_01 5000;
BA_REL_ "GenSigTimeoutTime" BU_SG_REL_ SDC2 SG_ 2589283603 MO_Drehzahl_01 5000;
BA_REL_ "GenSigTimeoutTime" BU_SG_REL_ WLC_01 SG_ 2589283603 KY_LF_Aktiv 5000;
BA_REL_ "GenSigTimeoutTime" BU_SG_REL_ WLC_02 SG_ 2589283603 KY_LF_Aktiv 5000;
BA_REL_ "GenSigTimeoutTime" BU_SG_REL_ SCC1 SG_ 2589283603 ZV_verriegelt_extern_soll 5000;
BA_REL_ "GenSigTimeoutTime" BU_SG_REL_ SCC2 SG_ 2589283603 ZV_verriegelt_extern_soll 5000;
BA_REL_ "GenSigTimeoutTime" BU_SG_REL_ SDC1 SG_ 2589283603 ZV_verriegelt_extern_soll 5000;
BA_REL_ "GenSigTimeoutTime" BU_SG_REL_ SDC2 SG_ 2589283603 ZV_verriegelt_extern_soll 5000;
VAL_ 2600468650 NM_SCC1_SNI 170 "SCC1" ;
VAL_ 2600468650 NM_SCC1_CBV_AWB 0 "Passiver_WakeUp" 1 "Aktiver_WakeUp" ;
VAL_ 2600468650 NM_SCC1_CBV_CRI 0 "Standard_Layout" 1 "TNB_Layout" ;
VAL_ 2600468650 NM_SCC1_NM_State 0 "Init" 1 "NM_RM_aus_BSM" 2 "NM_RM_aus_PBSM" 4 "NM_NO_aus_RM" 8 "NM_NO_aus_RS" 16 "NM_RM_aus_RS" 32 "NM_RM_aus_NO" ;
VAL_ 2600468650 NM_SCC1_Car_Wakeup 0 "Inaktiv" 1 "Car_Wakeup" ;
VAL_ 2600468650 NM_SCC1_UDS_CC 0 "Init" 1 "CC_aktiv" ;
VAL_ 2600468650 NM_SCC1_NM_aktiv_KL15 0 "Inaktiv" 1 "KL15_EIN" ;
VAL_ 2600468650 NM_SCC1_NM_aktiv_Diagnose 0 "Init" 1 "Diagnose_aktiv" ;
VAL_ 2600468650 NM_SCC1_NM_aktiv_Tmin 0 "Inaktiv" 1 "Mindestaktivzeit" ;
VAL_ 2600468650 NM_SCC1_NM_aktiv_MIBCAN 0 "MIB_CAN_inaktiv" 1 "MIB_CAN_aktiv" ;
VAL_ 2600468650 NM_SCC1_CAB 0 "inaktiv" 1 "CAB_01__Tueren" 2 "CAB_02__Anhaenger" 4 "CAB_03__Nightvision" 8 "CAB_04__Sitzverstellung" 16 "CAB_05__Klappen" 32 "CAB_06__Infotainment" 64 "CAB_07__Sub_Infotainment" 128 "CAB_08__Anzeige" 256 "CAB_09__Laden" 512 "CAB_10__Klima" 1024 "CAB_11__FlexRay" 2097152 "CAB_22_VLAN_Connect" 4194304 "CAB_23_VLAN_Infotainment" 8388608 "CAB_24_VLAN_FAS" ;
VAL_ 2600468651 NM_SCC2_SNI 170 "SCC1" ;
VAL_ 2600468651 NM_SCC2_CBV_AWB 0 "Passiver_WakeUp" 1 "Aktiver_WakeUp" ;
VAL_ 2600468651 NM_SCC2_CBV_CRI 0 "Standard_Layout" 1 "TNB_Layout" ;
VAL_ 2600468651 NM_SCC2_NM_State 0 "Init" 1 "NM_RM_aus_BSM" 2 "NM_RM_aus_PBSM" 4 "NM_NO_aus_RM" 8 "NM_NO_aus_RS" 16 "NM_RM_aus_RS" 32 "NM_RM_aus_NO" ;
VAL_ 2600468651 NM_SCC2_Car_Wakeup 0 "Inaktiv" 1 "Car_Wakeup" ;
VAL_ 2600468651 NM_SCC2_UDS_CC 0 "Init" 1 "CC_aktiv" ;
VAL_ 2600468651 NM_SCC2_NM_aktiv_KL15 0 "Inaktiv" 1 "KL15_EIN" ;
VAL_ 2600468651 NM_SCC2_NM_aktiv_Diagnose 0 "Init" 1 "Diagnose_aktiv" ;
VAL_ 2600468651 NM_SCC2_NM_aktiv_Tmin 0 "Inaktiv" 1 "Mindestaktivzeit" ;
VAL_ 2600468651 NM_SCC2_NM_aktiv_MIBCAN 0 "MIB_CAN_inaktiv" 1 "MIB_CAN_aktiv" ;
VAL_ 2600468651 NM_SCC2_CAB 0 "inaktiv" 1 "CAB_01__Tueren" 2 "CAB_02__Anhaenger" 4 "CAB_03__Nightvision" 8 "CAB_04__Sitzverstellung" 16 "CAB_05__Klappen" 32 "CAB_06__Infotainment" 64 "CAB_07__Sub_Infotainment" 128 "CAB_08__Anzeige" 256 "CAB_09__Laden" 512 "CAB_10__Klima" 1024 "CAB_11__FlexRay" 2097152 "CAB_22_VLAN_Connect" 4194304 "CAB_23_VLAN_Infotainment" 8388608 "CAB_24_VLAN_FAS" ;
VAL_ 2600468647 NM_SDC1_SNI 167 "SDC1" ;
VAL_ 2600468647 NM_SDC1_CBV_AWB 0 "Passiver_WakeUp" 1 "Aktiver_WakeUp" ;
VAL_ 2600468647 NM_SDC1_CBV_CRI 0 "Standard_Layout" 1 "TNB_Layout" ;
VAL_ 2600468647 NM_SDC1_NM_State 0 "Init" 1 "NM_RM_aus_BSM" 2 "NM_RM_aus_PBSM" 4 "NM_NO_aus_RM" 8 "NM_NO_aus_RS" 16 "NM_RM_aus_RS" 32 "NM_RM_aus_NO" ;
VAL_ 2600468647 NM_SDC1_Car_Wakeup 0 "Inaktiv" 1 "Car_Wakeup" ;
VAL_ 2600468647 NM_SDC1_UDS_CC 0 "Init" 1 "CC_aktiv" ;
VAL_ 2600468647 NM_SDC1_NM_aktiv_KL15 0 "Inaktiv" 1 "KL15_EIN" ;
VAL_ 2600468647 NM_SDC1_NM_aktiv_Diagnose 0 "Init" 1 "Diagnose_aktiv" ;
VAL_ 2600468647 NM_SDC1_NM_aktiv_Tmin 0 "Inaktiv" 1 "Mindestaktivzeit" ;
VAL_ 2600468647 NM_SDC1_NM_aktiv_MIBCAN 0 "MIB_CAN_inaktiv" 1 "MIB_CAN_aktiv" ;
VAL_ 2600468647 NM_SDC1_CAB 0 "inaktiv" 1 "CAB_01__Tueren" 2 "CAB_02__Anhaenger" 4 "CAB_03__Nightvision" 8 "CAB_04__Sitzverstellung" 16 "CAB_05__Klappen" 32 "CAB_06__Infotainment" 64 "CAB_07__Sub_Infotainment" 128 "CAB_08__Anzeige" 256 "CAB_09__Laden" 512 "CAB_10__Klima" 1024 "CAB_11__FlexRay" 2097152 "CAB_22_VLAN_Connect" 4194304 "CAB_23_VLAN_Infotainment" 8388608 "CAB_24_VLAN_FAS" ;
VAL_ 2600468648 NM_SDC2_SNI 168 "SDC2" ;
VAL_ 2600468648 NM_SDC2_CBV_AWB 0 "Passiver_WakeUp" 1 "Aktiver_WakeUp" ;
VAL_ 2600468648 NM_SDC2_CBV_CRI 0 "Standard_Layout" 1 "TNB_Layout" ;
VAL_ 2600468648 NM_SDC2_NM_State 0 "Init" 1 "NM_RM_aus_BSM" 2 "NM_RM_aus_PBSM" 4 "NM_NO_aus_RM" 8 "NM_NO_aus_RS" 16 "NM_RM_aus_RS" 32 "NM_RM_aus_NO" ;
VAL_ 2600468648 NM_SDC2_Car_Wakeup 0 "Inaktiv" 1 "Car_Wakeup" ;
VAL_ 2600468648 NM_SDC2_UDS_CC 0 "Init" 1 "CC_aktiv" ;
VAL_ 2600468648 NM_SDC2_NM_aktiv_KL15 0 "Inaktiv" 1 "KL15_EIN" ;
VAL_ 2600468648 NM_SDC2_NM_aktiv_Diagnose 0 "Init" 1 "Diagnose_aktiv" ;
VAL_ 2600468648 NM_SDC2_NM_aktiv_Tmin 0 "Inaktiv" 1 "Mindestaktivzeit" ;
VAL_ 2600468648 NM_SDC2_NM_aktiv_MIBCAN 0 "MIB_CAN_inaktiv" 1 "MIB_CAN_aktiv" ;
VAL_ 2600468648 NM_SDC2_CAB 0 "inaktiv" 1 "CAB_01__Tueren" 2 "CAB_02__Anhaenger" 4 "CAB_03__Nightvision" 8 "CAB_04__Sitzverstellung" 16 "CAB_05__Klappen" 32 "CAB_06__Infotainment" 64 "CAB_07__Sub_Infotainment" 128 "CAB_08__Anzeige" 256 "CAB_09__Laden" 512 "CAB_10__Klima" 1024 "CAB_11__FlexRay" 2097152 "CAB_22_VLAN_Connect" 4194304 "CAB_23_VLAN_Infotainment" 8388608 "CAB_24_VLAN_FAS" ;
VAL_ 2600468527 NM_SFA_SNI 47 "" ;
VAL_ 2600468527 NM_SFA_NM_State 0 "Init" 1 "NM_RM_aus_BSM" 2 "NM_RM_aus_PBSM" 4 "NM_NO_aus_RM" 8 "NM_NO_aus_RS" 16 "NM_RM_aus_RS" 32 "NM_RM_aus_NO" ;
VAL_ 2600468527 NM_SFA_Car_Wakeup 0 "Inaktiv" 1 "Car_Wakeup" ;
VAL_ 2600468527 NM_SFA_Wakeup 0 "Peripherie_Wakeup__Ursache_nicht_bekannt" 1 "Bus_Wakeup" 2 "KL15_HW" 3 "Hardkey" ;
VAL_ 2600468527 NM_SFA_NM_aktiv_KL15 0 "Inaktiv" 1 "KL15_EIN" ;
VAL_ 2600468527 NM_SFA_NM_aktiv_Diagnose 0 "Init" 1 "Diagnose_aktiv" ;
VAL_ 2600468527 NM_SFA_NM_aktiv_Tmin 0 "Inaktiv" 1 "Mindestaktivzeit" ;
VAL_ 2600468527 NM_SFA_UDS_CC 0 "Init" 1 "CC_aktiv" ;
VAL_ 2600468645 NM_WLC1_SNI 165 "WLC1" ;
VAL_ 2600468645 NM_WLC1_CBV_AWB 0 "Passiver_WakeUp" 1 "Aktiver_WakeUp" ;
VAL_ 2600468645 NM_WLC1_CBV_CRI 0 "Standard_Layout" 1 "TNB_Layout" ;
VAL_ 2600468645 NM_WLC1_NM_State 0 "Init" 1 "NM_RM_aus_BSM" 2 "NM_RM_aus_PBSM" 4 "NM_NO_aus_RM" 8 "NM_NO_aus_RS" 16 "NM_RM_aus_RS" 32 "NM_RM_aus_NO" ;
VAL_ 2600468645 NM_WLC1_Car_Wakeup 0 "Inaktiv" 1 "Car_Wakeup" ;
VAL_ 2600468645 NM_WLC1_UDS_CC 0 "Init" 1 "CC_aktiv" ;
VAL_ 2600468645 NM_WLC1_NM_aktiv_KL15 0 "Inaktiv" 1 "KL15_EIN" ;
VAL_ 2600468645 NM_WLC1_aktiv_Diagnose 0 "Init" 1 "Diagnose_aktiv" ;
VAL_ 2600468645 NM_WLC1_aktiv_Tmin 0 "Inaktiv" 1 "Mindestaktivzeit" ;
VAL_ 2600468645 NM_WLC1_NM_aktiv_MIBCAN 0 "MIB_CAN_inaktiv" 1 "MIB_CAN_aktiv" ;
VAL_ 2600468645 NM_WLC1_CAB 0 "inaktiv" 1 "CAB_01__Tueren" 2 "CAB_02__Anhaenger_KCAN" 4 "CAB_03__Nightvision" 8 "CAB_04__Sitzverstellung" 16 "CAB_05__Klappen" 32 "CAB_06__Infotainment" 64 "CAB_07__Sub_Infotainment" 128 "CAB_08__Anzeige" 256 "CAB_09__Laden_HCAN" 512 "CAB_10__Klima" 1024 "CAB_11__FlexRay" 262144 "CAB_19__VLAN_RemoteFC" 524288 "CAB_20__VLAN_Komfort" 1048576 "CAB_21__VLAN_Internet" 2097152 "CAB_22__VLAN_Connect" 4194304 "CAB_23__VLAN_Infotainment" 8388608 "CAB_24__VLAN_FAS" ;
VAL_ 2600468646 NM_WLC2_SNI 166 "WLC2" ;
VAL_ 2600468646 NM_WLC2_CBV_AWB 0 "Passiver_WakeUp" 1 "Aktiver_WakeUp" ;
VAL_ 2600468646 NM_WLC2_CBV_CRI 0 "Standard_Layout" 1 "TNB_Layout" ;
VAL_ 2600468646 NM_WLC2_NM_State 0 "Init" 1 "NM_RM_aus_BSM" 2 "NM_RM_aus_PBSM" 4 "NM_NO_aus_RM" 8 "NM_NO_aus_RS" 16 "NM_RM_aus_RS" 32 "NM_RM_aus_NO" ;
VAL_ 2600468646 NM_WLC2_Car_Wakeup 0 "Inaktiv" 1 "Car_Wakeup" ;
VAL_ 2600468646 NM_WLC2_UDS_CC 0 "Init" 1 "CC_aktiv" ;
VAL_ 2600468646 NM_WLC2_NM_aktiv_KL15 0 "Inaktiv" 1 "KL15_EIN" ;
VAL_ 2600468646 NM_WLC2_aktiv_Diagnose 0 "Init" 1 "Diagnose_aktiv" ;
VAL_ 2600468646 NM_WLC2_aktiv_Tmin 0 "Inaktiv" 1 "Mindestaktivzeit" ;
VAL_ 2600468646 NM_WLC2_NM_aktiv_MIBCAN 0 "MIB_CAN_inaktiv" 1 "MIB_CAN_aktiv" ;
VAL_ 2600468646 NM_WLC2_CAB 0 "inaktiv" 1 "CAB_01__Tueren" 2 "CAB_02__Anhaenger_KCAN" 4 "CAB_03__Nightvision" 8 "CAB_04__Sitzverstellung" 16 "CAB_05__Klappen" 32 "CAB_06__Infotainment" 64 "CAB_07__Sub_Infotainment" 128 "CAB_08__Anzeige" 256 "CAB_09__Laden_HCAN" 512 "CAB_10__Klima" 1024 "CAB_11__FlexRay" 262144 "CAB_19__VLAN_RemoteFC" 524288 "CAB_20__VLAN_Komfort" 1048576 "CAB_21__VLAN_Internet" 2097152 "CAB_22__VLAN_Connect" 4194304 "CAB_23__VLAN_Infotainment" 8388608 "CAB_24__VLAN_FAS" ;
VAL_ 2589283656 ORU_Warnung 0 "keine_Anzeige" 1 "Update_unvollstaendig_Prio1" 2 "Update_fehlgeschlagen_Prio1" 3 "reserviert" ;
VAL_ 2589283656 ORU_Status 0 "IDLE" 1 "PENDING" 2 "PREPARATION" 3 "PREPARATION_HV" 4 "RUNNING" 5 "RUNNING_HV" 6 "PENDING_NOTREADY" ;
VAL_ 1616 RA_Frequency_unit 0 "1_kHz" 1 "100_kHz" ;
VAL_ 1616 RA_AM_Tuning 0 "frequency_locked" 1 "AM_tuning" ;
VAL_ 1350 MMI_on_angefordert 0 "inaktiv" 1 "aktiv" ;
VAL_ 2589283480 SDC1_Variante 0 "Nothing_detected" 1 "AOZ" 2 "SDIS1" ;
VAL_ 2589283480 SDC1_Powerstate 0 "SDC_OFF" 1 "SDC_ONLY" 2 "SDC_STANDBY" 3 "SDC_ON" 4 "SDC_ON_DELAY" 5 "SDC_ON_SWDL" 6 "SDC_SDIS_SHUTDOWN" 7 "SDC_FAST_SHUTDOWN" ;
VAL_ 2589283480 SDC1_Q_Critical 0 "no" 1 "yes" ;
VAL_ 2589283480 SDC1_LastOn 0 "false" 1 "true" 2 "not_used" 3 "roller_rig_mode" ;
VAL_ 2589283480 SDC1_SystemMode 0 "Bootloader" 1 "Applikation" ;
VAL_ 2589283480 SDC1_KL_30F 254 "Init" 255 "Fehler" ;
VAL_ 2589283480 SDC1_TempSens 254 "Init" 255 "Fehler" ;
VAL_ 2589283480 SDC1_TempSensMax 254 "Init" 255 "Fehler" ;
VAL_ 2589283482 SDC2_Variante 0 "Nothing_detected" 1 "AOZ" 2 "SDIS1" ;
VAL_ 2589283482 SDC2_Powerstate 0 "SDC_OFF" 1 "SDC_ONLY" 2 "SDC_STANDBY" 3 "SDC_ON" 4 "SDC_ON_DELAY" 5 "SDC_ON_SWDL" 6 "SDC_SDIS_SHUTDOWN" 7 "SDC_FAST_SHUTDOWN" ;
VAL_ 2589283482 SDC2_Q_Critical 0 "no" 1 "yes" ;
VAL_ 2589283482 SDC2_LastOn 0 "false" 1 "true" 2 "not_used" 3 "roller_rig_mode" ;
VAL_ 2589283482 SDC2_SystemMode 0 "Bootloader" 1 "Applikation" ;
VAL_ 2589283482 SDC2_KL_30F 254 "Init" 255 "Fehler" ;
VAL_ 2589283482 SDC2_TempSens 254 "Init" 255 "Fehler" ;
VAL_ 2589283482 SDC2_TempSensMax 254 "Init" 255 "Fehler" ;
VAL_ 2589283486 SCC_State 0 "SCON_Off" 1 "SCON_On" 2 "Low_Pow" ;
VAL_ 2589283486 SystemMode 0 "Bootloader" 1 "Applikation" ;
VAL_ 2589283486 SCC_Temp_Fehler 0 "normal" 1 "Fehler" ;
VAL_ 2589283486 SCC_KL30_Uebersp_Fehler 0 "normal" 1 "Fehler" ;
VAL_ 2589283486 SCC_KL30_Untersp_Fehler 0 "normal" 1 "Fehler" ;
VAL_ 2589283486 SCC_KL_30F 254 "Init" 255 "Fehler" ;
VAL_ 2589283486 SCC_TempSens 254 "Init" 255 "Fehler" ;
VAL_ 2589283486 SCC_TempSensMax 254 "Init" 255 "Fehler" ;
VAL_ 2589283486 SCC_Variant 254 "Init" ;
VAL_ 2589283486 SCC1_Powerstate 0 "SCC_OFF" 1 "SCC_ONLY" 2 "SCC_STANDBY" 3 "SCC_ON" 4 "SCC_ON_DELAY" 5 "SCC_ON_SWDL" 6 "SCC_SCON_SHUTDOWN" 7 "SCC_FAST_SHUTDOWN" ;
VAL_ 2589283487 EEPROM_Fehler 0 "normal" 1 "Fehler" ;
VAL_ 2589283488 SCC_State 0 "SCON_Off" 1 "SCON_On" 2 "Low_Pow" ;
VAL_ 2589283488 SystemMode 0 "Bootloader" 1 "Applikation" ;
VAL_ 2589283488 SCC_Temp_Fehler 0 "normal" 1 "Fehler" ;
VAL_ 2589283488 SCC_KL30_Uebersp_Fehler 0 "normal" 1 "Fehler" ;
VAL_ 2589283488 SCC_KL30_Untersp_Fehler 0 "normal" 1 "Fehler" ;
VAL_ 2589283488 SCC_KL_30F 254 "Init" 255 "Fehler" ;
VAL_ 2589283488 SCC_TempSens 254 "Init" 255 "Fehler" ;
VAL_ 2589283488 SCC_TempSensMax 254 "Init" 255 "Fehler" ;
VAL_ 2589283488 SCC_Variant 254 "Init" ;
VAL_ 2589283488 SCC2_Powerstate 0 "SCC_OFF" 1 "SCC_ONLY" 2 "SCC_STANDBY" 3 "SCC_ON" 4 "SCC_ON_DELAY" 5 "SCC_ON_SWDL" 6 "SCC_SCON_SHUTDOWN" ;
VAL_ 2589283489 EEPROM_Fehler 0 "normal" 1 "Fehler" ;
VAL_ 1413 SI_Sammel_SG_Fehler 61 "Reserviert" 62 "Overflow" 63 "ungueltig" ;
VAL_ 1413 SI_P_Mode_gueltig 0 "dezentraler_Produktionsmode" 1 "zentraler_Produktionsmode" ;
VAL_ 1413 SI_Diagnose_Aktiv 0 "inaktiv" 1 "aktiv" ;
VAL_ 1413 SI_QRS_Mode 0 "QRS_Messmodus_nicht_aktiv" 1 "QRS_Messmodus_aktiv" ;
VAL_ 1413 SI_T_Mode 0 "Transportmodus_nicht_aktiv" 1 "Transportmodus_aktiv" ;
VAL_ 1413 SI_NWDF 0 "Ueberwachung_nicht_freigegeben" 1 "Ueberwachung_freigegeben" ;
VAL_ 1413 SI_NWDF_gueltig 0 "NWDF_wird_nicht_unterstuetzt" 1 "NWDF_wird_unterstuetzt" ;
VAL_ 1413 SI_Sammelfehler 0 "kein_Sammelfehler" 1 "Sammelfehler" ;
VAL_ 1413 GW_KD_Fehler 0 "kein_KD_Fehler" 1 "KD_Fehler" ;
VAL_ 1413 SI_T_Schutz 0 "Transportschutz_nicht_aktiv" 1 "Transportschutz_aktiv" ;
VAL_ 1413 SI_P_Mode 0 "inaktiv" 1 "aktiv" ;
VAL_ 1413 SI_BUS_01 0 "keine_Busruhe" 1 "Busruhe" ;
VAL_ 1413 SI_BUS_02 0 "keine_Busruhe" 1 "Busruhe" ;
VAL_ 1413 SI_BUS_03 0 "keine_Busruhe" 1 "Busruhe" ;
VAL_ 1413 SI_BUS_04 0 "keine_Busruhe" 1 "Busruhe" ;
VAL_ 1413 SI_BUS_05 0 "keine_Busruhe" 1 "Busruhe" ;
VAL_ 1413 SI_BUS_06 0 "keine_Busruhe" 1 "Busruhe" ;
VAL_ 1413 SI_BUS_07 0 "keine_Busruhe" 1 "Busruhe" ;
VAL_ 1413 SI_BUS_08 0 "keine_Busruhe" 1 "Busruhe" ;
VAL_ 1413 SI_BUS_09 0 "keine_Busruhe" 1 "Busruhe" ;
VAL_ 1413 SI_BUS_10 0 "keine_Busruhe" 1 "Busruhe" ;
VAL_ 1413 SI_BUS_11 0 "keine_Busruhe" 1 "Busruhe" ;
VAL_ 1413 SI_BUS_12 0 "keine_Busruhe" 1 "Busruhe" ;
VAL_ 1413 SI_BUS_13 0 "keine_Busruhe" 1 "Busruhe" ;
VAL_ 1413 SI_BUS_14 0 "keine_Busruhe" 1 "Busruhe" ;
VAL_ 1413 SI_BUS_15 0 "keine_Busruhe" 1 "Busruhe" ;
VAL_ 1413 SI_Bus_Identifikation 16 "CAN_Diagnose" 17 "CAN_Antrieb" 18 "CAN_Komfort" 19 "CAN_Infotainment" 20 "CAN_Fahrwerk" 21 "CAN_Extended" 22 "CAN_Hybrid" 23 "CAN_Lade" 24 "CAN_Kombi" 25 "CAN_Komfort_2" 26 "CAN_AFS" 33 "CAN_FahrerAssistenzSysteme" 34 "CAN_Migration" 35 "CAN_Connect" 36 "CAN_AnzeigeBedienung" 37 "CAN_ElectricalVehicle" 40 "CAN_Telematik" 41 "CAN_MFL" 48 "FlexRay_A" 49 "FlexRay_B" 97 "VLAN_FAS" 98 "VLAN_Infotainment" 99 "VLAN_Connect" 100 "VLAN_Komfort" 101 "VLAN_Antrieb" 102 "VLAN_Diagnose" 103 "VLAN_Internet" 104 "VLAN_Gateway" 105 "VLAN_Remote_FC" 106 "VLAN_Connect_2" ;
VAL_ 916 WBA_Fahrstufe_02 0 "Zwischenstellung_keine_Position" 1 "Position_P" 2 "Position_R" 3 "Position_N" 4 "Position_D" 5 "Position_S" 6 "Position_M_Tippfunktion" 7 "Kurzzeit_M" 8 "Position_E" 9 "Position_MS" 10 "Position_S_Plus" 11 "Position_MS_Plus" 12 "Position_Offroad" 13 "Position_B" ;
VAL_ 916 WBA_ZielFahrstufe 0 "keine_Gangempfehlung_kein_Gang_eingelegt" 1 "Pfeil_nach_S" 2 "Pfeil_nach_D" 3 "Pfeil_nach_M" 4 "Pfeil_nach_E" ;
VAL_ 916 WBA_GE_Warnung_02 0 "keine_Anzeige" 1 "Fehlereskalationsstufe_I" 2 "Fehlereskalationsstufe_II" 3 "Weiterfahrt_nur_eingeschraenkt_moeglich__Kein_R_Gang" 4 "Getriebefehler_Weiterfahrt_nur_in_D_moeglich__P_bei_Motor_aus" 5 "Wegrollgefahr__P_nicht_moeglich" 6 "Paddlenotbetrieb_Schema+Warnung" 7 "Paddlenotbetrieb_Schema" 8 "Geschwindigkeitsbegrenzung_Notlauf" 9 "Fehlereskalationsst_o_Einschr" 10 "Fehlereskalationsstufe_v_Limit" 11 "Parksperre_Infostufe" 12 "Parksperre_Warnstufe_I" 13 "Parksperre_Warnstufe_II" ;
VAL_ 916 WBA_eing_Gang_02 0 "keine_Ganganzeige" 1 "Gang_1" 2 "Gang_2" 3 "Gang_3" 4 "Gang_4" 5 "Gang_5" 6 "Gang_6" 7 "Gang_7" 8 "Gang_8" 9 "Gang_9" 10 "Funktion_Ganganzeigeunterdrueckung" 11 "Gang_10" ;
VAL_ 916 WBA_GE_Texte 0 "keine_Anzeige" 1 "zum_Einlegen_einer_Fahrstufe_Fussbremse_betaetigen__ShiftLock_Information" 2 "zum_Einlegen_von_R_N_D_Fussbremse_betaetigen_und_Motor_starten" 3 "Wegrollgefahr_bitte_P_einlegen" 4 "Achtung_Zeitueberschreitung_P_wird_eingelegt" 5 "Wiederanmeldeprozedur_Bremse_betaetigen" 6 "P_nur_im_Stillstand_moeglich" 7 "Rennstart_aktiv" ;
VAL_ 916 WBA_Segeln_aktiv 0 "inaktiv" 1 "aktiv" ;
VAL_ 916 WBA_Schaltschema 0 "kein_Schaltschema" 1 "xxxD(S)" 2 "xxxD_S" 3 "xxxS(D)" 4 "xxxS_D" 5 "xxxM(D)" 6 "xxxM_D" 7 "xxxM(S)" 8 "xxxM_S" 9 "xxxE(D)" 10 "xxxE_D" 11 "xxxE(S)" 12 "xxxE_S" 13 "xxxE(M)" 14 "xxxE_M" ;
VAL_ 916 WBA_GE_Zusatzwarnungen 0 "keine_Anzeige" 1 "Getriebeueberhitzung_Warnstufe_I" 2 "Getriebeueberhitzung_Warnstufe_II" 3 "Getriebefehler_Bitte_anhalten_und_P_einlegen" ;
VAL_ 916 GE_Sollgang 0 "keine_Empfehlung" 1 "Gang_1" 2 "Gang_2" 3 "Gang_3" 4 "Gang_4" 5 "Gang_5" 6 "Gang_6" 7 "Gang_7" 8 "Gang_8" 9 "Gang_9" 11 "Gang_10" ;
VAL_ 916 GE_Tipschaltempf_verfuegbar 0 "nicht_verfuegbar" 1 "verfuegbar" ;
VAL_ 916 WBA_GE_Texte_02 0 "Keine_Anzeige" 1 "Fahrtrichtungswechsel_nur_nach_Stillstandt" 2 "Ladestecker_gesteckt" 3 "zusaetzlicher_Service_erforderlich" 4 "eLaunch_Aktiv" 5 "eLaunch_nicht_moeglich" 6 "WH_S_nicht_moeglich_Offroad" 7 "WH_S_nicht_moeglich_RangeMode" ;
VAL_ 916 WBA_Blinken 0 "kein_WBA_Blinken" 1 "WBA_Blinken" ;
VAL_ 916 GE_Wiederstart_Anz_Std 0 "keine_Anzeige" 1 "Standard_Wiederstartgrund" ;
VAL_ 916 GE_Stoppverbot_Anz_01 0 "keine_Anzeige" 1 "Temperaturbedingung" ;
VAL_ 916 GE_Stoppverbot_Anz_02 0 "keine_Anzeige" 1 "Drucksensorausfall" ;
VAL_ 916 GE_Stoppverbot_Anz_03 0 "keine_Anzeige" 1 "Grundeinstellung" ;
VAL_ 916 GE_Stoppverbot_Anz_04 0 "keine_Anzeige" 1 "Demontagestellung" ;
VAL_ 916 GE_Stoppverbot_Anz_05 0 "keine_Anzeige" 1 "Eingeschraenkte_Fahrfunktion_Notlauf_Liegenbleiber" ;
VAL_ 916 GE_Stoppverbot_Anz_06 0 "keine_Anzeige" 1 "Stoppverbot_ueber_Applikation" ;
VAL_ 916 GE_Stoppverbot_Anz_07 0 "keine_Anzeige" 1 "Schaltung_aktiv" ;
VAL_ 916 GE_Stoppverbot_Anz_Std 0 "keine_Anzeige" 1 "Standard_Stoppvetogrund" ;
VAL_ 2589283611 WLC1_Fehler 0 "kein_Fehler" 1 "WLC_Kompensor_Kurzschluss" 2 "WLC_Kompensor_Unterbrechung" 4 "WLC_Antenne_Kurzschluss" 8 "WLC_Antenne_Unterbrechung" 16 "Kompensor_keine_Versorgung" 32 "Kompensor_defekt" 64 "WLC_defekt" ;
VAL_ 2589283611 WLC1_Fremdobjekt_erkannt 0 "no_Foreign_object" 1 "Foreign_object_detected" ;
VAL_ 2589283611 WLC1_Objekt_erkannt 0 "no_Device_in_Tray" 1 "non_WLC_Device_in_Tray" ;
VAL_ 2589283611 WLC1_Receiver_erkannt 0 "no_Device_in_tray" 1 "WLC_Device_in_tray" ;
VAL_ 2589283611 WLC1_Receiver_voll_geladen 0 "WLC_not_fully_charged" 1 "WLC_Device_fully_charged" ;
VAL_ 2589283612 WLC2_Fremdobjekt_erkannt 0 "no_Foreign_object" 1 "Foreign_object_detected" ;
VAL_ 2589283612 WLC2_Objekt_erkannt 0 "no_Device_in_Tray" 1 "non_WLC_Device_in_Tray" ;
VAL_ 2589283612 WLC2_Receiver_erkannt 0 "no_Device_in_tray" 1 "WLC_Device_in_tray" ;
VAL_ 2589283612 WLC2_Receiver_voll_geladen 0 "WLC_not_fully_charged" 1 "WLC_Device_fully_charged" ;
VAL_ 1140 ZR_State_DU_1 0 "Disp_Off" 1 "Disp_On" 2 "LowPow" ;
VAL_ 1140 ZR_State_DU_2 0 "Disp_Off" 1 "Disp_On" 2 "LowPow" ;
VAL_ 1140 ZR_State_DU_3 0 "Disp_Off" 1 "Disp_On" 2 "LowPow" ;
VAL_ 1140 ZR_WecktGesp 0 "entsperrt" 1 "gesperrt" ;
VAL_ 1140 MMI_State 0 "MMI_OFF" 1 "MMI_IOC" 2 "MMI_STDBY" 3 "MMI_ON" 4 "MMI_STDBY_PWR_SAVE" 5 "MMI_STDBY_RESTR" 6 "MMI_ON_DIAG" 7 "MMI_ON_TEL" 8 "MMI_ON_SWDL" 9 "MMI_ON_CUST_SWDL" 10 "MMI_STDBY_PWR_SAVE_1" 11 "MMI_STDBY_PWR_SAVE_2" 12 "MMI_STANDBY_CUST_SWDL" 13 "MMI_ONLINE_IOC" 14 "MMI_ONLINE" 15 "MMI_PHONE_IOC" 16 "MMI_PHONE" 17 "MMI_RTC" 18 "MMI_DCI" ;
VAL_ 1140 ZR_DimOffs_DU_1 14 "Init" ;
VAL_ 1140 ZR_DimOffs_DU_2 14 "Init" ;
VAL_ 1140 ZR_DimOffs_DU_3 14 "Init" ;
VAL_ 1140 SI_ICAN 0 "keine_Busruhe" 1 "Busruhe" ;
VAL_ 1140 ZR_Lenkerposition 0 "links" 1 "rechts" ;
VAL_ 1140 WLC1_Systemzustand 0 "Wireless_Charger_off" 1 "Wireless_Charger_on" ;
VAL_ 1140 WLC2_Systemzustand 0 "Wireless_Charger_off" 1 "Wireless_Charger_on" ;
VAL_ 1140 DI_Screendesign 0 "Automatisch" 1 "Tag" 2 "Nacht" 6 "Init" 7 "Fehler" ;
VAL_ 1140 ZR_State_DU_4 0 "Disp_Off" 1 "Disp_On" 2 "LowPow" ;
VAL_ 1140 ZR_DimOffs_DU_4 14 "Init" ;
VAL_ 2589283603 ZV_verriegelt_extern_soll_alt 0 "aktuell" 1 "veraltet" ;
VAL_ 2589283603 Kessy_12_alt 0 "aktuell" 1 "veraltet" ;
VAL_ 2589283603 ESP_v_Signal_alt 0 "aktuell" 1 "veraltet" ;
VAL_ 2589283603 MO_Drehzahl_alt 0 "aktuell" 1 "veraltet" ;
VAL_ 2589283603 ESP_v_Signal 65533 "Unterspannung" 65534 "Init" 65535 "Fehler" ;
VAL_ 2589283603 KY_LF_Aktiv 0 "Funktempfang_nicht_aktiv" 1 "LF_Funkempfang_aktiv" ;
VAL_ 2589283603 ZV_verriegelt_extern_soll 1 "Fahrzeug verriegelt extern; Sollzusstand" ;
